VERSION ""

NS_ :

BS_:

BU_: ACS CC TCO SSC RD REX VGW TPMS TECU IC EMS EBS
VAL_TABLE_ FMI 31 "ConditionExists" 19 "Received network data in error" 18 "Below normal (moderately severe)" 17 "Below normal (least severe)" 16 "Above normal (moderately severe)" 15 "Above normal (least severe)" 14 "Special intstructions" 13 "Out of calibration" 12 "Bad intelligent device" 11 "Root cause not known" 10 "Abnormal rate of change" 9 "Abnormal update rate" 8 "Abnormal frequency" 7 "Mechanical system not responding" 6 "Current above normal" 5 "Current below normal" 4 "Voltage below normal" 3 "Voltage above normal" 2 "Data erratic" 1 "Below normal (most severe)" 0 "Above normal (most severe)" ;

BO_ 3221225472 VECTOR__INDEPENDENT_SIG_MSG: 0 Vector__XXX
 SG_ TireTemp : 0|16@1+ (0.03125,-273) [-273|1735] "deg" Vector__XXX
 SG_ TirePress : 0|8@1+ (4,0) [0|1000] "kPa" Vector__XXX
 SG_ SPN5 : 0|16@1+ (1,0) [0|65536] "" Vector__XXX
 SG_ SPN4 : 0|16@1+ (1,0) [0|65536] "" Vector__XXX
 SG_ SPN3 : 0|16@1+ (1,0) [0|65536] "" Vector__XXX
 SG_ SPN2 : 0|16@1+ (1,0) [0|65536] "" Vector__XXX
 SG_ FailureModeIdentifier5 : 0|5@1+ (1,0) [0|0] "" Vector__XXX
 SG_ FailureModeIdentifier4 : 0|5@1+ (1,0) [0|0] "" Vector__XXX
 SG_ FlashRedStopLamp : 0|2@1+ (1,0) [0|3] "" Vector__XXX
 SG_ FlashProtectLamp : 0|2@1+ (1,0) [0|3] "" Vector__XXX
 SG_ FlashMalfuncIndicatorLamp : 0|2@1+ (1,0) [0|3] "" Vector__XXX
 SG_ FlashAmberWarningLamp : 0|2@1+ (1,0) [0|3] "" Vector__XXX
 SG_ FailureModeIdentifier3 : 0|5@1+ (1,0) [0|0] "" Vector__XXX
 SG_ FailureModeIdentifier2 : 0|5@1+ (1,0) [0|0] "" Vector__XXX
 SG_ SPNConversionMethod5 : 0|1@1+ (1,0) [0|1] "" Vector__XXX
 SG_ SPNConversionMethod4 : 0|1@1+ (1,0) [0|1] "" Vector__XXX
 SG_ SPNConversionMethod3 : 0|1@1+ (1,0) [0|1] "" Vector__XXX
 SG_ SPNConversionMethod2 : 0|1@1+ (1,0) [0|1] "" Vector__XXX
 SG_ SPNConversionMethod1 : 0|1@1+ (1,0) [0|1] "" Vector__XXX
 SG_ FailureModeIdentifier1 : 0|5@1+ (1,0) [0|0] "" Vector__XXX
 SG_ SPN1 : 0|16@1+ (1,0) [0|65536] "" Vector__XXX
 SG_ MalfunctionIndicatorLampStatus : 0|2@1+ (1,0) [0|3] "" Vector__XXX
 SG_ RedStopLampState : 0|2@1+ (1,0) [0|3] "" Vector__XXX
 SG_ AmberWarningLampStatus : 0|2@1+ (1,0) [0|3] "" Vector__XXX
 SG_ ProtectLampStatus : 0|2@1+ (1,0) [0|3] "" Vector__XXX
 SG_ SPN5High : 0|3@1+ (1,0) [0|7] "" Vector__XXX
 SG_ SPN4High : 0|3@1+ (1,0) [0|7] "" Vector__XXX
 SG_ SPN3High : 0|3@1+ (1,0) [0|7] "" Vector__XXX
 SG_ SPN2High : 0|3@1+ (1,0) [0|7] "" Vector__XXX
 SG_ SPN1High : 0|3@1+ (1,0) [0|7] "" Vector__XXX
 SG_ SPNConversionMethod1 : 0|1@1+ (1,0) [0|1] "" Vector__XXX
 SG_ FailureModeIdentifier1 : 0|5@1+ (1,0) [0|0] "" Vector__XXX
 SG_ SPN1 : 0|16@1+ (1,0) [0|65536] "" Vector__XXX
 SG_ SPN1High : 0|3@1+ (1,0) [0|7] "" Vector__XXX
 SG_ SPNConversionMethod1 : 0|1@1+ (1,0) [0|1] "" Vector__XXX
 SG_ FailureModeIdentifier1 : 0|5@1+ (1,0) [0|0] "" Vector__XXX
 SG_ SPN1 : 0|16@1+ (1,0) [0|65536] "" Vector__XXX
 SG_ SPN1High : 0|3@1+ (1,0) [0|7] "" Vector__XXX
 SG_ SPN5 : 0|16@1+ (1,0) [0|65536] "" Vector__XXX
 SG_ SPN4 : 0|16@1+ (1,0) [0|65536] "" Vector__XXX
 SG_ SPN3 : 0|16@1+ (1,0) [0|65536] "" Vector__XXX
 SG_ SPN2 : 0|16@1+ (1,0) [0|65536] "" Vector__XXX
 SG_ FailureModeIdentifier5 : 0|5@1+ (1,0) [0|0] "" Vector__XXX
 SG_ FailureModeIdentifier4 : 0|5@1+ (1,0) [0|0] "" Vector__XXX
 SG_ SPNConversionMethod1 : 0|1@1+ (1,0) [0|1] "" Vector__XXX
 SG_ FailureModeIdentifier1 : 0|5@1+ (1,0) [0|0] "" Vector__XXX
 SG_ SPN1 : 0|16@1+ (1,0) [0|65536] "" Vector__XXX
 SG_ MalfunctionIndicatorLampStatus : 0|2@1+ (1,0) [0|3] "" Vector__XXX
 SG_ RedStopLampState : 0|2@1+ (1,0) [0|3] "" Vector__XXX
 SG_ AmberWarningLampStatus : 0|2@1+ (1,0) [0|3] "" Vector__XXX
 SG_ ProtectLampStatus : 0|2@1+ (1,0) [0|3] "" Vector__XXX
 SG_ FailureModeIdentifier3 : 0|5@1+ (1,0) [0|0] "" Vector__XXX
 SG_ FlashRedStopLamp : 0|2@1+ (1,0) [0|3] "" Vector__XXX
 SG_ FlashProtectLamp : 0|2@1+ (1,0) [0|3] "" Vector__XXX
 SG_ FlashMalfuncIndicatorLamp : 0|2@1+ (1,0) [0|3] "" Vector__XXX
 SG_ FlashAmberWarningLamp : 0|2@1+ (1,0) [0|3] "" Vector__XXX
 SG_ FailureModeIdentifier2 : 0|5@1+ (1,0) [0|0] "" Vector__XXX
 SG_ SPNConversionMethod5 : 0|1@1+ (1,0) [0|1] "" Vector__XXX
 SG_ SPNConversionMethod4 : 0|1@1+ (1,0) [0|1] "" Vector__XXX
 SG_ SPNConversionMethod3 : 0|1@1+ (1,0) [0|1] "" Vector__XXX
 SG_ SPNConversionMethod2 : 0|1@1+ (1,0) [0|1] "" Vector__XXX
 SG_ SPN5High : 0|3@1+ (1,0) [0|7] "" Vector__XXX
 SG_ SPN4High : 0|3@1+ (1,0) [0|7] "" Vector__XXX
 SG_ SPN3High : 0|3@1+ (1,0) [0|7] "" Vector__XXX
 SG_ SPN2High : 0|3@1+ (1,0) [0|7] "" Vector__XXX
 SG_ SPN1High : 0|3@1+ (1,0) [0|7] "" Vector__XXX
 SG_ SPN5 : 0|16@1+ (1,0) [0|65536] "" Vector__XXX
 SG_ SPN4 : 0|16@1+ (1,0) [0|65536] "" Vector__XXX
 SG_ SPN3 : 0|16@1+ (1,0) [0|65536] "" Vector__XXX
 SG_ SPN2 : 0|16@1+ (1,0) [0|65536] "" Vector__XXX
 SG_ FlashRedStopLamp : 0|2@1+ (1,0) [0|3] "" Vector__XXX
 SG_ FlashProtectLamp : 0|2@1+ (1,0) [0|3] "" Vector__XXX
 SG_ FailureModeIdentifier5 : 0|5@1+ (1,0) [0|0] "" Vector__XXX
 SG_ FailureModeIdentifier4 : 0|5@1+ (1,0) [0|0] "" Vector__XXX
 SG_ FailureModeIdentifier3 : 0|5@1+ (1,0) [0|0] "" Vector__XXX
 SG_ SPNConversionMethod1 : 0|1@1+ (1,0) [0|1] "" Vector__XXX
 SG_ FailureModeIdentifier1 : 0|5@1+ (1,0) [0|0] "" Vector__XXX
 SG_ MalfunctionIndicatorLampStatus : 0|2@1+ (1,0) [0|3] "" Vector__XXX
 SG_ RedStopLampState : 0|2@1+ (1,0) [0|3] "" Vector__XXX
 SG_ AmberWarningLampStatus : 0|2@1+ (1,0) [0|3] "" Vector__XXX
 SG_ ProtectLampStatus : 0|2@1+ (1,0) [0|3] "" Vector__XXX
 SG_ FlashMalfuncIndicatorLamp : 0|2@1+ (1,0) [0|3] "" Vector__XXX
 SG_ FlashAmberWarningLamp : 0|2@1+ (1,0) [0|3] "" Vector__XXX
 SG_ FailureModeIdentifier2 : 0|5@1+ (1,0) [0|0] "" Vector__XXX
 SG_ SPNConversionMethod5 : 0|1@1+ (1,0) [0|1] "" Vector__XXX
 SG_ SPNConversionMethod4 : 0|1@1+ (1,0) [0|1] "" Vector__XXX
 SG_ SPNConversionMethod3 : 0|1@1+ (1,0) [0|1] "" Vector__XXX
 SG_ SPNConversionMethod2 : 0|1@1+ (1,0) [0|1] "" Vector__XXX
 SG_ SPN5High : 0|3@1+ (1,0) [0|7] "" Vector__XXX
 SG_ SPN4High : 0|3@1+ (1,0) [0|7] "" Vector__XXX
 SG_ SPN3High : 0|3@1+ (1,0) [0|7] "" Vector__XXX
 SG_ SPN2High : 0|3@1+ (1,0) [0|7] "" Vector__XXX
 SG_ SPN1High : 0|3@1+ (1,0) [0|7] "" Vector__XXX
 SG_ SPN5 : 0|16@1+ (1,0) [0|65536] "" Vector__XXX
 SG_ SPN4 : 0|16@1+ (1,0) [0|65536] "" Vector__XXX
 SG_ SPN3 : 0|16@1+ (1,0) [0|65536] "" Vector__XXX
 SG_ SPN2 : 0|16@1+ (1,0) [0|65536] "" Vector__XXX
 SG_ FailureModeIdentifier5 : 0|5@1+ (1,0) [0|0] "" Vector__XXX
 SG_ FailureModeIdentifier4 : 0|5@1+ (1,0) [0|0] "" Vector__XXX
 SG_ FailureModeIdentifier3 : 0|5@1+ (1,0) [0|0] "" Vector__XXX
 SG_ SPNConversionMethod1 : 0|1@1+ (1,0) [0|1] "" Vector__XXX
 SG_ FailureModeIdentifier1 : 0|5@1+ (1,0) [0|0] "" Vector__XXX
 SG_ SPN1 : 0|16@1+ (1,0) [0|65536] "" Vector__XXX
 SG_ FailureModeIdentifier2 : 0|5@1+ (1,0) [0|0] "" Vector__XXX
 SG_ SPNConversionMethod5 : 0|1@1+ (1,0) [0|1] "" Vector__XXX
 SG_ SPNConversionMethod4 : 0|1@1+ (1,0) [0|1] "" Vector__XXX
 SG_ SPNConversionMethod3 : 0|1@1+ (1,0) [0|1] "" Vector__XXX
 SG_ SPNConversionMethod2 : 0|1@1+ (1,0) [0|1] "" Vector__XXX
 SG_ SPN5High : 0|3@1+ (1,0) [0|7] "" Vector__XXX
 SG_ SPN4High : 0|3@1+ (1,0) [0|7] "" Vector__XXX
 SG_ SPN3High : 0|3@1+ (1,0) [0|7] "" Vector__XXX
 SG_ SPN2High : 0|3@1+ (1,0) [0|7] "" Vector__XXX
 SG_ SPN1High : 0|3@1+ (1,0) [0|7] "" Vector__XXX

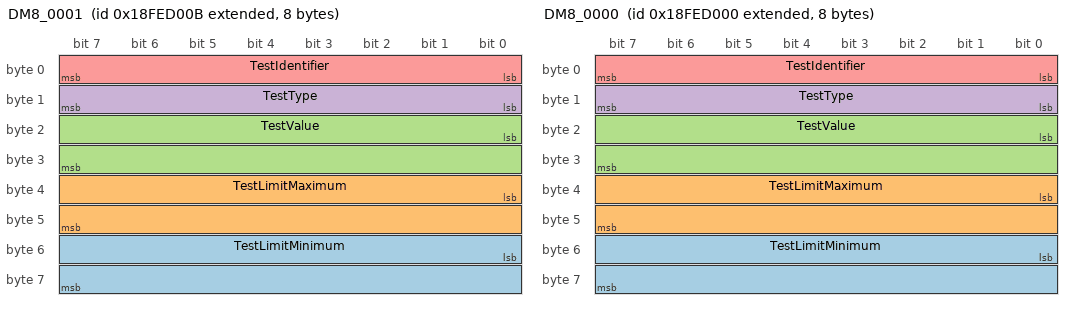
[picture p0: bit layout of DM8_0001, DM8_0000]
BO_ 2566836235 DM8_0001: 8 EBS
 SG_ TestLimitMinimum : 48|16@1+ (1,0) [0|64255] "" Vector__XXX
 SG_ TestLimitMaximum : 32|16@1+ (1,0) [0|64255] "" Vector__XXX
 SG_ TestValue : 16|16@1+ (1,0) [0|64255] "" Vector__XXX
 SG_ TestType : 8|8@1+ (1,0) [1|64] "" Vector__XXX
 SG_ TestIdentifier : 0|8@1+ (1,0) [1|64] "" Vector__XXX

BO_ 2566836224 DM8_0000: 8 EMS
 SG_ TestLimitMinimum : 48|16@1+ (1,0) [0|64255] "" Vector__XXX
 SG_ TestLimitMaximum : 32|16@1+ (1,0) [0|64255] "" Vector__XXX
 SG_ TestValue : 16|16@1+ (1,0) [0|64255] "" Vector__XXX
 SG_ TestType : 8|8@1+ (1,0) [1|64] "" Vector__XXX
 SG_ TestIdentifier : 0|8@1+ (1,0) [1|64] "" Vector__XXX

BO_ 2560949771 DM30_0001: 12 EBS
 SG_ TestLimitMinimum : 80|16@1+ (1,0) [0|64255] "" Vector__XXX
 SG_ TestLimitMaximum : 64|16@1+ (1,0) [0|64255] "" Vector__XXX
 SG_ TestValue : 48|16@1+ (1,0) [0|64255] "" Vector__XXX
 SG_ SlotId : 32|16@1+ (1,0) [0|64255] "" Vector__XXX
 SG_ TestIdentifier : 0|8@1+ (1,0) [1|64] "" Vector__XXX
 SG_ FailureModeIdentifier1 : 24|5@1+ (1,0) [0|0] "" Vector__XXX
 SG_ SPN1High : 29|3@1+ (1,0) [0|7] "" Vector__XXX
 SG_ SPN1 : 8|16@1+ (1,0) [0|65536] "" Vector__XXX

BO_ 2560949760 DM30_0000: 12 EMS
 SG_ TestLimitMinimum : 80|16@1+ (1,0) [0|64255] "" Vector__XXX
 SG_ TestLimitMaximum : 64|16@1+ (1,0) [0|64255] "" Vector__XXX
 SG_ TestValue : 48|16@1+ (1,0) [0|64255] "" Vector__XXX
 SG_ SlotId : 32|16@1+ (1,0) [0|64255] "" Vector__XXX
 SG_ TestIdentifier : 0|8@1+ (1,0) [1|64] "" Vector__XXX
 SG_ FailureModeIdentifier1 : 24|5@1+ (1,0) [0|0] "" Vector__XXX
 SG_ SPN1High : 29|3@1+ (1,0) [0|7] "" Vector__XXX
 SG_ SPN1 : 8|16@1+ (1,0) [0|65536] "" Vector__XXX

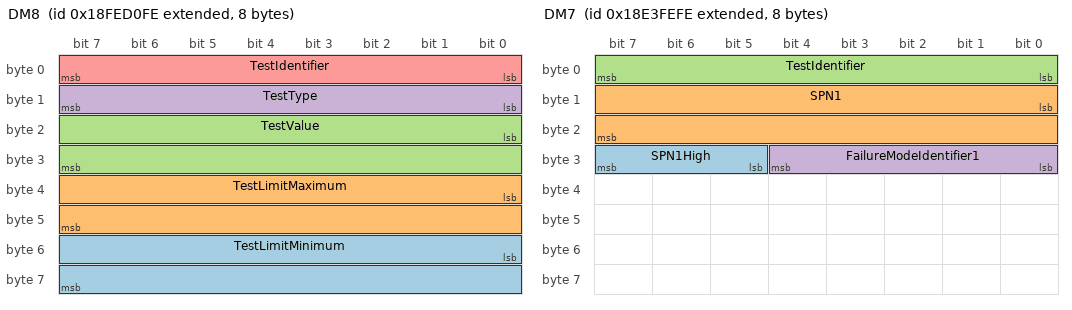
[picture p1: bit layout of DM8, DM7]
BO_ 2566836478 DM8: 8 Vector__XXX
 SG_ TestLimitMinimum : 48|16@1+ (1,0) [0|64255] "" Vector__XXX
 SG_ TestLimitMaximum : 32|16@1+ (1,0) [0|64255] "" Vector__XXX
 SG_ TestValue : 16|16@1+ (1,0) [0|64255] "" Vector__XXX
 SG_ TestType : 8|8@1+ (1,0) [1|64] "" Vector__XXX
 SG_ TestIdentifier : 0|8@1+ (1,0) [1|64] "" Vector__XXX

BO_ 2565078782 DM7: 8 Vector__XXX
 SG_ SPN1High : 29|3@1+ (1,0) [0|7] "" Vector__XXX
 SG_ SPN1 : 8|16@1+ (1,0) [0|65536] "" Vector__XXX
 SG_ TestIdentifier : 0|8@1+ (1,0) [1|64] "" Vector__XXX
 SG_ FailureModeIdentifier1 : 24|5@1+ (1,0) [0|0] "" Vector__XXX

BO_ 2560950014 DM30: 12 Vector__XXX
 SG_ TestLimitMinimum : 80|16@1+ (1,0) [0|64255] "" Vector__XXX
 SG_ TestLimitMaximum : 64|16@1+ (1,0) [0|64255] "" Vector__XXX
 SG_ TestValue : 48|16@1+ (1,0) [0|64255] "" Vector__XXX
 SG_ SlotId : 32|16@1+ (1,0) [0|64255] "" Vector__XXX
 SG_ TestIdentifier : 0|8@1+ (1,0) [1|64] "" Vector__XXX
 SG_ FailureModeIdentifier1 : 24|5@1+ (1,0) [0|0] "" Vector__XXX
 SG_ SPN1High : 29|3@1+ (1,0) [0|7] "" Vector__XXX
 SG_ SPN1 : 8|16@1+ (1,0) [0|65536] "" Vector__XXX

BO_ 2348941054 TC1: 8 Vector__XXX
 SG_ TrnsShftSlctorDisplayModeSwitch : 54|2@1+ (1,0) [0|3] ""  TECU
 SG_ TransMode4 : 46|2@1+ (1,0) [0|3] ""  TECU
 SG_ TransMode3 : 44|2@1+ (1,0) [0|3] ""  TECU
 SG_ TransMode2 : 42|2@1+ (1,0) [0|3] ""  TECU
 SG_ TransMode1 : 40|2@1+ (1,0) [0|3] ""  TECU
 SG_ DisengageDiffLockRqCentralRear : 36|2@1+ (1,0) [0|3] ""  TECU
 SG_ DisengageDiffLockRqCentralFront : 34|2@1+ (1,0) [0|3] ""  TECU
 SG_ DisengageDiffLockRqCentral : 32|2@1+ (1,0) [0|3] ""  TECU
 SG_ DisengageDiffLockRqRearAxle2 : 30|2@1+ (1,0) [0|3] ""  TECU
 SG_ DisengageDiffLockRqRearAxle1 : 28|2@1+ (1,0) [0|3] ""  TECU
 SG_ DisengageDiffLockRqFrontAxle2 : 26|2@1+ (1,0) [0|3] ""  TECU
 SG_ DisengageDiffLockRqFrontAxle1 : 24|2@1+ (1,0) [0|3] ""  TECU
 SG_ TransRqedGear : 16|8@1+ (1,-125) [-125|125] ""  TECU
 SG_ RqedPercentClutchSlip : 8|8@1+ (0.4,0) [0|100] "%"  TECU
 SG_ DisengageDrivelineRq : 4|2@1+ (1,0) [0|3] ""  TECU
 SG_ TorqueConverterLockupDisableRq : 2|2@1+ (1,0) [0|3] ""  TECU
 SG_ TransGearShiftInhibitRq : 0|2@1+ (1,0) [0|3] ""  TECU

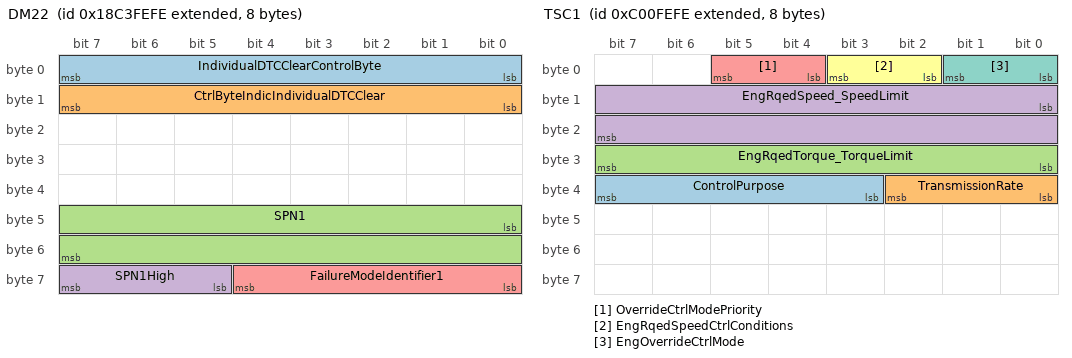
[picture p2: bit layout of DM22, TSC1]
BO_ 2562981630 DM22: 8 Vector__XXX
 SG_ IndividualDTCClearControlByte : 0|8@1+ (1,0) [0|255] "" Vector__XXX
 SG_ CtrlByteIndicIndividualDTCClear : 8|8@1+ (1,0) [0|255] "" Vector__XXX
 SG_ SPN1 : 40|16@1+ (1,0) [0|65536] "" Vector__XXX
 SG_ SPN1High : 61|3@1+ (1,0) [0|7] "" Vector__XXX
 SG_ FailureModeIdentifier1 : 56|5@1+ (1,0) [0|0] "" Vector__XXX

BO_ 2684354558 CAPL_MSG: 1785 Vector__XXX

BO_ 2348875518 TSC1: 8 Vector__XXX
 SG_ ControlPurpose : 35|5@1+ (1,0) [0|31] "" Vector__XXX
 SG_ TransmissionRate : 32|3@1+ (1,0) [0|7] "" Vector__XXX
 SG_ EngRqedTorque_TorqueLimit : 24|8@1+ (1,-125) [-125|125] "%" Vector__XXX
 SG_ EngRqedSpeed_SpeedLimit : 8|16@1+ (0.125,0) [0|8031.875] "rpm" Vector__XXX
 SG_ OverrideCtrlModePriority : 4|2@1+ (1,0) [0|3] "" Vector__XXX
 SG_ EngRqedSpeedCtrlConditions : 2|2@1+ (1,0) [0|3] "" Vector__XXX
 SG_ EngOverrideCtrlMode : 0|2@1+ (1,0) [0|3] "" Vector__XXX

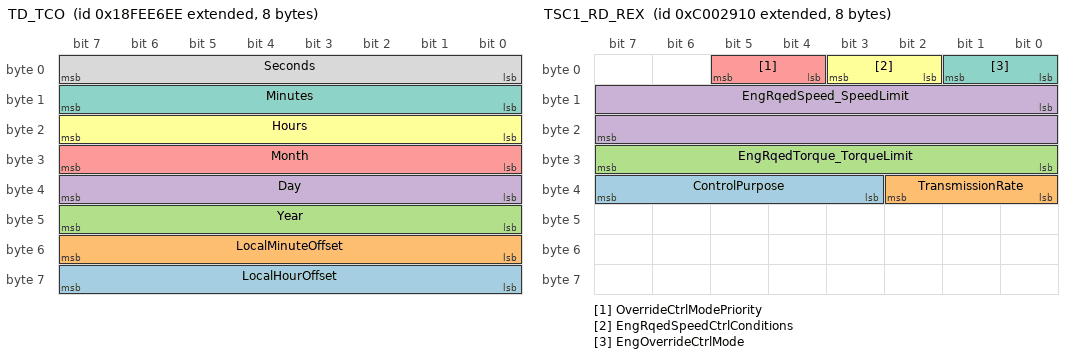
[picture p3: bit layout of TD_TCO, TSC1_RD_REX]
BO_ 2566842094 TD_TCO: 8 TCO
 SG_ LocalHourOffset : 56|8@1+ (1,-125) [-125|125] "hr" Vector__XXX
 SG_ LocalMinuteOffset : 48|8@1+ (1,-125) [-125|125] "mins" Vector__XXX
 SG_ Year : 40|8@1+ (1,1985) [1985|2235] "years" Vector__XXX
 SG_ Day : 32|8@1+ (0.25,0) [0|62.5] "days" Vector__XXX
 SG_ Month : 24|8@1+ (1,0) [0|250] "months" Vector__XXX
 SG_ Hours : 16|8@1+ (1,0) [0|250] "hr" Vector__XXX
 SG_ Minutes : 8|8@1+ (1,0) [0|250] "mins" Vector__XXX
 SG_ Seconds : 0|8@1+ (0.25,0) [0|62.5] "s" Vector__XXX

BO_ 2348820752 TSC1_RD_REX: 8 RD
 SG_ ControlPurpose : 35|5@1+ (1,0) [0|31] ""  REX
 SG_ TransmissionRate : 32|3@1+ (1,0) [0|7] "" Vector__XXX
 SG_ EngRqedTorque_TorqueLimit : 24|8@1+ (1,-125) [-125|125] "%"  REX
 SG_ EngRqedSpeed_SpeedLimit : 8|16@1+ (0.125,0) [0|8031.875] "rpm" Vector__XXX
 SG_ OverrideCtrlModePriority : 4|2@1+ (1,0) [0|3] "" Vector__XXX
 SG_ EngRqedSpeedCtrlConditions : 2|2@1+ (1,0) [0|3] "" Vector__XXX
 SG_ EngOverrideCtrlMode : 0|2@1+ (1,0) [0|3] ""  REX

BO_ 2566840592 RC_RD: 19 RD
 SG_ PercentTorqueAtPeakTorquePoint5 : 144|8@1+ (1,-125) [-125|125] "%" Vector__XXX
 SG_ ReferenceRetarderTorque : 128|16@1+ (1,0) [0|64255] "Nm" Vector__XXX
 SG_ RetarderSpeedAtPeakTorquePoint5 : 112|16@1+ (0.125,0) [0|8031.875] "rpm" Vector__XXX
 SG_ PercentTorqueAtPoint4 : 104|8@1+ (1,-125) [-125|125] "%" Vector__XXX
 SG_ RetarderSpeedAtPoint4 : 88|16@1+ (0.125,0) [0|8031.875] "rpm" Vector__XXX
 SG_ PercentTorqueAtPoint3 : 80|8@1+ (1,-125) [-125|125] "%" Vector__XXX
 SG_ RetarderSpeedAtPoint3 : 64|16@1+ (0.125,0) [0|8031.875] "rpm" Vector__XXX
 SG_ PercentTorqueAtMaxSpeedPoint2 : 56|8@1+ (1,-125) [-125|125] "%" Vector__XXX
 SG_ MaxRetarderSpeedPoint2 : 40|16@1+ (0.125,0) [0|8031.875] "rpm" Vector__XXX
 SG_ PercentTorqueAtIdlePoint1 : 32|8@1+ (1,-125) [-125|125] "%" Vector__XXX
 SG_ RetarderSpeedAtIdlePoint1 : 16|16@1+ (0.125,0) [0|8031.875] "rpm" Vector__XXX
 SG_ RetarderCtrlMethod : 8|8@1+ (1,0) [0|250] "steps" Vector__XXX
 SG_ RetarderLocation : 4|4@1+ (1,0) [0|15] "" Vector__XXX
 SG_ RetarderType : 0|4@1+ (1,0) [0|15] "" Vector__XXX

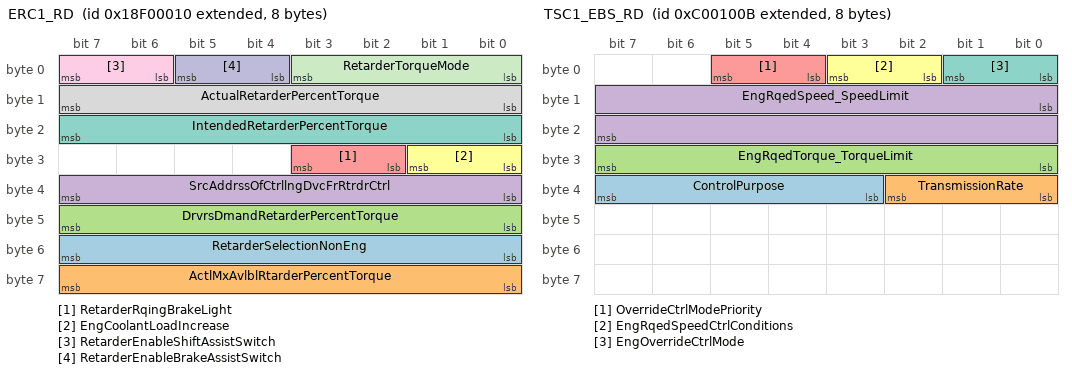
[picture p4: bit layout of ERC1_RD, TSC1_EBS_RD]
BO_ 2565865488 ERC1_RD: 8 RD
 SG_ RetarderSelectionNonEng : 48|8@1+ (0.4,0) [0|100] "%" Vector__XXX
 SG_ ActlMxAvlblRtarderPercentTorque : 56|8@1+ (1,-125) [-125|125] "%" Vector__XXX
 SG_ DrvrsDmandRetarderPercentTorque : 40|8@1+ (1,-125) [-125|125] "%" Vector__XXX
 SG_ SrcAddrssOfCtrllngDvcFrRtrdrCtrl : 32|8@1+ (1,0) [0|255] "" Vector__XXX
 SG_ RetarderRqingBrakeLight : 26|2@1+ (1,0) [0|3] "" Vector__XXX
 SG_ EngCoolantLoadIncrease : 24|2@1+ (1,0) [0|3] "" Vector__XXX
 SG_ IntendedRetarderPercentTorque : 16|8@1+ (1,-125) [-125|125] "%" Vector__XXX
 SG_ ActualRetarderPercentTorque : 8|8@1+ (1,-125) [-125|125] "%"  IC
 SG_ RetarderEnableShiftAssistSwitch : 6|2@1+ (1,0) [0|3] "" Vector__XXX
 SG_ RetarderEnableBrakeAssistSwitch : 4|2@1+ (1,0) [0|3] "" Vector__XXX
 SG_ RetarderTorqueMode : 0|4@1+ (1,0) [0|15] ""  IC

BO_ 2348814347 TSC1_EBS_RD: 8 EBS
 SG_ ControlPurpose : 35|5@1+ (1,0) [0|31] ""  RD
 SG_ TransmissionRate : 32|3@1+ (1,0) [0|7] "" Vector__XXX
 SG_ EngRqedTorque_TorqueLimit : 24|8@1+ (1,-125) [-125|125] "%"  RD
 SG_ EngRqedSpeed_SpeedLimit : 8|16@1+ (0.125,0) [0|8031.875] "rpm"  RD
 SG_ OverrideCtrlModePriority : 4|2@1+ (1,0) [0|3] ""  RD
 SG_ EngRqedSpeedCtrlConditions : 2|2@1+ (1,0) [0|3] "" Vector__XXX
 SG_ EngOverrideCtrlMode : 0|2@1+ (1,0) [0|3] ""  RD

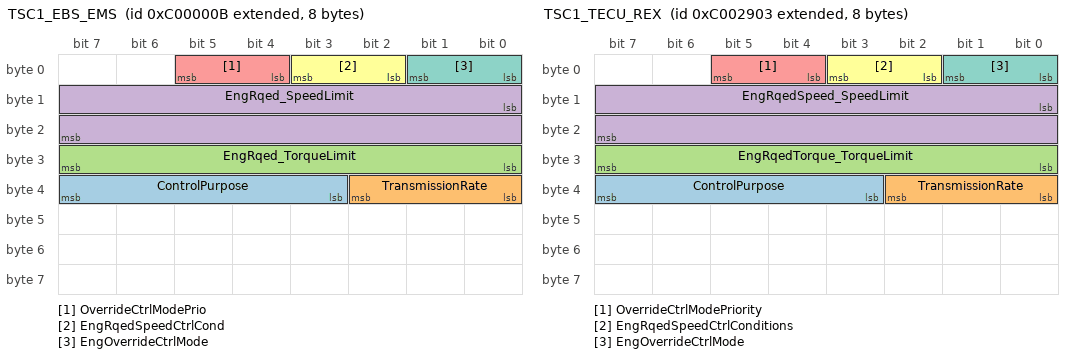
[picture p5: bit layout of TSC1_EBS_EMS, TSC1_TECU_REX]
BO_ 2348810251 TSC1_EBS_EMS: 8 EBS
 SG_ ControlPurpose : 35|5@1+ (1,0) [0|31] ""  EMS
 SG_ TransmissionRate : 32|3@1+ (1,0) [0|7] "" Vector__XXX
 SG_ EngRqed_TorqueLimit : 24|8@1+ (1,-125) [-125|125] "%"  EMS
 SG_ EngRqed_SpeedLimit : 8|16@1+ (0.125,0) [0|8031.875] "rpm"  EMS
 SG_ OverrideCtrlModePrio : 4|2@1+ (1,0) [0|3] ""  EMS
 SG_ EngRqedSpeedCtrlCond : 2|2@1+ (1,0) [0|3] "" Vector__XXX
 SG_ EngOverrideCtrlMode : 0|2@1+ (1,0) [0|3] ""  EMS

BO_ 2348820739 TSC1_TECU_REX: 8 TECU
 SG_ ControlPurpose : 35|5@1+ (1,0) [0|31] ""  REX
 SG_ TransmissionRate : 32|3@1+ (1,0) [0|7] "" Vector__XXX
 SG_ EngRqedTorque_TorqueLimit : 24|8@1+ (1,-125) [-125|125] "%"  REX
 SG_ EngRqedSpeed_SpeedLimit : 8|16@1+ (0.125,0) [0|8031.875] "rpm" Vector__XXX
 SG_ OverrideCtrlModePriority : 4|2@1+ (1,0) [0|3] ""  REX
 SG_ EngRqedSpeedCtrlConditions : 2|2@1+ (1,0) [0|3] "" Vector__XXX
 SG_ EngOverrideCtrlMode : 0|2@1+ (1,0) [0|3] ""  REX

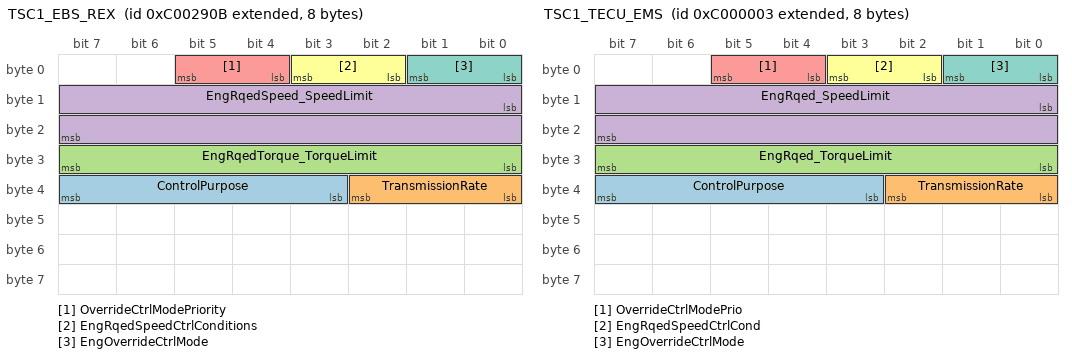
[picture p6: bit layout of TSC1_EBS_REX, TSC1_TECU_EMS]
BO_ 2348820747 TSC1_EBS_REX: 8 EBS
 SG_ ControlPurpose : 35|5@1+ (1,0) [0|31] "" Vector__XXX
 SG_ TransmissionRate : 32|3@1+ (1,0) [0|7] "" Vector__XXX
 SG_ EngRqedTorque_TorqueLimit : 24|8@1+ (1,-125) [-125|125] "%"  REX
 SG_ EngRqedSpeed_SpeedLimit : 8|16@1+ (0.125,0) [0|8031.875] "rpm" Vector__XXX
 SG_ OverrideCtrlModePriority : 4|2@1+ (1,0) [0|3] ""  REX
 SG_ EngRqedSpeedCtrlConditions : 2|2@1+ (1,0) [0|3] "" Vector__XXX
 SG_ EngOverrideCtrlMode : 0|2@1+ (1,0) [0|3] ""  REX

BO_ 2348810243 TSC1_TECU_EMS: 8 TECU
 SG_ ControlPurpose : 35|5@1+ (1,0) [0|31] ""  EMS
 SG_ TransmissionRate : 32|3@1+ (1,0) [0|7] ""  EMS
 SG_ EngRqed_TorqueLimit : 24|8@1+ (1,-125) [-125|125] "%"  EMS
 SG_ EngRqed_SpeedLimit : 8|16@1+ (0.125,0) [0|8031.875] "rpm"  EMS
 SG_ OverrideCtrlModePrio : 4|2@1+ (1,0) [0|3] ""  EMS
 SG_ EngRqedSpeedCtrlCond : 2|2@1+ (1,0) [0|3] ""  EMS
 SG_ EngOverrideCtrlMode : 0|2@1+ (1,0) [0|3] ""  EMS

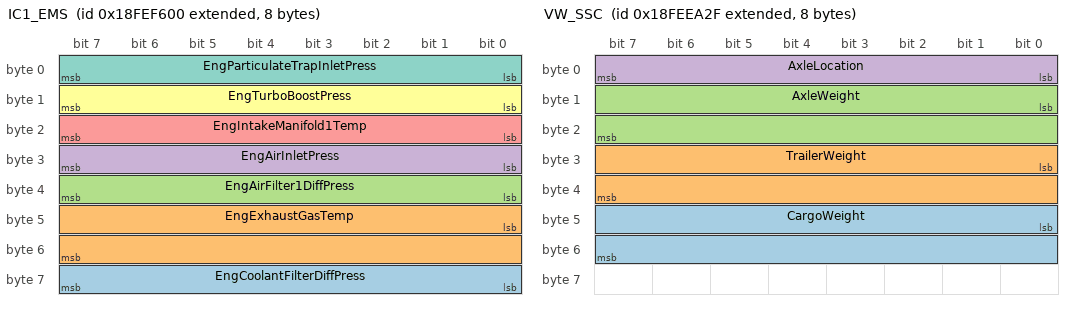
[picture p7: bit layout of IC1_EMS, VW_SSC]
BO_ 2566845952 IC1_EMS: 8 EMS
 SG_ EngCoolantFilterDiffPress : 56|8@1+ (0.5,0) [0|125] "kPa" Vector__XXX
 SG_ EngExhaustGasTemp : 40|16@1+ (0.03125,-273) [-273|1735] "deg" Vector__XXX
 SG_ EngAirFilter1DiffPress : 32|8@1+ (0.05,0) [0|12.5] "kPa" Vector__XXX
 SG_ EngAirInletPress : 24|8@1+ (2,0) [0|500] "kPa" Vector__XXX
 SG_ EngIntakeManifold1Temp : 16|8@1+ (1,-40) [-40|210] "deg" Vector__XXX
 SG_ EngTurboBoostPress : 8|8@1+ (2,0) [0|500] "kPa"  IC
 SG_ EngParticulateTrapInletPress : 0|8@1+ (0.5,0) [0|125] "kPa" Vector__XXX

BO_ 2566841600 HOURS_EMS: 8 EMS
 SG_ EngTotalRevolutions : 32|32@1+ (1000,0) [0|4211081215000] "r" Vector__XXX
 SG_ EngTotalHoursOfOperation : 0|32@1+ (0.05,0) [0|210554060.75] "hr"  IC,VGW

BO_ 2566842927 VW_SSC: 8 SSC
 SG_ CargoWeight : 40|16@1+ (2,0) [0|128510] "kg" Vector__XXX
 SG_ TrailerWeight : 24|16@1+ (2,0) [0|128510] "kg" Vector__XXX
 SG_ AxleWeight : 8|16@1+ (0.5,0) [0|32127.5] "kg"  VGW
 SG_ AxleLocation : 0|8@1+ (1,0) [0|255] ""  VGW

BO_ 2566843392 VI_EMS: 8 EMS
 SG_ VehicleIdentificationNumber : 0|8@1+ (1,0) [0|255] "" Vector__XXX

BO_ 2566832384 VDHR_EMS: 8 EMS
 SG_ HighResolutionTripDistance : 32|32@1+ (5,0) [0|21055406] "km" Vector__XXX
 SG_ HghRslutionTotalVehicleDistance : 0|32@1+ (5,0) [0|21055406] "km"  VGW

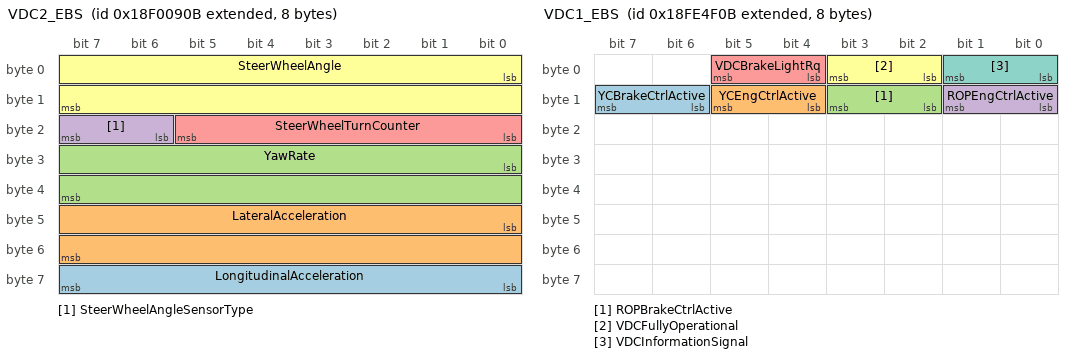
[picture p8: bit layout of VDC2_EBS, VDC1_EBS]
BO_ 2565867787 VDC2_EBS: 8 EBS
 SG_ LongitudinalAcceleration : 56|8@1+ (0.1,-12.5) [-12.5|12.5] "m/s²" Vector__XXX
 SG_ LateralAcceleration : 40|16@1+ (0.000488281,-15.687) [-15.687|15.687] "m/s²" Vector__XXX
 SG_ YawRate : 24|16@1+ (0.00012207,-3.92) [-3.92|3.92] "rad/s" Vector__XXX
 SG_ SteerWheelAngleSensorType : 22|2@1+ (1,0) [0|3] "" Vector__XXX
 SG_ SteerWheelTurnCounter : 16|6@1+ (1,-32) [-32|29] "turns" Vector__XXX
 SG_ SteerWheelAngle : 0|16@1+ (0.000976563,-31.374) [-31.374|31.374] "rad" Vector__XXX

BO_ 2566803211 VDC1_EBS: 8 EBS
 SG_ YCBrakeCtrlActive : 14|2@1+ (1,0) [0|3] ""  IC
 SG_ YCEngCtrlActive : 12|2@1+ (1,0) [0|3] ""  IC
 SG_ ROPBrakeCtrlActive : 10|2@1+ (1,0) [0|3] ""  IC
 SG_ ROPEngCtrlActive : 8|2@1+ (1,0) [0|3] ""  IC
 SG_ VDCBrakeLightRq : 4|2@1+ (1,0) [0|3] "" Vector__XXX
 SG_ VDCFullyOperational : 2|2@1+ (1,0) [0|3] ""  IC
 SG_ VDCInformationSignal : 0|2@1+ (1,0) [0|3] "" Vector__XXX

BO_ 2566840320 VD_EMS: 8 EMS
 SG_ TotalVehicleDistance : 32|32@1+ (0.125,0) [0|526385151.9] "km" Vector__XXX
 SG_ TripDistance : 0|32@1+ (0.125,0) [0|526385151.9] "km" Vector__XXX

BO_ 2561605374 TPRS: 8 Vector__XXX
 SG_ ReferenceTirePressSetting : 8|8@1+ (8,0) [0|2000] "kPa"  TPMS
 SG_ TireLocation : 0|8@1+ (1,0) [0|255] ""  TPMS

BO_ 2566764851 TPRI_TPMS: 8 TPMS
 SG_ ReferenceTirePress : 8|8@1+ (8,0) [0|2000] "kPa" Vector__XXX
 SG_ TireLocation : 0|8@1+ (1,0) [0|255] "" Vector__XXX

BO_ 2566845491 TIRE_TPMS: 8 TPMS
 SG_ TireTemp_21 m33 : 16|16@1+ (0.03125,-273) [-273|1735] "deg" Vector__XXX
 SG_ TireTemp_20 m32 : 16|16@1+ (0.03125,-273) [-273|1735] "deg" Vector__XXX
 SG_ TireTemp_11 m17 : 16|16@1+ (0.03125,-273) [-273|1735] "deg" Vector__XXX
 SG_ TireTemp_10 m16 : 16|16@1+ (0.03125,-273) [-273|1735] "deg" Vector__XXX
 SG_ TireTemp_01 m1 : 16|16@1+ (0.03125,-273) [-273|1735] "deg" Vector__XXX
 SG_ TireTemp_00 m0 : 16|16@1+ (0.03125,-273) [-273|1735] "deg" Vector__XXX
 SG_ TirePressThresholdDetection_21 m33 : 61|3@1+ (1,0) [0|7] "" Vector__XXX
 SG_ TirePressThresholdDetection_20 m32 : 61|3@1+ (1,0) [0|7] "" Vector__XXX
 SG_ TirePressThresholdDetection_11 m17 : 61|3@1+ (1,0) [0|7] "" Vector__XXX
 SG_ TirePressThresholdDetection_10 m16 : 61|3@1+ (1,0) [0|7] "" Vector__XXX
 SG_ TirePressThresholdDetection_01 m1 : 61|3@1+ (1,0) [0|7] "" Vector__XXX
 SG_ TirePressThresholdDetection_00 m0 : 61|3@1+ (1,0) [0|7] "" Vector__XXX
 SG_ TirePress_21 m33 : 8|8@1+ (4,0) [0|1000] "kPa" Vector__XXX
 SG_ TirePress_20 m32 : 8|8@1+ (4,0) [0|1000] "kPa" Vector__XXX
 SG_ TirePress_11 m17 : 8|8@1+ (4,0) [0|1000] "kPa" Vector__XXX
 SG_ TirePress_10 m16 : 8|8@1+ (4,0) [0|1000] "kPa" Vector__XXX
 SG_ TirePress_01 m1 : 8|8@1+ (4,0) [0|1000] "kPa" Vector__XXX
 SG_ TirePress_00 m0 : 8|8@1+ (4,0) [0|1000] "kPa" Vector__XXX
 SG_ TireAirLeakageRate_21 m33 : 40|16@1+ (0.1,0) [0|6425.5] "Pa/s" Vector__XXX
 SG_ TireAirLeakageRate_20 m32 : 40|16@1+ (0.1,0) [0|6425.5] "Pa/s" Vector__XXX
 SG_ TireAirLeakageRate_11 m17 : 40|16@1+ (0.1,0) [0|6425.5] "Pa/s" Vector__XXX
 SG_ TireAirLeakageRate_10 m16 : 40|16@1+ (0.1,0) [0|6425.5] "Pa/s" Vector__XXX
 SG_ TireAirLeakageRate_01 m1 : 40|16@1+ (0.1,0) [0|6425.5] "Pa/s" Vector__XXX
 SG_ TireAirLeakageRate_00 m0 : 40|16@1+ (0.1,0) [0|6425.5] "Pa/s" Vector__XXX
 SG_ CTIWheelSensorStatus_21 m33 : 32|2@1+ (1,0) [0|3] "" Vector__XXX
 SG_ CTIWheelSensorStatus_20 m32 : 32|2@1+ (1,0) [0|3] "" Vector__XXX
 SG_ CTIWheelSensorStatus_11 m17 : 32|2@1+ (1,0) [0|3] "" Vector__XXX
 SG_ CTIWheelSensorStatus_10 m16 : 32|2@1+ (1,0) [0|3] "" Vector__XXX
 SG_ CTIWheelSensorStatus_01 m1 : 32|2@1+ (1,0) [0|3] "" Vector__XXX
 SG_ CTIWheelSensorStatus_00 m0 : 32|2@1+ (1,0) [0|3] "" Vector__XXX
 SG_ CTIWheelEndElectricalFault_21 m33 : 36|2@1+ (1,0) [0|3] "" Vector__XXX
 SG_ CTIWheelEndElectricalFault_20 m32 : 36|2@1+ (1,0) [0|3] "" Vector__XXX
 SG_ CTIWheelEndElectricalFault_11 m17 : 36|2@1+ (1,0) [0|3] "" Vector__XXX
 SG_ CTIWheelEndElectricalFault_10 m16 : 36|2@1+ (1,0) [0|3] "" Vector__XXX
 SG_ CTIWheelEndElectricalFault_01 m1 : 36|2@1+ (1,0) [0|3] "" Vector__XXX
 SG_ CTIWheelEndElectricalFault_00 m0 : 36|2@1+ (1,0) [0|3] "" Vector__XXX
 SG_ CTITireStatus_21 m33 : 34|2@1+ (1,0) [0|3] "" Vector__XXX
 SG_ CTITireStatus_20 m32 : 34|2@1+ (1,0) [0|3] "" Vector__XXX
 SG_ CTITireStatus_11 m17 : 34|2@1+ (1,0) [0|3] "" Vector__XXX
 SG_ CTITireStatus_10 m16 : 34|2@1+ (1,0) [0|3] "" Vector__XXX
 SG_ CTITireStatus_01 m1 : 34|2@1+ (1,0) [0|3] "" Vector__XXX
 SG_ CTITireStatus_00 m0 : 34|2@1+ (1,0) [0|3] "" Vector__XXX
 SG_ TireLocation M : 0|8@1+ (1,0) [0|255] "" Vector__XXX

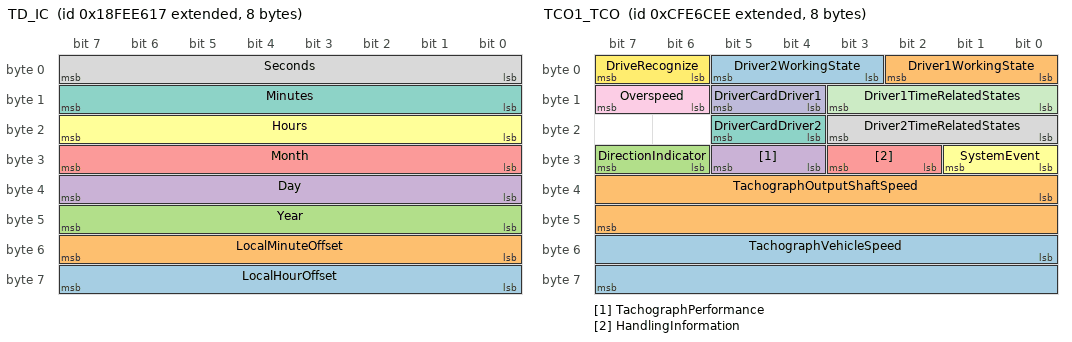
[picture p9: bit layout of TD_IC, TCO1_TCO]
BO_ 2566841879 TD_IC: 8 IC
 SG_ LocalHourOffset : 56|8@1+ (1,-125) [-125|125] "hr" Vector__XXX
 SG_ LocalMinuteOffset : 48|8@1+ (1,-125) [-125|125] "mins" Vector__XXX
 SG_ Year : 40|8@1+ (1,1985) [1985|2235] "years" Vector__XXX
 SG_ Day : 32|8@1+ (0.25,0) [0|62.5] "days" Vector__XXX
 SG_ Month : 24|8@1+ (1,0) [0|250] "months" Vector__XXX
 SG_ Hours : 16|8@1+ (1,0) [0|250] "hr" Vector__XXX
 SG_ Minutes : 8|8@1+ (1,0) [0|250] "mins" Vector__XXX
 SG_ Seconds : 0|8@1+ (0.25,0) [0|62.5] "s" Vector__XXX

BO_ 2365484270 TCO1_TCO: 8 TCO
 SG_ TachographVehicleSpeed : 48|16@1+ (0.00390625,0) [0|250.996] "km/h"  VGW
 SG_ TachographOutputShaftSpeed : 32|16@1+ (0.125,0) [0|8031.875] "rpm" Vector__XXX
 SG_ DirectionIndicator : 30|2@1+ (1,0) [0|3] ""  VGW
 SG_ TachographPerformance : 28|2@1+ (1,0) [0|3] ""  VGW
 SG_ HandlingInformation : 26|2@1+ (1,0) [0|3] ""  VGW
 SG_ SystemEvent : 24|2@1+ (1,0) [0|3] ""  VGW
 SG_ DriverCardDriver2 : 20|2@1+ (1,0) [0|3] ""  VGW
 SG_ Driver2TimeRelatedStates : 16|4@1+ (1,0) [0|15] ""  VGW
 SG_ Overspeed : 14|2@1+ (1,0) [0|3] ""  VGW
 SG_ DriverCardDriver1 : 12|2@1+ (1,0) [0|3] ""  VGW
 SG_ Driver1TimeRelatedStates : 8|4@1+ (1,0) [0|15] ""  VGW
 SG_ DriveRecognize : 6|2@1+ (1,0) [0|3] ""  VGW
 SG_ Driver2WorkingState : 3|3@1+ (1,0) [0|7] ""  VGW
 SG_ Driver1WorkingState : 0|3@1+ (1,0) [0|7] ""  VGW

BO_ 2566802179 TCFG2_TECU: 8 TECU
 SG_ TransTorqueLimit : 0|16@1+ (1,0) [0|64255] "Nm"  EMS

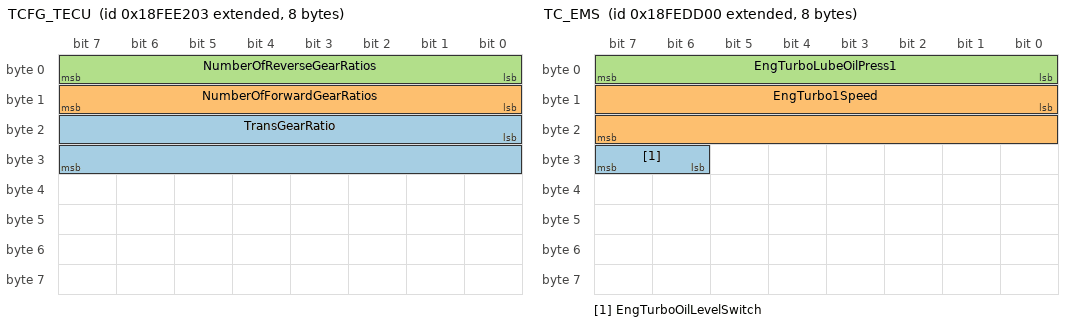
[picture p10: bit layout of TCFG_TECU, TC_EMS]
BO_ 2566840835 TCFG_TECU: 8 TECU
 SG_ TransGearRatio : 16|16@1+ (0.001,0) [0|64.255] "" Vector__XXX
 SG_ NumberOfForwardGearRatios : 8|8@1+ (1,0) [0|250] "" Vector__XXX
 SG_ NumberOfReverseGearRatios : 0|8@1+ (1,0) [0|250] "" Vector__XXX

BO_ 2566839552 TC_EMS: 8 EMS
 SG_ EngTurboOilLevelSwitch : 30|2@1+ (1,0) [0|3] "" Vector__XXX
 SG_ EngTurbo1Speed : 8|16@1+ (4,0) [0|257020] "rpm" Vector__XXX
 SG_ EngTurboLubeOilPress1 : 0|8@1+ (4,0) [0|1000] "kPa" Vector__XXX

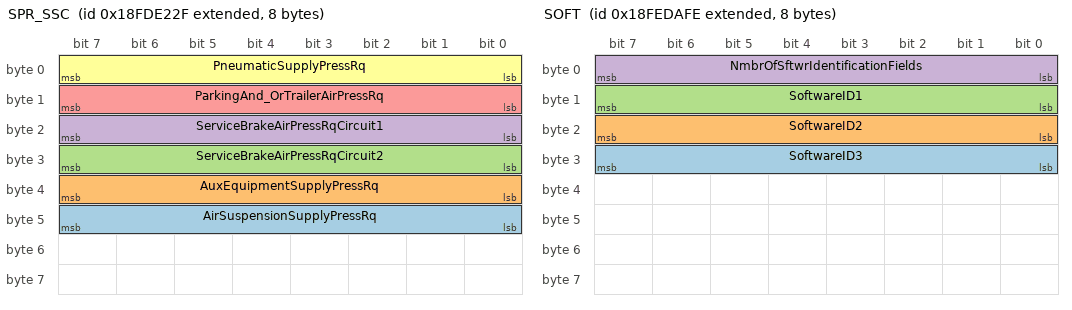
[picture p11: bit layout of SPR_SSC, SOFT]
BO_ 2566775343 SPR_SSC: 8 SSC
 SG_ AirSuspensionSupplyPressRq : 40|8@1+ (8,0) [0|2000] "kPa" Vector__XXX
 SG_ AuxEquipmentSupplyPressRq : 32|8@1+ (8,0) [0|2000] "kPa" Vector__XXX
 SG_ ServiceBrakeAirPressRqCircuit2 : 24|8@1+ (8,0) [0|2000] "kPa" Vector__XXX
 SG_ ServiceBrakeAirPressRqCircuit1 : 16|8@1+ (8,0) [0|2000] "kPa" Vector__XXX
 SG_ ParkingAnd_OrTrailerAirPressRq : 8|8@1+ (8,0) [0|2000] "kPa" Vector__XXX
 SG_ PneumaticSupplyPressRq : 0|8@1+ (8,0) [0|2000] "kPa" Vector__XXX

BO_ 2566839038 SOFT: 8 EMS
 SG_ SoftwareID3 : 24|8@1+ (1,0) [0|255] "" Vector__XXX
 SG_ SoftwareID2 : 16|8@1+ (1,0) [0|255] "" Vector__XXX
 SG_ SoftwareID1 : 8|8@1+ (1,0) [0|255] "" Vector__XXX
 SG_ NmbrOfSftwrIdentificationFields : 0|8@1+ (1,0) [0|250] "steps" Vector__XXX

BO_ 2566841344 SHUTDOW_EMS: 8 EMS
 SG_ EngOverspeedTest : 54|2@1+ (1,0) [0|3] "" Vector__XXX
 SG_ EngAirShutoffCmdStatus : 52|2@1+ (1,0) [0|3] "" Vector__XXX
 SG_ EngAlarmOutputCmdStatus : 50|2@1+ (1,0) [0|3] "" Vector__XXX
 SG_ EngAlarmAcknowledge : 48|2@1+ (1,0) [0|3] "" Vector__XXX
 SG_ EngProtectionSystemConfig : 46|2@1+ (1,0) [0|3] "" Vector__XXX
 SG_ EngProtectionSystemTimerState : 38|2@1+ (1,0) [0|3] "" Vector__XXX
 SG_ EngPrtectionSystemTimerOverride : 36|2@1+ (1,0) [0|3] "" Vector__XXX
 SG_ EngPrtctnSystmApprchingShutdown : 34|2@1+ (1,0) [0|3] "" Vector__XXX
 SG_ EngPrtctionSystemHasShutdownEng : 32|2@1+ (1,0) [0|3] "" Vector__XXX
 SG_ EngWaitToStartLamp : 24|2@1+ (1,0) [0|3] "" Vector__XXX
 SG_ RefrigerantHighPressSwitch : 20|2@1+ (1,0) [0|3] "" Vector__XXX
 SG_ RefrigerantLowPressSwitch : 18|2@1+ (1,0) [0|3] "" Vector__XXX
 SG_ A_CHighPressFanSwitch : 16|2@1+ (1,0) [0|3] "" Vector__XXX
 SG_ EngIdleShutdownTimerFunction : 14|2@1+ (1,0) [0|3] "" Vector__XXX
 SG_ EngIdleShutdownTimerState : 6|2@1+ (1,0) [0|3] "" Vector__XXX
 SG_ EngIdleShutdownTimerOverride : 4|2@1+ (1,0) [0|3] "" Vector__XXX
 SG_ EngIdleShutdownDriverAlertMode : 2|2@1+ (1,0) [0|3] "" Vector__XXX
 SG_ EngIdleShutdownHasShutdownEng : 0|2@1+ (1,0) [0|3] "" Vector__XXX

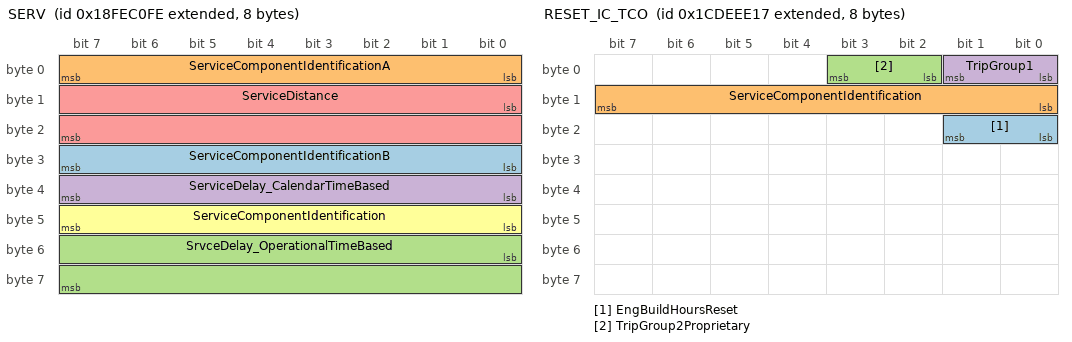
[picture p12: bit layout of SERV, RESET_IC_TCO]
BO_ 2566832382 SERV: 8 Vector__XXX
 SG_ ServiceComponentIdentificationB : 24|8@1+ (1,0) [0|250] "ID" Vector__XXX
 SG_ ServiceComponentIdentificationA : 0|8@1+ (1,0) [0|250] "ID" Vector__XXX
 SG_ SrvceDelay_OperationalTimeBased : 48|16@1+ (1,-31873) [-31873|32128] "hr" Vector__XXX
 SG_ ServiceDelay_CalendarTimeBased : 32|8@1+ (1,-125) [-125|125] "weeks" Vector__XXX
 SG_ ServiceDistance : 8|16@1+ (5,-159365) [-159365|160640] "km"  VGW
 SG_ ServiceComponentIdentification : 40|8@1+ (1,0) [0|250] "ID" Vector__XXX

BO_ 2566847248 RF_RD: 8 RD
 SG_ HydRetarderOilTemp : 8|8@1+ (1,-40) [-40|210] "deg"  IC
 SG_ HydRetarderPress : 0|8@1+ (16,0) [0|4000] "kPa" Vector__XXX

BO_ 2631855639 RESET_IC_TCO: 8 IC
 SG_ EngBuildHoursReset : 16|2@1+ (1,0) [0|3] ""  TCO
 SG_ ServiceComponentIdentification : 8|8@1+ (1,0) [0|250] "ID"  TCO
 SG_ TripGroup2Proprietary : 2|2@1+ (1,0) [0|3] ""  TCO
 SG_ TripGroup1 : 0|2@1+ (1,0) [0|3] ""  TCO

BO_ 2566840617 RC_REX: 19 REX
 SG_ PercentTorqueAtPeakTorquePoint5 : 144|8@1+ (1,-125) [-125|125] "%" Vector__XXX
 SG_ ReferenceRetarderTorque : 128|16@1+ (1,0) [0|64255] "Nm" Vector__XXX
 SG_ RetarderSpeedAtPeakTorquePoint5 : 112|16@1+ (0.125,0) [0|8031.875] "rpm" Vector__XXX
 SG_ PercentTorqueAtPoint4 : 104|8@1+ (1,-125) [-125|125] "%" Vector__XXX
 SG_ RetarderSpeedAtPoint4 : 88|16@1+ (0.125,0) [0|8031.875] "rpm" Vector__XXX
 SG_ PercentTorqueAtPoint3 : 80|8@1+ (1,-125) [-125|125] "%" Vector__XXX
 SG_ RetarderSpeedAtPoint3 : 64|16@1+ (0.125,0) [0|8031.875] "rpm" Vector__XXX
 SG_ PercentTorqueAtMaxSpeedPoint2 : 56|8@1+ (1,-125) [-125|125] "%" Vector__XXX
 SG_ MaxRetarderSpeedPoint2 : 40|16@1+ (0.125,0) [0|8031.875] "rpm" Vector__XXX
 SG_ PercentTorqueAtIdlePoint1 : 32|8@1+ (1,-125) [-125|125] "%" Vector__XXX
 SG_ RetarderSpeedAtIdlePoint1 : 16|16@1+ (0.125,0) [0|8031.875] "rpm" Vector__XXX
 SG_ RetarderCtrlMethod : 8|8@1+ (1,0) [0|250] "steps" Vector__XXX
 SG_ RetarderLocation : 4|4@1+ (1,0) [0|15] "" Vector__XXX
 SG_ RetarderType : 0|4@1+ (1,0) [0|15] "" Vector__XXX

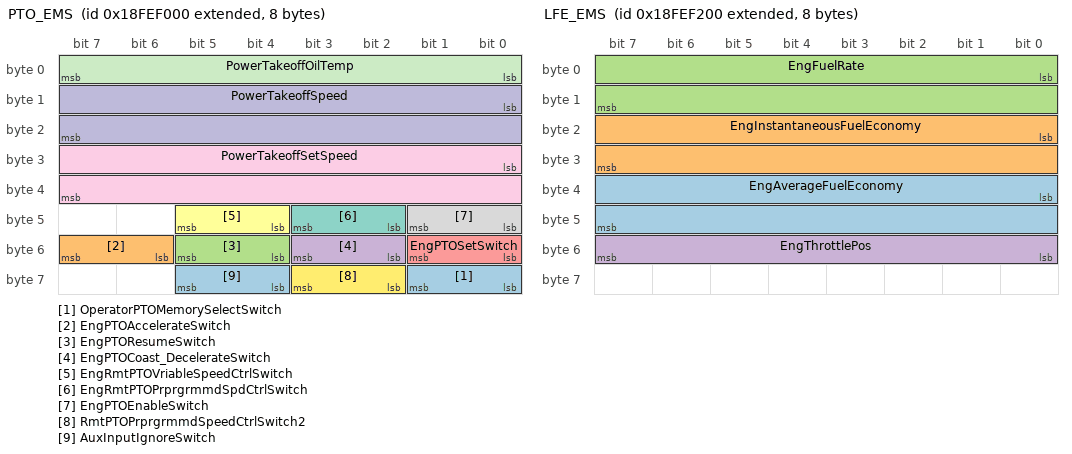
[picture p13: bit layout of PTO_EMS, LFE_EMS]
BO_ 2566844416 PTO_EMS: 8 EMS
 SG_ OperatorPTOMemorySelectSwitch : 56|2@1+ (1,0) [0|3] "" Vector__XXX
 SG_ EngPTOAccelerateSwitch : 54|2@1+ (1,0) [0|3] "" Vector__XXX
 SG_ EngPTOResumeSwitch : 52|2@1+ (1,0) [0|3] "" Vector__XXX
 SG_ EngPTOCoast_DecelerateSwitch : 50|2@1+ (1,0) [0|3] "" Vector__XXX
 SG_ EngPTOSetSwitch : 48|2@1+ (1,0) [0|3] "" Vector__XXX
 SG_ EngRmtPTOVriableSpeedCtrlSwitch : 44|2@1+ (1,0) [0|3] "" Vector__XXX
 SG_ EngRmtPTOPrprgrmmdSpdCtrlSwitch : 42|2@1+ (1,0) [0|3] "" Vector__XXX
 SG_ EngPTOEnableSwitch : 40|2@1+ (1,0) [0|3] "" Vector__XXX
 SG_ PowerTakeoffSetSpeed : 24|16@1+ (0.125,0) [0|8031.875] "rpm" Vector__XXX
 SG_ PowerTakeoffSpeed : 8|16@1+ (0.125,0) [0|8031.875] "rpm" Vector__XXX
 SG_ PowerTakeoffOilTemp : 0|8@1+ (1,-40) [-40|210] "deg" Vector__XXX
 SG_ RmtPTOPrprgrmmdSpeedCtrlSwitch2 : 58|2@1+ (1,0) [0|3] "" Vector__XXX
 SG_ AuxInputIgnoreSwitch : 60|2@1+ (1,0) [0|3] "" Vector__XXX

BO_ 2566844928 LFE_EMS: 8 EMS
 SG_ EngAverageFuelEconomy : 32|16@1+ (0.001953125,0) [0|125.5] "km/L" Vector__XXX
 SG_ EngInstantaneousFuelEconomy : 16|16@1+ (0.001953125,0) [0|125.5] "km/L"  IC
 SG_ EngFuelRate : 0|16@1+ (0.05,0) [0|3212.75] "L/h"  IC
 SG_ EngThrottlePos : 48|8@1+ (0.4,0) [0|100] "%" Vector__XXX

BO_ 2566842624 LFC_EMS: 8 EMS
 SG_ EngTotalFuelUsed : 32|32@1+ (0.5,0) [0|2105540607.5] "L"  VGW
 SG_ EngTripFuel : 0|32@1+ (0.5,0) [0|2105540607.5] "L" Vector__XXX

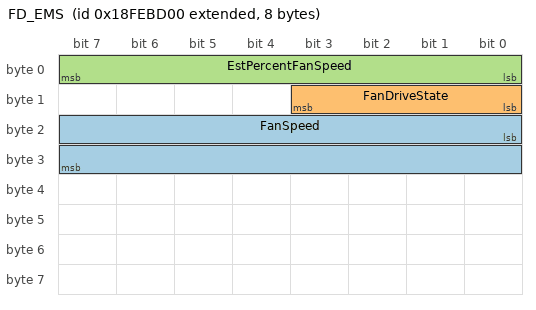
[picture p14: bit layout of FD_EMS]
BO_ 2566831360 FD_EMS: 8 EMS
 SG_ FanSpeed : 16|16@1+ (0.125,0) [0|8031.875] "rpm" Vector__XXX
 SG_ FanDriveState : 8|4@1+ (1,0) [0|15] "" Vector__XXX
 SG_ EstPercentFanSpeed : 0|8@1+ (0.4,0) [0|100] "%" Vector__XXX

BO_TX_BU_ 2566839038 : TCO,SSC,VGW,TPMS,EBS,TECU,EMS;

CM_ BU_ ACS "Alternator/Charging System";
CM_ BU_ CC "Climate Control";
CM_ BU_ TCO "Tachograph";
CM_ BU_ SSC "Suspension System Controller #1";
CM_ BU_ RD "Retarder Driveline";
CM_ BU_ REX "Retarder Exhaust Engine";
CM_ BU_ VGW "Vehicle Gateway";
CM_ BU_ TPMS "Tire Pressure Monitoring System";
CM_ BU_ TECU "Transmission ECU";
CM_ BU_ IC "Instrument Cluster";
CM_ BU_ EMS "Engine Management System";
CM_ BU_ EBS "Electronic Brake System";
CM_ BO_ 3221225472 "This is a message for not used signals, created by Vector CANdb++ DBC OLE DB Provider.";
CM_ SG_ 3221225472 TireTemp "Temperature at the surface of the tire sidewall. (SP242)";
CM_ SG_ 3221225472 TirePress "Pressure at which air is contained in cavity formed by tire and rim. (SP241)";
CM_ SG_ 3221225472 SPN5 "SPN #5 (Conversion Version 4)SPN #5 (Conversion Version 4)SPN #5 (Conversion Version 4)SPN #5 (Conversion Version 4)";
CM_ SG_ 3221225472 SPN4 "SPN #4 (Conversion Version 4)SPN #4 (Conversion Version 4)SPN #4 (Conversion Version 4)SPN #4 (Conversion Version 4)";
CM_ SG_ 3221225472 SPN3 "SPN #3 (Conversion Version 4)SPN #3 (Conversion Version 4)SPN #3 (Conversion Version 4)SPN #3 (Conversion Version 4)";
CM_ SG_ 3221225472 SPN2 "SPN #2 (Conversion Version 4)SPN #2 (Conversion Version 4)SPN #2 (Conversion Version 4)SPN #2 (Conversion Version 4)";
CM_ SG_ 3221225472 FailureModeIdentifier5 "The FMI defines the type of failure detected in the subsystem identified by an SPN.The FMI defines the type of failure detected in the subsystem identified by an SPN.The FMI defines the type of failure detected in the subsystem identified by an SPN.The FMI defines the type of failure detected in the subsystem identified by an SPN.";
CM_ SG_ 3221225472 FailureModeIdentifier4 "The FMI defines the type of failure detected in the subsystem identified by an SPN.The FMI defines the type of failure detected in the subsystem identified by an SPN.The FMI defines the type of failure detected in the subsystem identified by an SPN.The FMI defines the type of failure detected in the subsystem identified by an SPN.";
CM_ SG_ 3221225472 FlashRedStopLamp "This parameter provides the capability to flash the RSL (SPN 3039).This parameter provides the capability to flash the RSL (SPN 3039).This parameter provides the capability to flash the RSL (SPN 3039).";
CM_ SG_ 3221225472 FlashProtectLamp "This parameter provides the capability to flash the engine protect lamp (SPN 3041).This parameter provides the capability to flash the engine protect lamp (SPN 3041).This parameter provides the capability to flash the engine protect lamp (SPN 3041).";
CM_ SG_ 3221225472 FlashMalfuncIndicatorLamp "This parameter provides the capability to flash the MIL (SPN 3038).This parameter provides the capability to flash the MIL (SPN 3038).This parameter provides the capability to flash the MIL (SPN 3038).";
CM_ SG_ 3221225472 FlashAmberWarningLamp "This parameter provides the capability to flash the AWL (SPN 3040). This parameter provides the capability to flash the AWL (SPN 3040). This parameter provides the capability to flash the AWL (SPN 3040). ";
CM_ SG_ 3221225472 FailureModeIdentifier3 "The FMI defines the type of failure detected in the subsystem identified by an SPN.The FMI defines the type of failure detected in the subsystem identified by an SPN.The FMI defines the type of failure detected in the subsystem identified by an SPN.The FMI defines the type of failure detected in the subsystem identified by an SPN.";
CM_ SG_ 3221225472 FailureModeIdentifier2 "The FMI defines the type of failure detected in the subsystem identified by an SPN.The FMI defines the type of failure detected in the subsystem identified by an SPN.The FMI defines the type of failure detected in the subsystem identified by an SPN.The FMI defines the type of failure detected in the subsystem identified by an SPN.";
CM_ SG_ 3221225472 FailureModeIdentifier1 "The FMI defines the type of failure detected in the subsystem identified by an SPN.The FMI defines the type of failure detected in the subsystem identified by an SPN.The FMI defines the type of failure detected in the subsystem identified by an SPN.The FMI defines the type of failure detected in the subsystem identified by an SPN.The FMI defines the type of failure detected in the subsystem identified by an SPN.The FMI defines the type of failure detected in the subsystem identified by an SPN.";
CM_ SG_ 3221225472 SPN1 "SPN #1 (Conversion Version 4)SPN #1 (Conversion Version 4)SPN #1 (Conversion Version 4)SPN #1 (Conversion Version 4)SPN #1 (Conversion Version 4)";
CM_ SG_ 3221225472 MalfunctionIndicatorLampStatus "A lamp used to relay only emissions-related trouble code information.A lamp used to relay only emissions-related trouble code information.A lamp used to relay only emissions-related trouble code information.";
CM_ SG_ 3221225472 RedStopLampState "This lamp is uesed to relay trouble code information that is of a severe enought condition that it warrants stopping the vehicle.This lamp is uesed to relay trouble code information that is of a severe enought condition that it warrants stopping the vehicle.This lamp is uesed to relay trouble code information that is of a severe enought condition that it warrants stopping the vehicle.";
CM_ SG_ 3221225472 AmberWarningLampStatus "This lamp is used to relay trouble code information that is reporting a problem with the vehicle system but the vehicle need
not be immediately stopped.This lamp is used to relay trouble code information that is reporting a problem with the vehicle system but the vehicle need
not be immediately stopped.This lamp is used to relay trouble code information that is reporting a problem with the vehicle system but the vehicle need
not be immediately stopped.";
CM_ SG_ 3221225472 ProtectLampStatus "This lamp is used to relay trouble code informatio that is reporting a problem with a vehicle system that is most
probably not electronic subsystem related.This lamp is used to relay trouble code informatio that is reporting a problem with a vehicle system that is most
probably not electronic subsystem related.This lamp is used to relay trouble code informatio that is reporting a problem with a vehicle system that is most
probably not electronic subsystem related.";
CM_ SG_ 3221225472 SPN5High "SPN #5 (Conversion Version 4)SPN #5 (Conversion Version 4)SPN #5 (Conversion Version 4)SPN #5 (Conversion Version 4)";
CM_ SG_ 3221225472 SPN4High "SPN #4 (Conversion Version 4)SPN #4 (Conversion Version 4)SPN #4 (Conversion Version 4)SPN #4 (Conversion Version 4)";
CM_ SG_ 3221225472 SPN3High "SPN #3 (Conversion Version 4)SPN #3 (Conversion Version 4)SPN #3 (Conversion Version 4)SPN #3 (Conversion Version 4)";
CM_ SG_ 3221225472 SPN2High "SPN #2 (Conversion Version 4)SPN #2 (Conversion Version 4)SPN #2 (Conversion Version 4)SPN #2 (Conversion Version 4)";
CM_ SG_ 3221225472 SPN1High "SPN #1 (Conversion Version 4)SPN #1 (Conversion Version 4)SPN #1 (Conversion Version 4)SPN #1 (Conversion Version 4)SPN #1 (Conversion Version 4)SPN #1 (Conversion Version 4)";
CM_ BO_ 2566836235 "Test results for non-continously monitored systems.";
CM_ SG_ 2566836235 TestLimitMinimum "The threshold which the test value must be above to pass the test.";
CM_ SG_ 2566836235 TestLimitMaximum "The threshold which the test value must be below to pass the test.";
CM_ SG_ 2566836235 TestValue "The test value collected during the test.";
CM_ SG_ 2566836235 TestType "Identifies the non-continously monitored component identifier that was tested.";
CM_ SG_ 2566836235 TestIdentifier "Designates the test to be run.";
CM_ BO_ 2566836224 "Test results for non-continously monitored systems.";
CM_ SG_ 2566836224 TestLimitMinimum "The threshold which the test value must be above to pass the test.";
CM_ SG_ 2566836224 TestLimitMaximum "The threshold which the test value must be below to pass the test.";
CM_ SG_ 2566836224 TestValue "The test value collected during the test.";
CM_ SG_ 2566836224 TestType "Identifies the non-continously monitored component identifier that was tested.";
CM_ SG_ 2566836224 TestIdentifier "Designates the test to be run.";
CM_ BO_ 2560949771 "This message conveys the scaled test results for the applicable test requested in DM7.";
CM_ SG_ 2560949771 TestLimitMinimum "The threshold which the test value must be above to pass the test.";
CM_ SG_ 2560949771 TestLimitMaximum "The threshold which the test value must be below to pass the test.";
CM_ SG_ 2560949771 TestValue "The test value collected during the test.";
CM_ SG_ 2560949771 SlotId "The SLOT Identifer is used to determine the multiplier and offset to be used to scale the test value.";
CM_ SG_ 2560949771 TestIdentifier "Designates the test to be run.";
CM_ SG_ 2560949771 FailureModeIdentifier1 "The FMI defines the type of failure detected in the subsystem identified by an SPN.";
CM_ SG_ 2560949771 SPN1High "SPN #1 (Conversion Version 4)";
CM_ SG_ 2560949771 SPN1 "SPN #1 (Conversion Version 4)";
CM_ BO_ 2560949760 "This message conveys the scaled test results for the applicable test requested in DM7.";
CM_ SG_ 2560949760 TestLimitMinimum "The threshold which the test value must be above to pass the test.";
CM_ SG_ 2560949760 TestLimitMaximum "The threshold which the test value must be below to pass the test.";
CM_ SG_ 2560949760 TestValue "The test value collected during the test.";
CM_ SG_ 2560949760 SlotId "The SLOT Identifer is used to determine the multiplier and offset to be used to scale the test value.";
CM_ SG_ 2560949760 TestIdentifier "Designates the test to be run.";
CM_ SG_ 2560949760 FailureModeIdentifier1 "The FMI defines the type of failure detected in the subsystem identified by an SPN.";
CM_ SG_ 2560949760 SPN1High "SPN #1 (Conversion Version 4)";
CM_ SG_ 2560949760 SPN1 "SPN #1 (Conversion Version 4)";
CM_ BO_ 2566836478 "Test results for non-continously monitored systems.";
CM_ SG_ 2566836478 TestLimitMinimum "The threshold which the test value must be above to pass the test.";
CM_ SG_ 2566836478 TestLimitMaximum "The threshold which the test value must be below to pass the test.";
CM_ SG_ 2566836478 TestValue "The test value collected during the test.";
CM_ SG_ 2566836478 TestType "Identifies the non-continously monitored component identifier that was tested.";
CM_ SG_ 2566836478 TestIdentifier "Designates the test to be run.";
CM_ BO_ 2565078782 "Command non-continously monitored test";
CM_ SG_ 2565078782 SPN1High "SPN #1 (Conversion Version 4)";
CM_ SG_ 2565078782 SPN1 "SPN #1 (Conversion Version 4)";
CM_ SG_ 2565078782 TestIdentifier "Designates the test to be run.";
CM_ SG_ 2565078782 FailureModeIdentifier1 "The FMI defines the type of failure detected in the subsystem identified by an SPN.";
CM_ BO_ 2560950014 "This message conveys the scaled test results for the applicable test requested in DM7.";
CM_ SG_ 2560950014 TestLimitMinimum "The threshold which the test value must be above to pass the test.";
CM_ SG_ 2560950014 TestLimitMaximum "The threshold which the test value must be below to pass the test.";
CM_ SG_ 2560950014 TestValue "The test value collected during the test.";
CM_ SG_ 2560950014 SlotId "The SLOT Identifer is used to determine the multiplier and offset to be used to scale the test value.";
CM_ SG_ 2560950014 TestIdentifier "Designates the test to be run.";
CM_ SG_ 2560950014 FailureModeIdentifier1 "The FMI defines the type of failure detected in the subsystem identified by an SPN.";
CM_ SG_ 2560950014 SPN1High "SPN #1 (Conversion Version 4)";
CM_ SG_ 2560950014 SPN1 "SPN #1 (Conversion Version 4)";
CM_ BO_ 2348941054 "Transmission Control 1";
CM_ SG_ 2348941054 TrnsShftSlctorDisplayModeSwitch "Status of the operator’s switch used to ‘toggle’ through multiple display modes of a shift selector display.";
CM_ SG_ 2348941054 TransMode4 "Indicates whether transmission mode 4 is enabled.";
CM_ SG_ 2348941054 TransMode3 "Indicates whether transmission mode 3 is enabled.";
CM_ SG_ 2348941054 TransMode2 "Indicates whether transmission mode 2 is enabled.";
CM_ SG_ 2348941054 TransMode1 "Indicates whether transmission mode 1 is enabled.";
CM_ SG_ 2348941054 DisengageDiffLockRqCentralRear "Command signal used to disengage the various differential locks, e.";
CM_ SG_ 2348941054 DisengageDiffLockRqCentralFront "Command signal used to disengage the various differential locks, e.";
CM_ SG_ 2348941054 DisengageDiffLockRqCentral "Command signal used to disengage the various differential locks, e.";
CM_ SG_ 2348941054 DisengageDiffLockRqRearAxle2 "Command signal used to disengage the various differential locks, e.";
CM_ SG_ 2348941054 DisengageDiffLockRqRearAxle1 "Command signal used to disengage the various differential locks, e.";
CM_ SG_ 2348941054 DisengageDiffLockRqFrontAxle2 "Command signal used to disengage the various differential locks, e.";
CM_ SG_ 2348941054 DisengageDiffLockRqFrontAxle1 "Command signal used to disengage the various differential locks, e.";
CM_ SG_ 2348941054 TransRqedGear "Gear requested by the operator, ABS, or engine.";
CM_ SG_ 2348941054 RqedPercentClutchSlip "Parameter which represents the percent clutch slip requested by a device.";
CM_ SG_ 2348941054 DisengageDrivelineRq "Command signal used to simply disengage the driveline, e.";
CM_ SG_ 2348941054 TorqueConverterLockupDisableRq "Command signal to prevent torque converter lockup, which may cause problems in certain circumstances for ASR.";
CM_ SG_ 2348941054 TransGearShiftInhibitRq "Command signal to inhibit gear shifts.";
CM_ BO_ 2562981630 "Individual Clear/Reset of active and previously active DTC.";
CM_ SG_ 2562981630 SPN1 "SPN #1 (Conversion Version 4)";
CM_ SG_ 2562981630 SPN1High "SPN #1 (Conversion Version 4)";
CM_ SG_ 2562981630 FailureModeIdentifier1 "The FMI defines the type of failure detected in the subsystem identified by an SPN.";
CM_ BO_ 2348875518 "Torque/Speed Control 1";
CM_ SG_ 2348875518 ControlPurpose "State signal which indicates which control mode the sending device is using to generate the TSC1 command.";
CM_ SG_ 2348875518 TransmissionRate "This parameter indicates the transmission rate at which the sending device will transmit the TSC1 message.";
CM_ SG_ 2348875518 EngRqedTorque_TorqueLimit "Parameter provided to the engine or retarder in the torque/speed control message for controlling or limiting the output torque.";
CM_ SG_ 2348875518 EngRqedSpeed_SpeedLimit "Parameter provided to the engine from external sources in the torque/speed control message.";
CM_ SG_ 2348875518 EngRqedSpeedCtrlConditions "This mode tells the engine control system the governor characteristics that are desired during speed control.";
CM_ BO_ 2566842094 "Time/Date";
CM_ SG_ 2566842094 LocalMinuteOffset "Local offset in minutes from a reference time.";
CM_ SG_ 2566842094 Year "Part of a parameter used to represent a calendar date.";
CM_ SG_ 2566842094 Day "Part of a parameter used to represent a calendar date.";
CM_ SG_ 2566842094 Month "Part of a parameter used to represent a calendar date.";
CM_ SG_ 2566842094 Hours "Part of a parameter used to represent time.";
CM_ SG_ 2566842094 Minutes "Part of a parameter used to represent time.";
CM_ SG_ 2566842094 Seconds "Part of a parameter used to represent time.";
CM_ BO_ 2348820752 "Torque/Speed Control 1";
CM_ SG_ 2348820752 ControlPurpose "State signal which indicates which control mode the sending device is using to generate the TSC1 command.";
CM_ SG_ 2348820752 TransmissionRate "This parameter indicates the transmission rate at which the sending device will transmit the TSC1 message.";
CM_ SG_ 2348820752 EngRqedTorque_TorqueLimit "Parameter provided to the engine or retarder in the torque/speed control message for controlling or limiting the output torque.";
CM_ SG_ 2348820752 EngRqedSpeed_SpeedLimit "Parameter provided to the engine from external sources in the torque/speed control message.";
CM_ SG_ 2348820752 EngRqedSpeedCtrlConditions "This mode tells the engine control system the governor characteristics that are desired during speed control.";
CM_ BO_ 2566840592 "Retarder Configuration";
CM_ SG_ 2566840592 ReferenceRetarderTorque "This parameter is the 100% reference value for all defined indicated retarder torque parameters.";
CM_ SG_ 2566840592 RetarderSpeedAtPoint4 "Retarder speed of point 4 of the engine retarder torque map.";
CM_ SG_ 2566840592 RetarderSpeedAtPoint3 "Retarder speed of point 3 of the engine retarder torque map.";
CM_ SG_ 2566840592 PercentTorqueAtMaxSpeedPoint2 "The torque limit that indicates the available retarder torque which can be provided by the retarder at its maximum speed.";
CM_ SG_ 2566840592 MaxRetarderSpeedPoint2 "Maximum speed of retarder (Please reference PGN 65249).";
CM_ SG_ 2566840592 PercentTorqueAtIdlePoint1 "The torque limit that indicates the available retarder torque which can be provided by the retarder at idle speed.";
CM_ SG_ 2566840592 RetarderCtrlMethod "This parameter identifies the number of steps used by the retarder.";
CM_ SG_ 2566840592 RetarderType "A vehicle retarder is a supplementary device to the wheel brakes for the driver to better control the vehicle.";
CM_ BO_ 2565865488 "Electronic Retarder Controller 1";
CM_ SG_ 2565865488 ActlMxAvlblRtarderPercentTorque "This is the maximum amount of torque that the retarder can immediately deliver.";
CM_ SG_ 2565865488 SrcAddrssOfCtrllngDvcFrRtrdrCtrl "The source address of the SAE J1939 device currently controlling the retarder.";
CM_ SG_ 2565865488 EngCoolantLoadIncrease "Status of an event, external to the engine, that may increase the nominal temperature of the engine coolant liquid.";
CM_ SG_ 2565865488 IntendedRetarderPercentTorque "Braking torque of retarder that the retarder is currently trying to achieve.";
CM_ SG_ 2565865488 ActualRetarderPercentTorque "Actual braking torque of the retarder as a percent of retarder configuration reference torque SPN 556.";
CM_ SG_ 2565865488 RetarderEnableShiftAssistSwitch "Switch signal which indicates whether the operator wishes the retarder to be enabled for transmission shift assist.";
CM_ SG_ 2565865488 RetarderEnableBrakeAssistSwitch "Switch signal which indicates whether the operator wishes the retarder to be enabled for vehicle braking assist.";
CM_ SG_ 2565865488 RetarderTorqueMode "State signal which indicates which retarder torque mode is currently generating, limiting, or controlling the torque.";
CM_ BO_ 2348814347 "Torque/Speed Control 1";
CM_ SG_ 2348814347 ControlPurpose "State signal which indicates which control mode the sending device is using to generate the TSC1 command.";
CM_ SG_ 2348814347 TransmissionRate "This parameter indicates the transmission rate at which the sending device will transmit the TSC1 message.";
CM_ SG_ 2348814347 EngRqedTorque_TorqueLimit "Parameter provided to the engine or retarder in the torque/speed control message for controlling or limiting the output torque.";
CM_ SG_ 2348814347 EngRqedSpeed_SpeedLimit "Parameter provided to the engine from external sources in the torque/speed control message.";
CM_ SG_ 2348814347 EngRqedSpeedCtrlConditions "This mode tells the engine control system the governor characteristics that are desired during speed control.";
CM_ BO_ 2348810251 "Torque/Speed Control 1";
CM_ SG_ 2348810251 ControlPurpose "State signal which indicates which control mode the sending device is using to generate the TSC1 command.";
CM_ SG_ 2348810251 TransmissionRate "This parameter indicates the transmission rate at which the sending device will transmit the TSC1 message.";
CM_ SG_ 2348810251 EngRqed_TorqueLimit "Parameter provided to the engine or retarder in the torque/speed control message for controlling or limiting the output torque.";
CM_ SG_ 2348810251 EngRqed_SpeedLimit "Parameter provided to the engine from external sources in the torque/speed control message.";
CM_ SG_ 2348810251 EngRqedSpeedCtrlCond "This mode tells the engine control system the governor characteristics that are desired during speed control.";
CM_ BO_ 2348820739 "Torque/Speed Control 1";
CM_ SG_ 2348820739 ControlPurpose "State signal which indicates which control mode the sending device is using to generate the TSC1 command.";
CM_ SG_ 2348820739 TransmissionRate "This parameter indicates the transmission rate at which the sending device will transmit the TSC1 message.";
CM_ SG_ 2348820739 EngRqedTorque_TorqueLimit "Parameter provided to the engine or retarder in the torque/speed control message for controlling or limiting the output torque.";
CM_ SG_ 2348820739 EngRqedSpeed_SpeedLimit "Parameter provided to the engine from external sources in the torque/speed control message.";
CM_ SG_ 2348820739 EngRqedSpeedCtrlConditions "This mode tells the engine control system the governor characteristics that are desired during speed control.";
CM_ BO_ 2348820747 "Torque/Speed Control 1";
CM_ SG_ 2348820747 ControlPurpose "State signal which indicates which control mode the sending device is using to generate the TSC1 command.";
CM_ SG_ 2348820747 TransmissionRate "This parameter indicates the transmission rate at which the sending device will transmit the TSC1 message.";
CM_ SG_ 2348820747 EngRqedTorque_TorqueLimit "Parameter provided to the engine or retarder in the torque/speed control message for controlling or limiting the output torque.";
CM_ SG_ 2348820747 EngRqedSpeed_SpeedLimit "Parameter provided to the engine from external sources in the torque/speed control message.";
CM_ SG_ 2348820747 EngRqedSpeedCtrlConditions "This mode tells the engine control system the governor characteristics that are desired during speed control.";
CM_ BO_ 2348810243 "Torque/Speed Control 1";
CM_ SG_ 2348810243 ControlPurpose "State signal which indicates which control mode the sending device is using to generate the TSC1 command.";
CM_ SG_ 2348810243 TransmissionRate "This parameter indicates the transmission rate at which the sending device will transmit the TSC1 message.";
CM_ SG_ 2348810243 EngRqed_TorqueLimit "Parameter provided to the engine or retarder in the torque/speed control message for controlling or limiting the output torque.";
CM_ SG_ 2348810243 EngRqed_SpeedLimit "Parameter provided to the engine from external sources in the torque/speed control message.";
CM_ SG_ 2348810243 EngRqedSpeedCtrlCond "This mode tells the engine control system the governor characteristics that are desired during speed control.";
CM_ BO_ 2566845952 "Inlet/Exhaust Conditions 1";
CM_ SG_ 2566845952 EngExhaustGasTemp "Temperature of combustion byproducts leaving the engine.";
CM_ SG_ 2566845952 EngAirInletPress "Absolute air pressure at inlet to intake manifold or air box.";
CM_ SG_ 2566845952 EngIntakeManifold1Temp "Temperature of pre-combustion air found in intake manifold of engine air supply system.";
CM_ SG_ 2566845952 EngTurboBoostPress "Gage pressure of air measured downstream on the compressor discharge side of the turbocharger.";
CM_ SG_ 2566845952 EngParticulateTrapInletPress "Exhaust back pressure as a result of particle accumulation on filter media placed in the exhaust stream.";
CM_ BO_ 2566841600 "Engine Hours, Revolutions";
CM_ SG_ 2566841600 EngTotalRevolutions "Accumulated number of revolutions of engine crankshaft during its operation.";
CM_ SG_ 2566841600 EngTotalHoursOfOperation "Accumulated time of operation of engine.";
CM_ BO_ 2566842927 "Vehicle Weight";
CM_ SG_ 2566842927 CargoWeight "The mass of freight carried.";
CM_ SG_ 2566842927 TrailerWeight "Total mass of freight-carrying vehicle designed to be pulled by truck, including the weight of the contents.";
CM_ SG_ 2566842927 AxleWeight "Total mass imposed by the tires on the road surface at the specified axle.";
CM_ SG_ 2566842927 AxleLocation "To identify to which of several similar devices (such as tires or fuel tanks) the information applies.";
CM_ BO_ 2566843392 "Vehicle Identification";
CM_ SG_ 2566843392 VehicleIdentificationNumber "Vehicle Identification Number";
CM_ BO_ 2566832384 "High Resolution Vehicle Distance";
CM_ SG_ 2566832384 HighResolutionTripDistance "Distance traveled during all or part of a journey.";
CM_ SG_ 2566832384 HghRslutionTotalVehicleDistance "Accumulated distance traveled by the vehicle during its operation.";
CM_ BO_ 2565867787 "Vehicle Dynamic Stability Control 2";
CM_ SG_ 2565867787 LongitudinalAcceleration "Indicates the longitudinal acceleration of the vehicle.";
CM_ SG_ 2565867787 LateralAcceleration "Indicates a lateral acceleration of the vehicle.";
CM_ SG_ 2565867787 YawRate "Indicates the rotation about the vertical axis.";
CM_ SG_ 2565867787 SteerWheelTurnCounter "Indicates number of steering wheel turns, absolute position or relative position at ignition on.";
CM_ SG_ 2565867787 SteerWheelAngle "The main operator`s steering wheel angle (on the steering column, not the actual wheel angle).";
CM_ BO_ 2566803211 "Vehicle Dynamic Stability Control 1";
CM_ SG_ 2566803211 YCBrakeCtrlActive "State signal which indicates that Yaw Control (YC) has activated brake control.";
CM_ SG_ 2566803211 YCEngCtrlActive "State Signal which indicates that the Yaw Control (YC) has commanded engine control to be active.";
CM_ SG_ 2566803211 ROPBrakeCtrlActive "State signal which indicates that Roll over Prevention (ROP) has activated brake control.";
CM_ SG_ 2566803211 ROPEngCtrlActive "State Signal which indicates that the Roll Over Prevention (ROP) has commanded engine control to be active.";
CM_ SG_ 2566803211 VDCFullyOperational "Signal that indicates whether VDC is fully operational or whether its functionality is reduced by a permanent or temporary (e.";
CM_ SG_ 2566803211 VDCInformationSignal "This parameter commands the VDC information signal, for example a dash lamp.";
CM_ BO_ 2566840320 "Vehicle Distance";
CM_ SG_ 2566840320 TotalVehicleDistance "Accumulated distance traveled by vehicle during its operation.";
CM_ SG_ 2566840320 TripDistance "Distance traveled during all or part of a journey.";
CM_ BO_ 2561605374 "Tire Pressure Reference Setting";
CM_ SG_ 2561605374 TireLocation "Identifies which tire is associated with the parametric data in this PGN.";
CM_ BO_ 2566764851 "Tire Pressure Reference Information";
CM_ SG_ 2566764851 TireLocation "Identifies which tire is associated with the parametric data in this PGN.";
CM_ BO_ 2566845491 "Tire Condition";
CM_ SG_ 2566845491 TireTemp_21 "Temperature at the surface of the tire sidewall. (SP242)";
CM_ SG_ 2566845491 TireTemp_20 "Temperature at the surface of the tire sidewall. (SP242)";
CM_ SG_ 2566845491 TireTemp_11 "Temperature at the surface of the tire sidewall. (SP242)";
CM_ SG_ 2566845491 TireTemp_10 "Temperature at the surface of the tire sidewall. (SP242)";
CM_ SG_ 2566845491 TireTemp_01 "Temperature at the surface of the tire sidewall. (SP242)";
CM_ SG_ 2566845491 TireTemp_00 "Temperature at the surface of the tire sidewall. (SP242)";
CM_ SG_ 2566845491 TirePressThresholdDetection_21 "Signal indicating the pressure level of the tire. (SP2587)";
CM_ SG_ 2566845491 TirePressThresholdDetection_20 "Signal indicating the pressure level of the tire. (SP2587)";
CM_ SG_ 2566845491 TirePressThresholdDetection_11 "Signal indicating the pressure level of the tire. (SP2587)";
CM_ SG_ 2566845491 TirePressThresholdDetection_10 "Signal indicating the pressure level of the tire. (SP2587)";
CM_ SG_ 2566845491 TirePressThresholdDetection_01 "Signal indicating the pressure level of the tire. (SP2587)";
CM_ SG_ 2566845491 TirePressThresholdDetection_00 "Signal indicating the pressure level of the tire. (SP2587)";
CM_ SG_ 2566845491 TirePress_21 "Pressure at which air is contained in cavity formed by tire and rim. (SP241)";
CM_ SG_ 2566845491 TirePress_20 "Pressure at which air is contained in cavity formed by tire and rim. (SP241)";
CM_ SG_ 2566845491 TirePress_11 "Pressure at which air is contained in cavity formed by tire and rim. (SP241)";
CM_ SG_ 2566845491 TirePress_10 "Pressure at which air is contained in cavity formed by tire and rim. (SP241)";
CM_ SG_ 2566845491 TirePress_01 "Pressure at which air is contained in cavity formed by tire and rim. (SP241)";
CM_ SG_ 2566845491 TirePress_00 "Pressure at which air is contained in cavity formed by tire and rim. (SP241)";
CM_ SG_ 2566845491 TireAirLeakageRate_21 "The pressure loss rate of a tire. (SP2586)";
CM_ SG_ 2566845491 TireAirLeakageRate_20 "The pressure loss rate of a tire. (SP2586)";
CM_ SG_ 2566845491 TireAirLeakageRate_11 "The pressure loss rate of a tire. (SP2586)";
CM_ SG_ 2566845491 TireAirLeakageRate_10 "The pressure loss rate of a tire. (SP2586)";
CM_ SG_ 2566845491 TireAirLeakageRate_01 "The pressure loss rate of a tire. (SP2586)";
CM_ SG_ 2566845491 TireAirLeakageRate_00 "The pressure loss rate of a tire. (SP2586)";
CM_ SG_ 2566845491 CTIWheelSensorStatus_21 "Indicates whether the wheel is being monitored by the CTI controller. (SP1699)";
CM_ SG_ 2566845491 CTIWheelSensorStatus_20 "Indicates whether the wheel is being monitored by the CTI controller. (SP1699)";
CM_ SG_ 2566845491 CTIWheelSensorStatus_11 "Indicates whether the wheel is being monitored by the CTI controller. (SP1699)";
CM_ SG_ 2566845491 CTIWheelSensorStatus_10 "Indicates whether the wheel is being monitored by the CTI controller. (SP1699)";
CM_ SG_ 2566845491 CTIWheelSensorStatus_01 "Indicates whether the wheel is being monitored by the CTI controller. (SP1699)";
CM_ SG_ 2566845491 CTIWheelSensorStatus_00 "Indicates whether the wheel is being monitored by the CTI controller. (SP1699)";
CM_ SG_ 2566845491 CTIWheelEndElectricalFault_21 "Indicates the status of electrical fault on CTI wheel interface. (SP1697)";
CM_ SG_ 2566845491 CTIWheelEndElectricalFault_20 "Indicates the status of electrical fault on CTI wheel interface. (SP1697)";
CM_ SG_ 2566845491 CTIWheelEndElectricalFault_11 "Indicates the status of electrical fault on CTI wheel interface. (SP1697)";
CM_ SG_ 2566845491 CTIWheelEndElectricalFault_10 "Indicates the status of electrical fault on CTI wheel interface. (SP1697)";
CM_ SG_ 2566845491 CTIWheelEndElectricalFault_01 "Indicates the status of electrical fault on CTI wheel interface. (SP1697)";
CM_ SG_ 2566845491 CTIWheelEndElectricalFault_00 "Indicates the status of electrical fault on CTI wheel interface. (SP1697)";
CM_ SG_ 2566845491 CTITireStatus_21 "Indicates the status of the tire. (SP1698)";
CM_ SG_ 2566845491 CTITireStatus_20 "Indicates the status of the tire. (SP1698)";
CM_ SG_ 2566845491 CTITireStatus_11 "Indicates the status of the tire. (SP1698)";
CM_ SG_ 2566845491 CTITireStatus_10 "Indicates the status of the tire. (SP1698)";
CM_ SG_ 2566845491 CTITireStatus_01 "Indicates the status of the tire. (SP1698)";
CM_ SG_ 2566845491 CTITireStatus_00 "Indicates the status of the tire. (SP1698)";
CM_ SG_ 2566845491 TireLocation "Identifies which tire is associated with the parametric data in this PGN.";
CM_ BO_ 2566841879 "Time/Date";
CM_ SG_ 2566841879 LocalMinuteOffset "Local offset in minutes from a reference time.";
CM_ SG_ 2566841879 Year "Part of a parameter used to represent a calendar date.";
CM_ SG_ 2566841879 Day "Part of a parameter used to represent a calendar date.";
CM_ SG_ 2566841879 Month "Part of a parameter used to represent a calendar date.";
CM_ SG_ 2566841879 Hours "Part of a parameter used to represent time.";
CM_ SG_ 2566841879 Minutes "Part of a parameter used to represent time.";
CM_ SG_ 2566841879 Seconds "Part of a parameter used to represent time.";
CM_ BO_ 2365484270 "Tachograph";
CM_ SG_ 2365484270 TachographVehicleSpeed "Speed of the vehicle registered by the tachograph.";
CM_ SG_ 2365484270 TachographOutputShaftSpeed "Calculated speed of the transmission output shaft.";
CM_ SG_ 2365484270 DirectionIndicator "Indicates the direction of the vehicle.";
CM_ SG_ 2365484270 HandlingInformation "Indicates that handling information is present.";
CM_ SG_ 2365484270 SystemEvent "Indicates that a tachograph event has occurred.";
CM_ SG_ 2365484270 Driver2TimeRelatedStates "Indicates if the driver approaches or exceeds working time limits (or other limits).";
CM_ SG_ 2365484270 Overspeed "Indicates whether the vehicle is exceeding the legal speed limit set in the tachograph.";
CM_ SG_ 2365484270 Driver1TimeRelatedStates "Indicates if the driver approaches or exceeds working time limits (or other limits).";
CM_ SG_ 2365484270 DriveRecognize "Indicates whether motion of the vehicle is detected or not.";
CM_ SG_ 2365484270 Driver2WorkingState "State of work of the driver.";
CM_ SG_ 2365484270 Driver1WorkingState "State of work of the driver.";
CM_ BO_ 2566802179 "Transmission Configuration 2";
CM_ BO_ 2566840835 "Transmission Configuration";
CM_ SG_ 2566840835 NumberOfForwardGearRatios "Number of forward gear ratios in the transmission, provided as part of the configuration.";
CM_ SG_ 2566840835 NumberOfReverseGearRatios "Number of reverse gear ratios in the transmission, provided as part of the transmission configuration.";
CM_ BO_ 2566839552 "Turbocharger";
CM_ SG_ 2566839552 EngTurbo1Speed "Rotational velocity of rotor in the turbocharger.";
CM_ SG_ 2566839552 EngTurboLubeOilPress1 "Gage pressure of oil in turbocharger lubrication system.";
CM_ BO_ 2566775343 "Supply Pressure Demand";
CM_ SG_ 2566775343 AirSuspensionSupplyPressRq "Command signal to influence the pneumatic pressure in the circuit for the electronically controlled air suspension system.";
CM_ SG_ 2566775343 AuxEquipmentSupplyPressRq "Command signal to influence the pneumatic pressure in the auxiliary circuit.";
CM_ SG_ 2566775343 ServiceBrakeAirPressRqCircuit2 "Command signal to influence the pneumatic pressure in the service brake circuit or reservoir #2.";
CM_ SG_ 2566775343 ServiceBrakeAirPressRqCircuit1 "Command signal to influence the pneumatic pressure in the service brake circuit or reservoir #1.";
CM_ SG_ 2566775343 ParkingAnd_OrTrailerAirPressRq "Command signal to influence the pneumatic pressure in the circuit or reservoir for the parking brake and/or the trailer supply.";
CM_ SG_ 2566775343 PneumaticSupplyPressRq "Command signal to influence the pneumatic pressure in the main reservoir.";
CM_ BO_ 2566839038 "Software Identification";
CM_ SG_ 2566839038 SoftwareID3 "Software ID";
CM_ SG_ 2566839038 SoftwareID2 "Software ID";
CM_ SG_ 2566839038 SoftwareID1 "Software ID";
CM_ SG_ 2566839038 NmbrOfSftwrIdentificationFields "Number of software identification designators represented in the software identification parameter group.";
CM_ BO_ 2566841344 "Shutdown";
CM_ SG_ 2566841344 EngOverspeedTest "The engine overspeed test signal as measured by the reporting ECM.";
CM_ SG_ 2566841344 EngAirShutoffCmdStatus "State signal which indicates when the Air Shutoff driver output is being driven.";
CM_ SG_ 2566841344 EngAlarmOutputCmdStatus "State signal which indicates when the Alarm driver output is being driven.";
CM_ SG_ 2566841344 EngAlarmAcknowledge "The Engine Alarm Acknowledge Input signal as measured by the reporting ECM.";
CM_ SG_ 2566841344 EngProtectionSystemConfig "Parameter which indicates the configuration of the engine shutdown system.";
CM_ SG_ 2566841344 EngProtectionSystemTimerState "Status signal which indicates the current mode of the engine protection system timer system.";
CM_ SG_ 2566841344 EngPrtectionSystemTimerOverride "Status signal which indicates the status of the override feature of the engine protection system timer.";
CM_ SG_ 2566841344 EngPrtctnSystmApprchingShutdown "Status signal which indicates that engine shutdown is imminent.";
CM_ SG_ 2566841344 EngPrtctionSystemHasShutdownEng "Status signal which indicates whether or not the engine protection system has shutdown the engine.";
CM_ SG_ 2566841344 RefrigerantHighPressSwitch "Switch signal which indicates the position of the high pressure switch in the coolant circuit of an air conditioning system.";
CM_ SG_ 2566841344 RefrigerantLowPressSwitch "Switch signal which indicates the position of the low pressure switch in the coolant circuit of an air conditioning system.";
CM_ SG_ 2566841344 EngIdleShutdownTimerFunction "Parameter which indicates the configuration of the idle shutdown timer system.";
CM_ SG_ 2566841344 EngIdleShutdownTimerState "Status signal which indicates the current mode of operation of the idle shutdown timer system.";
CM_ SG_ 2566841344 EngIdleShutdownTimerOverride "Status signal which indicates the status of the override feature of the idle shutdown timer system.";
CM_ SG_ 2566841344 EngIdleShutdownDriverAlertMode "Status signal which indicates the status of the driver alert mode of the idle shutdown timer system.";
CM_ SG_ 2566841344 EngIdleShutdownHasShutdownEng "Status signal which identifies whether or not the engine has been shutdown by the idle shutdown timer system.";
CM_ BO_ 2566832382 "Service Information";
CM_ SG_ 2566832382 ServiceComponentIdentificationB "Identification of component needing service.";
CM_ SG_ 2566832382 ServiceComponentIdentificationA "Identification of component needing service.";
CM_ SG_ 2566832382 SrvceDelay_OperationalTimeBased "The time in vehicle operational time until the next vehicle service inspection is required.";
CM_ SG_ 2566832382 ServiceDelay_CalendarTimeBased "The time in weeks until the next vehicle service inspection is required.";
CM_ SG_ 2566832382 ServiceDistance "The distance which can be traveled by the vehicle before the next service inspection is required.";
CM_ SG_ 2566832382 ServiceComponentIdentification "Identification of component needing service.";
CM_ BO_ 2566847248 "Retarder fluids";
CM_ SG_ 2566847248 HydRetarderOilTemp "Temperature of oil found in a hydraulic retarder.";
CM_ SG_ 2566847248 HydRetarderPress "Gage pressure of oil in hydraulic retarder system.";
CM_ BO_ 2631855639 "Reset";
CM_ SG_ 2631855639 EngBuildHoursReset "Command signal used to reset the engine rebuild hours.";
CM_ SG_ 2631855639 ServiceComponentIdentification "Identification of component needing service.";
CM_ SG_ 2631855639 TripGroup2Proprietary "Command signal used to reset proprietary parameters associated with a trip but not defined within this document.";
CM_ SG_ 2631855639 TripGroup1 "Command signal used to reset the PGNs and parameters as defined in Table SPN988_A.";
CM_ BO_ 2566840617 "Retarder Configuration";
CM_ SG_ 2566840617 ReferenceRetarderTorque "This parameter is the 100% reference value for all defined indicated retarder torque parameters.";
CM_ SG_ 2566840617 RetarderSpeedAtPoint4 "Retarder speed of point 4 of the engine retarder torque map.";
CM_ SG_ 2566840617 RetarderSpeedAtPoint3 "Retarder speed of point 3 of the engine retarder torque map.";
CM_ SG_ 2566840617 PercentTorqueAtMaxSpeedPoint2 "The torque limit that indicates the available retarder torque which can be provided by the retarder at its maximum speed.";
CM_ SG_ 2566840617 MaxRetarderSpeedPoint2 "Maximum speed of retarder (Please reference PGN 65249).";
CM_ SG_ 2566840617 PercentTorqueAtIdlePoint1 "The torque limit that indicates the available retarder torque which can be provided by the retarder at idle speed.";
CM_ SG_ 2566840617 RetarderCtrlMethod "This parameter identifies the number of steps used by the retarder.";
CM_ SG_ 2566840617 RetarderType "A vehicle retarder is a supplementary device to the wheel brakes for the driver to better control the vehicle.";
CM_ BO_ 2566844416 "Power Takeoff Information";
CM_ SG_ 2566844416 OperatorPTOMemorySelectSwitch "Measured state of the operator PTO memory select switch.";
CM_ SG_ 2566844416 EngPTOAccelerateSwitch "Switch signal of the PTO control activator which indicates that the activator is in the position \"accelerate\".";
CM_ SG_ 2566844416 EngPTOResumeSwitch "Switch signal of the PTO control activator which indicates that the activator is in the position \"resume\".";
CM_ SG_ 2566844416 EngPTOCoast_DecelerateSwitch "Switch signal of the PTO control activator which indicates that the activator is in the position \"coast/decelerate\".";
CM_ SG_ 2566844416 EngPTOSetSwitch "Switch signal of the PTO control activator which indicates that the activator is in the position \"set\".";
CM_ SG_ 2566844416 EngRmtPTOVriableSpeedCtrlSwitch "Switch signal which indicates that the remote PTO toggle switch is in the enabled (ON) position.";
CM_ SG_ 2566844416 EngRmtPTOPrprgrmmdSpdCtrlSwitch "Switch signal which indicates that the remote PTO toggle switch is in the enabled (ON) position.";
CM_ SG_ 2566844416 PowerTakeoffSetSpeed "Rotational velocity selected by operator for device used to transmit engine power to auxiliary equipment.";
CM_ SG_ 2566844416 PowerTakeoffSpeed "Rotational velocity of device used to transmit engine power to auxiliary equipment.";
CM_ SG_ 2566844416 PowerTakeoffOilTemp "Temperature of lubricant in device used to transmit engine power to auxiliary equipment.";
CM_ SG_ 2566844416 RmtPTOPrprgrmmdSpeedCtrlSwitch2 "Switch signal which indicates that the remote PTO toggle switch #2 is in the enabled (ON) position.";
CM_ SG_ 2566844416 AuxInputIgnoreSwitch "Switch signal which overrides other switch input's ability to kick out of an engine's operating condition.";
CM_ BO_ 2566844928 "Fuel Economy (Liquid)";
CM_ SG_ 2566844928 EngAverageFuelEconomy "Average of instantaneous fuel economy for that segment of vehicle operation of interest.";
CM_ SG_ 2566844928 EngInstantaneousFuelEconomy "Current fuel economy at current vehicle velocity.";
CM_ SG_ 2566844928 EngFuelRate "Amount of fuel consumed by engine per unit of time.";
CM_ SG_ 2566844928 EngThrottlePos "The position of the valve used to regulate the supply of a fluid, usually air or fuel/air mixture, to an engine.";
CM_ BO_ 2566842624 "Fuel Consumption (Liquid)";
CM_ SG_ 2566842624 EngTotalFuelUsed "Accumulated amount of fuel used during vehicle operation.";
CM_ SG_ 2566842624 EngTripFuel "Fuel consumed during all or part of a journey.";
CM_ BO_ 2566831360 "Fan Drive";
CM_ SG_ 2566831360 FanSpeed "The speed of the fan associated with engine coolant system.";
CM_ SG_ 2566831360 FanDriveState "This parameter is used to indicate the current state or mode of operation by the fan drive.";
CM_ SG_ 2566831360 EstPercentFanSpeed "Estimated fan speed as a ratio of the fan drive (current speed) to the fully engaged fan drive (maximum fan speed).";
BA_DEF_ SG_  "SigType" ENUM  "Default","Range","RangeSigned","ASCII","Discrete","Control","ReferencePGN","DTC","StringDelimiter","StringLength","StringLengthControl";
BA_DEF_ SG_  "GenSigStartValue" FLOAT 0 10000;
BA_DEF_ SG_  "GenSigSendType" ENUM  "Cyclic","OnWrite","reserved","OnChange","reserved","reserved","reserved","NoSigSendType";
BA_DEF_ SG_  "GenSigILSupport" ENUM  "Yes","No";
BA_DEF_ BO_  "GenMsgILSupport" ENUM  "Yes","No";
BA_DEF_ SG_  "SPN" INT 0 524287;
BA_DEF_ BO_  "GenMsgRequestable" INT 0 1;
BA_DEF_ BO_  "GenMsgSendType" ENUM  "cyclic","reserved","cyclicIfActive","reserved","reserved","reserved","reserved","reserved","noMsgSendType";
BA_DEF_ BO_  "VFrameFormat" ENUM  "StandardCAN","ExtendedCAN","reserved","J1939PG";
BA_DEF_ BO_  "GenMsgCycleTime" INT 0 3600000;
BA_DEF_ BU_  "NodeLayerModules" STRING ;
BA_DEF_ BU_  "NmStationAddress" INT 0 255;
BA_DEF_ BU_  "NmJ1939AAC" INT 0 1;
BA_DEF_ BU_  "NmJ1939IndustryGroup" INT 0 7;
BA_DEF_ BU_  "NmJ1939System" INT 0 127;
BA_DEF_ BU_  "NmJ1939SystemInstance" INT 0 15;
BA_DEF_ BU_  "NmJ1939Function" INT 0 255;
BA_DEF_ BU_  "NmJ1939FunctionInstance" INT 0 7;
BA_DEF_ BU_  "NmJ1939ECUInstance" INT 0 7;
BA_DEF_ BU_  "NmJ1939ManufacturerCode" INT 0 2047;
BA_DEF_ BU_  "NmJ1939IdentityNumber" INT 0 2097151;
BA_DEF_ BU_  "ECU" STRING ;
BA_DEF_  "DatabaseVersion" STRING ;
BA_DEF_  "BusType" STRING ;
BA_DEF_  "ProtocolType" STRING ;
BA_DEF_DEF_  "SigType" "Default";
BA_DEF_DEF_  "GenSigStartValue" 0;
BA_DEF_DEF_  "GenSigSendType" "NoSigSendType";
BA_DEF_DEF_  "GenSigILSupport" "Yes";
BA_DEF_DEF_  "GenMsgILSupport" "Yes";
BA_DEF_DEF_  "SPN" 0;
BA_DEF_DEF_  "GenMsgRequestable" 1;
BA_DEF_DEF_  "GenMsgSendType" "noMsgSendType";
BA_DEF_DEF_  "VFrameFormat" "J1939PG";
BA_DEF_DEF_  "GenMsgCycleTime" 0;
BA_DEF_DEF_  "NodeLayerModules" "";
BA_DEF_DEF_  "NmStationAddress" 254;
BA_DEF_DEF_  "NmJ1939AAC" 0;
BA_DEF_DEF_  "NmJ1939IndustryGroup" 0;
BA_DEF_DEF_  "NmJ1939System" 0;
BA_DEF_DEF_  "NmJ1939SystemInstance" 0;
BA_DEF_DEF_  "NmJ1939Function" 0;
BA_DEF_DEF_  "NmJ1939FunctionInstance" 0;
BA_DEF_DEF_  "NmJ1939ECUInstance" 0;
BA_DEF_DEF_  "NmJ1939ManufacturerCode" 0;
BA_DEF_DEF_  "NmJ1939IdentityNumber" 0;
BA_DEF_DEF_  "ECU" "";
BA_DEF_DEF_  "DatabaseVersion" "";
BA_DEF_DEF_  "BusType" "";
BA_DEF_DEF_  "ProtocolType" "";
BA_ "BusType" "CAN";
BA_ "ProtocolType" "J1939";
BA_ "DatabaseVersion" "7.0";
BA_ "NodeLayerModules" BU_ ACS "J1939_IL.dll";
BA_ "NmStationAddress" BU_ ACS 243;
BA_ "NmJ1939IndustryGroup" BU_ ACS 1;
BA_ "NmJ1939Function" BU_ ACS 53;
BA_ "NmJ1939ManufacturerCode" BU_ ACS 1861;
BA_ "NmJ1939IdentityNumber" BU_ ACS 604042;
BA_ "ECU" BU_ ACS "ACS";
BA_ "NodeLayerModules" BU_ CC "J1939_IL.dll";
BA_ "NmStationAddress" BU_ CC 25;
BA_ "NmJ1939Function" BU_ CC 21;
BA_ "NmJ1939ManufacturerCode" BU_ CC 1861;
BA_ "NmJ1939IdentityNumber" BU_ CC 604041;
BA_ "ECU" BU_ CC "CC";
BA_ "NodeLayerModules" BU_ TCO "J1939_IL.dll";
BA_ "ECU" BU_ TCO "TCO";
BA_ "NmJ1939IdentityNumber" BU_ TCO 603294;
BA_ "NmJ1939ManufacturerCode" BU_ TCO 1861;
BA_ "NmJ1939Function" BU_ TCO 128;
BA_ "NmJ1939IndustryGroup" BU_ TCO 1;
BA_ "NmStationAddress" BU_ TCO 238;
BA_ "NodeLayerModules" BU_ SSC "J1939_IL.dll";
BA_ "ECU" BU_ SSC "SSC";
BA_ "NmJ1939IdentityNumber" BU_ SSC 603293;
BA_ "NmJ1939ManufacturerCode" BU_ SSC 1861;
BA_ "NmJ1939Function" BU_ SSC 35;
BA_ "NmStationAddress" BU_ SSC 47;
BA_ "NodeLayerModules" BU_ RD "J1939_IL.dll";
BA_ "ECU" BU_ RD "RD";
BA_ "NmJ1939IdentityNumber" BU_ RD 603292;
BA_ "NmJ1939ManufacturerCode" BU_ RD 1861;
BA_ "NmJ1939Function" BU_ RD 13;
BA_ "NmStationAddress" BU_ RD 16;
BA_ "NodeLayerModules" BU_ REX "J1939_IL.dll";
BA_ "ECU" BU_ REX "RE";
BA_ "NmJ1939IdentityNumber" BU_ REX 603291;
BA_ "NmJ1939ManufacturerCode" BU_ REX 1861;
BA_ "NmJ1939Function" BU_ REX 12;
BA_ "NmStationAddress" BU_ REX 41;
BA_ "NodeLayerModules" BU_ VGW "J1939_IL.dll";
BA_ "NmStationAddress" BU_ VGW 230;
BA_ "NmJ1939IndustryGroup" BU_ VGW 1;
BA_ "NmJ1939Function" BU_ VGW 131;
BA_ "NmJ1939ManufacturerCode" BU_ VGW 1861;
BA_ "NmJ1939IdentityNumber" BU_ VGW 603241;
BA_ "ECU" BU_ VGW "VGW";
BA_ "NodeLayerModules" BU_ TPMS "J1939_IL.dll";
BA_ "ECU" BU_ TPMS "TPMS";
BA_ "NmJ1939IdentityNumber" BU_ TPMS 603215;
BA_ "NmJ1939ManufacturerCode" BU_ TPMS 1861;
BA_ "NmJ1939Function" BU_ TPMS 38;
BA_ "NmStationAddress" BU_ TPMS 51;
BA_ "NodeLayerModules" BU_ TECU "J1939_IL.dll";
BA_ "ECU" BU_ TECU "TECU";
BA_ "NmJ1939IdentityNumber" BU_ TECU 603214;
BA_ "NmJ1939ManufacturerCode" BU_ TECU 1861;
BA_ "NmJ1939Function" BU_ TECU 3;
BA_ "NmStationAddress" BU_ TECU 3;
BA_ "NodeLayerModules" BU_ IC "J1939_IL.dll";
BA_ "ECU" BU_ IC "IC";
BA_ "NmJ1939IdentityNumber" BU_ IC 603213;
BA_ "NmJ1939ManufacturerCode" BU_ IC 1861;
BA_ "NmJ1939Function" BU_ IC 19;
BA_ "NmStationAddress" BU_ IC 23;
BA_ "NodeLayerModules" BU_ EMS "J1939_IL.dll";
BA_ "ECU" BU_ EMS "EMS";
BA_ "NmJ1939IdentityNumber" BU_ EMS 603212;
BA_ "NmJ1939ManufacturerCode" BU_ EMS 1861;
BA_ "NmStationAddress" BU_ EMS 0;
BA_ "NodeLayerModules" BU_ EBS "J1939_IL.dll";
BA_ "ECU" BU_ EBS "EBS";
BA_ "NmJ1939IdentityNumber" BU_ EBS 603211;
BA_ "NmJ1939ManufacturerCode" BU_ EBS 1861;
BA_ "NmJ1939Function" BU_ EBS 9;
BA_ "NmStationAddress" BU_ EBS 11;
BA_ "GenMsgCycleTime" BO_ 2565865488 100;
BA_ "GenMsgSendType" BO_ 2565865488 0;
BA_ "GenMsgSendType" BO_ 2566845952 0;
BA_ "GenMsgCycleTime" BO_ 2566845952 500;
BA_ "GenMsgSendType" BO_ 2566832384 0;
BA_ "GenMsgCycleTime" BO_ 2566832384 1000;
BA_ "GenMsgSendType" BO_ 2565867787 0;
BA_ "GenMsgCycleTime" BO_ 2565867787 10;
BA_ "GenMsgSendType" BO_ 2566803211 0;
BA_ "GenMsgCycleTime" BO_ 2566803211 100;
BA_ "GenMsgSendType" BO_ 2566840320 0;
BA_ "GenMsgCycleTime" BO_ 2566840320 100;
BA_ "GenMsgSendType" BO_ 2566845491 0;
BA_ "GenMsgCycleTime" BO_ 2566845491 100;
BA_ "GenMsgSendType" BO_ 2365484270 0;
BA_ "GenMsgCycleTime" BO_ 2365484270 50;
BA_ "GenMsgSendType" BO_ 2566839552 0;
BA_ "GenMsgCycleTime" BO_ 2566839552 1000;
BA_ "GenMsgSendType" BO_ 2566775343 2;
BA_ "GenMsgCycleTime" BO_ 2566775343 1000;
BA_ "GenMsgSendType" BO_ 2566841344 0;
BA_ "GenMsgCycleTime" BO_ 2566841344 1000;
BA_ "GenMsgSendType" BO_ 2566847248 0;
BA_ "GenMsgCycleTime" BO_ 2566847248 1000;
BA_ "GenMsgSendType" BO_ 2566844416 0;
BA_ "GenMsgCycleTime" BO_ 2566844416 100;
BA_ "GenMsgSendType" BO_ 2566844928 0;
BA_ "GenMsgCycleTime" BO_ 2566844928 100;
BA_ "GenMsgSendType" BO_ 2566831360 0;
BA_ "GenMsgCycleTime" BO_ 2566831360 1000;
BA_ "SigType" SG_ 3221225472 TireTemp 1;
BA_ "GenSigStartValue" SG_ 3221225472 TireTemp 9312;
BA_ "SPN" SG_ 3221225472 TireTemp 242;
BA_ "SigType" SG_ 3221225472 TirePress 1;
BA_ "SPN" SG_ 3221225472 TirePress 241;
BA_ "SPN" SG_ 3221225472 FlashRedStopLamp 3039;
BA_ "SPN" SG_ 3221225472 FlashProtectLamp 3041;
BA_ "SPN" SG_ 3221225472 FlashMalfuncIndicatorLamp 3038;
BA_ "SigType" SG_ 3221225472 FlashMalfuncIndicatorLamp 4;
BA_ "SPN" SG_ 3221225472 FlashAmberWarningLamp 3040;
BA_ "SPN" SG_ 3221225472 SPNConversionMethod1 1706;
BA_ "SPN" SG_ 3221225472 FailureModeIdentifier1 1215;
BA_ "SPN" SG_ 3221225472 SPN1 1214;
BA_ "SPN" SG_ 3221225472 MalfunctionIndicatorLampStatus 1213;
BA_ "SigType" SG_ 3221225472 MalfunctionIndicatorLampStatus 4;
BA_ "SPN" SG_ 3221225472 RedStopLampState 623;
BA_ "SigType" SG_ 3221225472 RedStopLampState 4;
BA_ "SPN" SG_ 3221225472 AmberWarningLampStatus 624;
BA_ "SigType" SG_ 3221225472 AmberWarningLampStatus 4;
BA_ "SPN" SG_ 3221225472 ProtectLampStatus 987;
BA_ "SigType" SG_ 3221225472 ProtectLampStatus 4;
BA_ "SPN" SG_ 3221225472 SPN1High 1214;
BA_ "SigType" SG_ 2566836235 TestLimitMinimum 1;
BA_ "SPN" SG_ 2566836235 TestLimitMinimum 1228;
BA_ "SigType" SG_ 2566836235 TestLimitMaximum 1;
BA_ "SPN" SG_ 2566836235 TestLimitMaximum 1227;
BA_ "SigType" SG_ 2566836235 TestValue 1;
BA_ "SPN" SG_ 2566836235 TestValue 1226;
BA_ "SigType" SG_ 2566836235 TestType 1;
BA_ "SPN" SG_ 2566836235 TestType 1225;
BA_ "SigType" SG_ 2566836235 TestIdentifier 1;
BA_ "SPN" SG_ 2566836235 TestIdentifier 1224;
BA_ "SigType" SG_ 2566836224 TestLimitMinimum 1;
BA_ "SPN" SG_ 2566836224 TestLimitMinimum 1228;
BA_ "SigType" SG_ 2566836224 TestLimitMaximum 1;
BA_ "SPN" SG_ 2566836224 TestLimitMaximum 1227;
BA_ "SigType" SG_ 2566836224 TestValue 1;
BA_ "SPN" SG_ 2566836224 TestValue 1226;
BA_ "SigType" SG_ 2566836224 TestType 1;
BA_ "SPN" SG_ 2566836224 TestType 1225;
BA_ "SigType" SG_ 2566836224 TestIdentifier 1;
BA_ "SPN" SG_ 2566836224 TestIdentifier 1224;
BA_ "SigType" SG_ 2560949771 TestLimitMinimum 1;
BA_ "SPN" SG_ 2560949771 TestLimitMinimum 1228;
BA_ "SigType" SG_ 2560949771 TestLimitMaximum 1;
BA_ "SPN" SG_ 2560949771 TestLimitMaximum 1227;
BA_ "SigType" SG_ 2560949771 TestValue 1;
BA_ "SPN" SG_ 2560949771 TestValue 1226;
BA_ "SigType" SG_ 2560949771 SlotId 1;
BA_ "SPN" SG_ 2560949771 SlotId 4109;
BA_ "SigType" SG_ 2560949771 TestIdentifier 1;
BA_ "SPN" SG_ 2560949771 TestIdentifier 1224;
BA_ "SPN" SG_ 2560949771 FailureModeIdentifier1 1215;
BA_ "SPN" SG_ 2560949771 SPN1High 1214;
BA_ "SPN" SG_ 2560949771 SPN1 1214;
BA_ "SigType" SG_ 2560949760 TestLimitMinimum 1;
BA_ "SPN" SG_ 2560949760 TestLimitMinimum 1228;
BA_ "SigType" SG_ 2560949760 TestLimitMaximum 1;
BA_ "SPN" SG_ 2560949760 TestLimitMaximum 1227;
BA_ "SigType" SG_ 2560949760 TestValue 1;
BA_ "SPN" SG_ 2560949760 TestValue 1226;
BA_ "SigType" SG_ 2560949760 SlotId 1;
BA_ "SPN" SG_ 2560949760 SlotId 4109;
BA_ "SigType" SG_ 2560949760 TestIdentifier 1;
BA_ "SPN" SG_ 2560949760 TestIdentifier 1224;
BA_ "SPN" SG_ 2560949760 FailureModeIdentifier1 1215;
BA_ "SPN" SG_ 2560949760 SPN1High 1214;
BA_ "SPN" SG_ 2560949760 SPN1 1214;
BA_ "SigType" SG_ 2566836478 TestLimitMinimum 1;
BA_ "SPN" SG_ 2566836478 TestLimitMinimum 1228;
BA_ "SigType" SG_ 2566836478 TestLimitMaximum 1;
BA_ "SPN" SG_ 2566836478 TestLimitMaximum 1227;
BA_ "SigType" SG_ 2566836478 TestValue 1;
BA_ "SPN" SG_ 2566836478 TestValue 1226;
BA_ "SigType" SG_ 2566836478 TestType 1;
BA_ "SPN" SG_ 2566836478 TestType 1225;
BA_ "SigType" SG_ 2566836478 TestIdentifier 1;
BA_ "SPN" SG_ 2566836478 TestIdentifier 1224;
BA_ "SPN" SG_ 2565078782 SPN1High 1214;
BA_ "SPN" SG_ 2565078782 SPN1 1214;
BA_ "SigType" SG_ 2565078782 TestIdentifier 1;
BA_ "SPN" SG_ 2565078782 TestIdentifier 1224;
BA_ "SPN" SG_ 2565078782 FailureModeIdentifier1 1215;
BA_ "SigType" SG_ 2560950014 TestLimitMinimum 1;
BA_ "SPN" SG_ 2560950014 TestLimitMinimum 1228;
BA_ "SigType" SG_ 2560950014 TestLimitMaximum 1;
BA_ "SPN" SG_ 2560950014 TestLimitMaximum 1227;
BA_ "SigType" SG_ 2560950014 TestValue 1;
BA_ "SPN" SG_ 2560950014 TestValue 1226;
BA_ "SigType" SG_ 2560950014 SlotId 1;
BA_ "SPN" SG_ 2560950014 SlotId 4109;
BA_ "SigType" SG_ 2560950014 TestIdentifier 1;
BA_ "SPN" SG_ 2560950014 TestIdentifier 1224;
BA_ "SPN" SG_ 2560950014 FailureModeIdentifier1 1215;
BA_ "SPN" SG_ 2560950014 SPN1High 1214;
BA_ "SPN" SG_ 2560950014 SPN1 1214;
BA_ "SPN" SG_ 2348941054 TrnsShftSlctorDisplayModeSwitch 2985;
BA_ "SigType" SG_ 2348941054 TrnsShftSlctorDisplayModeSwitch 4;
BA_ "SPN" SG_ 2348941054 TransMode4 1855;
BA_ "SigType" SG_ 2348941054 TransMode4 4;
BA_ "SPN" SG_ 2348941054 TransMode3 1854;
BA_ "SigType" SG_ 2348941054 TransMode3 4;
BA_ "SPN" SG_ 2348941054 TransMode2 1853;
BA_ "SigType" SG_ 2348941054 TransMode2 4;
BA_ "SPN" SG_ 2348941054 TransMode1 1852;
BA_ "SigType" SG_ 2348941054 TransMode1 4;
BA_ "SPN" SG_ 2348941054 DisengageDiffLockRqCentralRear 691;
BA_ "SigType" SG_ 2348941054 DisengageDiffLockRqCentralRear 4;
BA_ "SPN" SG_ 2348941054 DisengageDiffLockRqCentralFront 690;
BA_ "SigType" SG_ 2348941054 DisengageDiffLockRqCentralFront 4;
BA_ "SPN" SG_ 2348941054 DisengageDiffLockRqCentral 689;
BA_ "SigType" SG_ 2348941054 DisengageDiffLockRqCentral 4;
BA_ "SPN" SG_ 2348941054 DisengageDiffLockRqRearAxle2 688;
BA_ "SigType" SG_ 2348941054 DisengageDiffLockRqRearAxle2 4;
BA_ "SPN" SG_ 2348941054 DisengageDiffLockRqRearAxle1 687;
BA_ "SigType" SG_ 2348941054 DisengageDiffLockRqRearAxle1 4;
BA_ "SPN" SG_ 2348941054 DisengageDiffLockRqFrontAxle2 686;
BA_ "SigType" SG_ 2348941054 DisengageDiffLockRqFrontAxle2 4;
BA_ "SPN" SG_ 2348941054 DisengageDiffLockRqFrontAxle1 685;
BA_ "SigType" SG_ 2348941054 DisengageDiffLockRqFrontAxle1 4;
BA_ "SPN" SG_ 2348941054 TransRqedGear 525;
BA_ "SigType" SG_ 2348941054 TransRqedGear 1;
BA_ "SPN" SG_ 2348941054 RqedPercentClutchSlip 684;
BA_ "SigType" SG_ 2348941054 RqedPercentClutchSlip 1;
BA_ "SPN" SG_ 2348941054 DisengageDrivelineRq 683;
BA_ "SigType" SG_ 2348941054 DisengageDrivelineRq 4;
BA_ "SPN" SG_ 2348941054 TorqueConverterLockupDisableRq 682;
BA_ "SigType" SG_ 2348941054 TorqueConverterLockupDisableRq 4;
BA_ "SPN" SG_ 2348941054 TransGearShiftInhibitRq 681;
BA_ "SigType" SG_ 2348941054 TransGearShiftInhibitRq 4;
BA_ "SPN" SG_ 2562981630 IndividualDTCClearControlByte 3034;
BA_ "SPN" SG_ 2562981630 CtrlByteIndicIndividualDTCClear 3035;
BA_ "SPN" SG_ 2562981630 SPN1 1214;
BA_ "SPN" SG_ 2562981630 SPN1High 1214;
BA_ "SPN" SG_ 2562981630 FailureModeIdentifier1 1215;
BA_ "SPN" SG_ 2348875518 ControlPurpose 3350;
BA_ "SigType" SG_ 2348875518 ControlPurpose 4;
BA_ "SPN" SG_ 2348875518 TransmissionRate 3349;
BA_ "SigType" SG_ 2348875518 TransmissionRate 4;
BA_ "SPN" SG_ 2348875518 EngRqedTorque_TorqueLimit 518;
BA_ "SigType" SG_ 2348875518 EngRqedTorque_TorqueLimit 1;
BA_ "SPN" SG_ 2348875518 EngRqedSpeed_SpeedLimit 898;
BA_ "SigType" SG_ 2348875518 EngRqedSpeed_SpeedLimit 1;
BA_ "SPN" SG_ 2348875518 OverrideCtrlModePriority 897;
BA_ "SigType" SG_ 2348875518 OverrideCtrlModePriority 4;
BA_ "SPN" SG_ 2348875518 EngRqedSpeedCtrlConditions 696;
BA_ "SigType" SG_ 2348875518 EngRqedSpeedCtrlConditions 4;
BA_ "SPN" SG_ 2348875518 EngOverrideCtrlMode 695;
BA_ "SigType" SG_ 2348875518 EngOverrideCtrlMode 4;
BA_ "SPN" SG_ 2566842094 LocalHourOffset 1602;
BA_ "SigType" SG_ 2566842094 LocalHourOffset 1;
BA_ "SPN" SG_ 2566842094 LocalMinuteOffset 1601;
BA_ "SigType" SG_ 2566842094 LocalMinuteOffset 1;
BA_ "SPN" SG_ 2566842094 Year 964;
BA_ "SigType" SG_ 2566842094 Year 1;
BA_ "SPN" SG_ 2566842094 Day 962;
BA_ "SigType" SG_ 2566842094 Day 1;
BA_ "SPN" SG_ 2566842094 Month 963;
BA_ "SigType" SG_ 2566842094 Month 1;
BA_ "SPN" SG_ 2566842094 Hours 961;
BA_ "SigType" SG_ 2566842094 Hours 1;
BA_ "SPN" SG_ 2566842094 Minutes 960;
BA_ "SigType" SG_ 2566842094 Minutes 1;
BA_ "SPN" SG_ 2566842094 Seconds 959;
BA_ "SigType" SG_ 2566842094 Seconds 1;
BA_ "SPN" SG_ 2348820752 ControlPurpose 3350;
BA_ "SigType" SG_ 2348820752 ControlPurpose 4;
BA_ "SPN" SG_ 2348820752 TransmissionRate 3349;
BA_ "SigType" SG_ 2348820752 TransmissionRate 4;
BA_ "SPN" SG_ 2348820752 EngRqedTorque_TorqueLimit 518;
BA_ "SigType" SG_ 2348820752 EngRqedTorque_TorqueLimit 1;
BA_ "SPN" SG_ 2348820752 EngRqedSpeed_SpeedLimit 898;
BA_ "SigType" SG_ 2348820752 EngRqedSpeed_SpeedLimit 1;
BA_ "SPN" SG_ 2348820752 OverrideCtrlModePriority 897;
BA_ "SigType" SG_ 2348820752 OverrideCtrlModePriority 4;
BA_ "SPN" SG_ 2348820752 EngRqedSpeedCtrlConditions 696;
BA_ "SigType" SG_ 2348820752 EngRqedSpeedCtrlConditions 4;
BA_ "SPN" SG_ 2348820752 EngOverrideCtrlMode 695;
BA_ "SigType" SG_ 2348820752 EngOverrideCtrlMode 4;
BA_ "SPN" SG_ 2566840592 PercentTorqueAtPeakTorquePoint5 555;
BA_ "SigType" SG_ 2566840592 PercentTorqueAtPeakTorquePoint5 1;
BA_ "SPN" SG_ 2566840592 ReferenceRetarderTorque 556;
BA_ "SigType" SG_ 2566840592 ReferenceRetarderTorque 1;
BA_ "SPN" SG_ 2566840592 RetarderSpeedAtPeakTorquePoint5 547;
BA_ "SigType" SG_ 2566840592 RetarderSpeedAtPeakTorquePoint5 1;
BA_ "SPN" SG_ 2566840592 PercentTorqueAtPoint4 554;
BA_ "SigType" SG_ 2566840592 PercentTorqueAtPoint4 1;
BA_ "SPN" SG_ 2566840592 RetarderSpeedAtPoint4 550;
BA_ "SigType" SG_ 2566840592 RetarderSpeedAtPoint4 1;
BA_ "SPN" SG_ 2566840592 PercentTorqueAtPoint3 553;
BA_ "SigType" SG_ 2566840592 PercentTorqueAtPoint3 1;
BA_ "SPN" SG_ 2566840592 RetarderSpeedAtPoint3 549;
BA_ "SigType" SG_ 2566840592 RetarderSpeedAtPoint3 1;
BA_ "SPN" SG_ 2566840592 PercentTorqueAtMaxSpeedPoint2 552;
BA_ "SigType" SG_ 2566840592 PercentTorqueAtMaxSpeedPoint2 1;
BA_ "SPN" SG_ 2566840592 MaxRetarderSpeedPoint2 548;
BA_ "SigType" SG_ 2566840592 MaxRetarderSpeedPoint2 1;
BA_ "SPN" SG_ 2566840592 PercentTorqueAtIdlePoint1 551;
BA_ "SigType" SG_ 2566840592 PercentTorqueAtIdlePoint1 1;
BA_ "SPN" SG_ 2566840592 RetarderSpeedAtIdlePoint1 546;
BA_ "SigType" SG_ 2566840592 RetarderSpeedAtIdlePoint1 1;
BA_ "SPN" SG_ 2566840592 RetarderCtrlMethod 557;
BA_ "SigType" SG_ 2566840592 RetarderCtrlMethod 1;
BA_ "SPN" SG_ 2566840592 RetarderLocation 902;
BA_ "SigType" SG_ 2566840592 RetarderLocation 4;
BA_ "SPN" SG_ 2566840592 RetarderType 901;
BA_ "SigType" SG_ 2566840592 RetarderType 4;
BA_ "SPN" SG_ 2565865488 RetarderSelectionNonEng 1716;
BA_ "SigType" SG_ 2565865488 RetarderSelectionNonEng 1;
BA_ "SPN" SG_ 2565865488 ActlMxAvlblRtarderPercentTorque 1717;
BA_ "SigType" SG_ 2565865488 ActlMxAvlblRtarderPercentTorque 1;
BA_ "SPN" SG_ 2565865488 DrvrsDmandRetarderPercentTorque 1715;
BA_ "SigType" SG_ 2565865488 DrvrsDmandRetarderPercentTorque 1;
BA_ "GenSigStartValue" SG_ 2565865488 SrcAddrssOfCtrllngDvcFrRtrdrCtrl 14;
BA_ "SPN" SG_ 2565865488 SrcAddrssOfCtrllngDvcFrRtrdrCtrl 1480;
BA_ "SigType" SG_ 2565865488 SrcAddrssOfCtrllngDvcFrRtrdrCtrl 1;
BA_ "SPN" SG_ 2565865488 RetarderRqingBrakeLight 1667;
BA_ "SigType" SG_ 2565865488 RetarderRqingBrakeLight 4;
BA_ "SPN" SG_ 2565865488 EngCoolantLoadIncrease 1082;
BA_ "SigType" SG_ 2565865488 EngCoolantLoadIncrease 4;
BA_ "SPN" SG_ 2565865488 IntendedRetarderPercentTorque 1085;
BA_ "SigType" SG_ 2565865488 IntendedRetarderPercentTorque 1;
BA_ "SPN" SG_ 2565865488 ActualRetarderPercentTorque 520;
BA_ "SigType" SG_ 2565865488 ActualRetarderPercentTorque 1;
BA_ "SPN" SG_ 2565865488 RetarderEnableShiftAssistSwitch 572;
BA_ "SigType" SG_ 2565865488 RetarderEnableShiftAssistSwitch 4;
BA_ "SPN" SG_ 2565865488 RetarderEnableBrakeAssistSwitch 571;
BA_ "SigType" SG_ 2565865488 RetarderEnableBrakeAssistSwitch 4;
BA_ "SPN" SG_ 2565865488 RetarderTorqueMode 900;
BA_ "SigType" SG_ 2565865488 RetarderTorqueMode 4;
BA_ "SPN" SG_ 2348814347 ControlPurpose 3350;
BA_ "SigType" SG_ 2348814347 ControlPurpose 4;
BA_ "SPN" SG_ 2348814347 TransmissionRate 3349;
BA_ "SigType" SG_ 2348814347 TransmissionRate 4;
BA_ "SPN" SG_ 2348814347 EngRqedTorque_TorqueLimit 518;
BA_ "SigType" SG_ 2348814347 EngRqedTorque_TorqueLimit 1;
BA_ "SPN" SG_ 2348814347 EngRqedSpeed_SpeedLimit 898;
BA_ "SigType" SG_ 2348814347 EngRqedSpeed_SpeedLimit 1;
BA_ "SPN" SG_ 2348814347 OverrideCtrlModePriority 897;
BA_ "SigType" SG_ 2348814347 OverrideCtrlModePriority 4;
BA_ "SPN" SG_ 2348814347 EngRqedSpeedCtrlConditions 696;
BA_ "SigType" SG_ 2348814347 EngRqedSpeedCtrlConditions 4;
BA_ "SPN" SG_ 2348814347 EngOverrideCtrlMode 695;
BA_ "SigType" SG_ 2348814347 EngOverrideCtrlMode 4;
BA_ "SPN" SG_ 2348810251 ControlPurpose 3350;
BA_ "SigType" SG_ 2348810251 ControlPurpose 4;
BA_ "SPN" SG_ 2348810251 TransmissionRate 3349;
BA_ "SigType" SG_ 2348810251 TransmissionRate 4;
BA_ "SPN" SG_ 2348810251 EngRqed_TorqueLimit 518;
BA_ "SigType" SG_ 2348810251 EngRqed_TorqueLimit 1;
BA_ "SPN" SG_ 2348810251 EngRqed_SpeedLimit 898;
BA_ "SigType" SG_ 2348810251 EngRqed_SpeedLimit 1;
BA_ "SPN" SG_ 2348810251 OverrideCtrlModePrio 897;
BA_ "SigType" SG_ 2348810251 OverrideCtrlModePrio 4;
BA_ "SPN" SG_ 2348810251 EngRqedSpeedCtrlCond 696;
BA_ "SigType" SG_ 2348810251 EngRqedSpeedCtrlCond 4;
BA_ "SPN" SG_ 2348810251 EngOverrideCtrlMode 695;
BA_ "SigType" SG_ 2348810251 EngOverrideCtrlMode 4;
BA_ "SPN" SG_ 2348820739 ControlPurpose 3350;
BA_ "SigType" SG_ 2348820739 ControlPurpose 4;
BA_ "SPN" SG_ 2348820739 TransmissionRate 3349;
BA_ "SigType" SG_ 2348820739 TransmissionRate 4;
BA_ "SPN" SG_ 2348820739 EngRqedTorque_TorqueLimit 518;
BA_ "SigType" SG_ 2348820739 EngRqedTorque_TorqueLimit 1;
BA_ "SPN" SG_ 2348820739 EngRqedSpeed_SpeedLimit 898;
BA_ "SigType" SG_ 2348820739 EngRqedSpeed_SpeedLimit 1;
BA_ "SPN" SG_ 2348820739 OverrideCtrlModePriority 897;
BA_ "SigType" SG_ 2348820739 OverrideCtrlModePriority 4;
BA_ "SPN" SG_ 2348820739 EngRqedSpeedCtrlConditions 696;
BA_ "SigType" SG_ 2348820739 EngRqedSpeedCtrlConditions 4;
BA_ "SPN" SG_ 2348820739 EngOverrideCtrlMode 695;
BA_ "SigType" SG_ 2348820739 EngOverrideCtrlMode 4;
BA_ "SPN" SG_ 2348820747 ControlPurpose 3350;
BA_ "SigType" SG_ 2348820747 ControlPurpose 4;
BA_ "SPN" SG_ 2348820747 TransmissionRate 3349;
BA_ "SigType" SG_ 2348820747 TransmissionRate 4;
BA_ "SPN" SG_ 2348820747 EngRqedTorque_TorqueLimit 518;
BA_ "SigType" SG_ 2348820747 EngRqedTorque_TorqueLimit 1;
BA_ "SPN" SG_ 2348820747 EngRqedSpeed_SpeedLimit 898;
BA_ "SigType" SG_ 2348820747 EngRqedSpeed_SpeedLimit 1;
BA_ "SPN" SG_ 2348820747 OverrideCtrlModePriority 897;
BA_ "SigType" SG_ 2348820747 OverrideCtrlModePriority 4;
BA_ "SPN" SG_ 2348820747 EngRqedSpeedCtrlConditions 696;
BA_ "SigType" SG_ 2348820747 EngRqedSpeedCtrlConditions 4;
BA_ "SPN" SG_ 2348820747 EngOverrideCtrlMode 695;
BA_ "SigType" SG_ 2348820747 EngOverrideCtrlMode 4;
BA_ "SPN" SG_ 2348810243 ControlPurpose 3350;
BA_ "SigType" SG_ 2348810243 ControlPurpose 4;
BA_ "SPN" SG_ 2348810243 TransmissionRate 3349;
BA_ "SigType" SG_ 2348810243 TransmissionRate 4;
BA_ "SPN" SG_ 2348810243 EngRqed_TorqueLimit 518;
BA_ "SigType" SG_ 2348810243 EngRqed_TorqueLimit 1;
BA_ "SPN" SG_ 2348810243 EngRqed_SpeedLimit 898;
BA_ "SigType" SG_ 2348810243 EngRqed_SpeedLimit 1;
BA_ "SPN" SG_ 2348810243 OverrideCtrlModePrio 897;
BA_ "SigType" SG_ 2348810243 OverrideCtrlModePrio 4;
BA_ "SPN" SG_ 2348810243 EngRqedSpeedCtrlCond 696;
BA_ "SigType" SG_ 2348810243 EngRqedSpeedCtrlCond 4;
BA_ "SPN" SG_ 2348810243 EngOverrideCtrlMode 695;
BA_ "SigType" SG_ 2348810243 EngOverrideCtrlMode 4;
BA_ "SPN" SG_ 2566845952 EngCoolantFilterDiffPress 112;
BA_ "SigType" SG_ 2566845952 EngCoolantFilterDiffPress 1;
BA_ "SPN" SG_ 2566845952 EngExhaustGasTemp 173;
BA_ "SigType" SG_ 2566845952 EngExhaustGasTemp 1;
BA_ "SPN" SG_ 2566845952 EngAirFilter1DiffPress 107;
BA_ "SigType" SG_ 2566845952 EngAirFilter1DiffPress 1;
BA_ "SPN" SG_ 2566845952 EngAirInletPress 106;
BA_ "SigType" SG_ 2566845952 EngAirInletPress 1;
BA_ "SPN" SG_ 2566845952 EngIntakeManifold1Temp 105;
BA_ "SigType" SG_ 2566845952 EngIntakeManifold1Temp 1;
BA_ "SPN" SG_ 2566845952 EngTurboBoostPress 102;
BA_ "SigType" SG_ 2566845952 EngTurboBoostPress 1;
BA_ "SPN" SG_ 2566845952 EngParticulateTrapInletPress 81;
BA_ "SigType" SG_ 2566845952 EngParticulateTrapInletPress 1;
BA_ "SPN" SG_ 2566841600 EngTotalRevolutions 249;
BA_ "SigType" SG_ 2566841600 EngTotalRevolutions 1;
BA_ "SPN" SG_ 2566841600 EngTotalHoursOfOperation 247;
BA_ "SigType" SG_ 2566841600 EngTotalHoursOfOperation 1;
BA_ "SPN" SG_ 2566842927 CargoWeight 181;
BA_ "SigType" SG_ 2566842927 CargoWeight 1;
BA_ "SPN" SG_ 2566842927 TrailerWeight 180;
BA_ "SigType" SG_ 2566842927 TrailerWeight 1;
BA_ "SPN" SG_ 2566842927 AxleWeight 582;
BA_ "SigType" SG_ 2566842927 AxleWeight 1;
BA_ "SPN" SG_ 2566842927 AxleLocation 2928;
BA_ "SigType" SG_ 2566842927 AxleLocation 1;
BA_ "SigType" SG_ 2566843392 VehicleIdentificationNumber 8;
BA_ "SPN" SG_ 2566843392 VehicleIdentificationNumber 237;
BA_ "SPN" SG_ 2566832384 HighResolutionTripDistance 918;
BA_ "SigType" SG_ 2566832384 HighResolutionTripDistance 1;
BA_ "SPN" SG_ 2566832384 HghRslutionTotalVehicleDistance 917;
BA_ "SigType" SG_ 2566832384 HghRslutionTotalVehicleDistance 1;
BA_ "SPN" SG_ 2565867787 LongitudinalAcceleration 1810;
BA_ "SigType" SG_ 2565867787 LongitudinalAcceleration 1;
BA_ "SPN" SG_ 2565867787 LateralAcceleration 1809;
BA_ "SigType" SG_ 2565867787 LateralAcceleration 1;
BA_ "SPN" SG_ 2565867787 YawRate 1808;
BA_ "SigType" SG_ 2565867787 YawRate 1;
BA_ "SPN" SG_ 2565867787 SteerWheelAngleSensorType 1812;
BA_ "SigType" SG_ 2565867787 SteerWheelAngleSensorType 4;
BA_ "SPN" SG_ 2565867787 SteerWheelTurnCounter 1811;
BA_ "SigType" SG_ 2565867787 SteerWheelTurnCounter 4;
BA_ "SPN" SG_ 2565867787 SteerWheelAngle 1807;
BA_ "SigType" SG_ 2565867787 SteerWheelAngle 1;
BA_ "SPN" SG_ 2566803211 YCBrakeCtrlActive 1819;
BA_ "SigType" SG_ 2566803211 YCBrakeCtrlActive 4;
BA_ "SPN" SG_ 2566803211 YCEngCtrlActive 1817;
BA_ "SigType" SG_ 2566803211 YCEngCtrlActive 4;
BA_ "SPN" SG_ 2566803211 ROPBrakeCtrlActive 1818;
BA_ "SigType" SG_ 2566803211 ROPBrakeCtrlActive 4;
BA_ "SPN" SG_ 2566803211 ROPEngCtrlActive 1816;
BA_ "SigType" SG_ 2566803211 ROPEngCtrlActive 4;
BA_ "SPN" SG_ 2566803211 VDCBrakeLightRq 1815;
BA_ "SigType" SG_ 2566803211 VDCBrakeLightRq 4;
BA_ "SPN" SG_ 2566803211 VDCFullyOperational 1814;
BA_ "SigType" SG_ 2566803211 VDCFullyOperational 4;
BA_ "SPN" SG_ 2566803211 VDCInformationSignal 1813;
BA_ "SigType" SG_ 2566803211 VDCInformationSignal 4;
BA_ "SPN" SG_ 2566840320 TotalVehicleDistance 245;
BA_ "SigType" SG_ 2566840320 TotalVehicleDistance 1;
BA_ "SPN" SG_ 2566840320 TripDistance 244;
BA_ "SigType" SG_ 2566840320 TripDistance 1;
BA_ "SPN" SG_ 2561605374 ReferenceTirePressSetting 3193;
BA_ "SigType" SG_ 2561605374 ReferenceTirePressSetting 1;
BA_ "SPN" SG_ 2561605374 TireLocation 929;
BA_ "SigType" SG_ 2561605374 TireLocation 1;
BA_ "SPN" SG_ 2566764851 ReferenceTirePress 3191;
BA_ "SigType" SG_ 2566764851 ReferenceTirePress 1;
BA_ "SPN" SG_ 2566764851 TireLocation 929;
BA_ "SigType" SG_ 2566764851 TireLocation 1;
BA_ "SPN" SG_ 2566845491 TireTemp_21 521121;
BA_ "GenSigStartValue" SG_ 2566845491 TireTemp_21 9312;
BA_ "SigType" SG_ 2566845491 TireTemp_21 1;
BA_ "SPN" SG_ 2566845491 TireTemp_20 521120;
BA_ "GenSigStartValue" SG_ 2566845491 TireTemp_20 9312;
BA_ "SigType" SG_ 2566845491 TireTemp_20 1;
BA_ "SPN" SG_ 2566845491 TireTemp_11 521111;
BA_ "GenSigStartValue" SG_ 2566845491 TireTemp_11 9312;
BA_ "SigType" SG_ 2566845491 TireTemp_11 1;
BA_ "SPN" SG_ 2566845491 TireTemp_10 521110;
BA_ "GenSigStartValue" SG_ 2566845491 TireTemp_10 9312;
BA_ "SigType" SG_ 2566845491 TireTemp_10 1;
BA_ "SPN" SG_ 2566845491 TireTemp_01 521101;
BA_ "GenSigStartValue" SG_ 2566845491 TireTemp_01 9312;
BA_ "SigType" SG_ 2566845491 TireTemp_01 1;
BA_ "SPN" SG_ 2566845491 TireTemp_00 521100;
BA_ "GenSigStartValue" SG_ 2566845491 TireTemp_00 9312;
BA_ "SigType" SG_ 2566845491 TireTemp_00 1;
BA_ "SPN" SG_ 2566845491 TirePressThresholdDetection_21 521621;
BA_ "GenSigILSupport" SG_ 2566845491 TirePressThresholdDetection_21 1;
BA_ "SigType" SG_ 2566845491 TirePressThresholdDetection_21 4;
BA_ "SPN" SG_ 2566845491 TirePressThresholdDetection_20 521620;
BA_ "GenSigILSupport" SG_ 2566845491 TirePressThresholdDetection_20 1;
BA_ "SigType" SG_ 2566845491 TirePressThresholdDetection_20 4;
BA_ "SPN" SG_ 2566845491 TirePressThresholdDetection_11 521611;
BA_ "GenSigILSupport" SG_ 2566845491 TirePressThresholdDetection_11 1;
BA_ "SigType" SG_ 2566845491 TirePressThresholdDetection_11 4;
BA_ "SPN" SG_ 2566845491 TirePressThresholdDetection_10 521610;
BA_ "GenSigILSupport" SG_ 2566845491 TirePressThresholdDetection_10 1;
BA_ "SigType" SG_ 2566845491 TirePressThresholdDetection_10 4;
BA_ "SPN" SG_ 2566845491 TirePressThresholdDetection_01 521601;
BA_ "GenSigILSupport" SG_ 2566845491 TirePressThresholdDetection_01 1;
BA_ "SigType" SG_ 2566845491 TirePressThresholdDetection_01 4;
BA_ "GenSigILSupport" SG_ 2566845491 TirePressThresholdDetection_00 1;
BA_ "SPN" SG_ 2566845491 TirePressThresholdDetection_00 521600;
BA_ "SigType" SG_ 2566845491 TirePressThresholdDetection_00 4;
BA_ "SPN" SG_ 2566845491 TirePress_21 521021;
BA_ "SigType" SG_ 2566845491 TirePress_21 1;
BA_ "SPN" SG_ 2566845491 TirePress_20 521020;
BA_ "SigType" SG_ 2566845491 TirePress_20 1;
BA_ "SPN" SG_ 2566845491 TirePress_11 521011;
BA_ "SigType" SG_ 2566845491 TirePress_11 1;
BA_ "SPN" SG_ 2566845491 TirePress_10 521010;
BA_ "SigType" SG_ 2566845491 TirePress_10 1;
BA_ "SPN" SG_ 2566845491 TirePress_01 521001;
BA_ "SigType" SG_ 2566845491 TirePress_01 1;
BA_ "SPN" SG_ 2566845491 TirePress_00 521000;
BA_ "SigType" SG_ 2566845491 TirePress_00 1;
BA_ "SPN" SG_ 2566845491 TireAirLeakageRate_21 521521;
BA_ "GenSigILSupport" SG_ 2566845491 TireAirLeakageRate_21 1;
BA_ "SigType" SG_ 2566845491 TireAirLeakageRate_21 1;
BA_ "SPN" SG_ 2566845491 TireAirLeakageRate_20 521520;
BA_ "GenSigILSupport" SG_ 2566845491 TireAirLeakageRate_20 1;
BA_ "SigType" SG_ 2566845491 TireAirLeakageRate_20 1;
BA_ "SPN" SG_ 2566845491 TireAirLeakageRate_11 521511;
BA_ "GenSigILSupport" SG_ 2566845491 TireAirLeakageRate_11 1;
BA_ "SigType" SG_ 2566845491 TireAirLeakageRate_11 1;
BA_ "SPN" SG_ 2566845491 TireAirLeakageRate_10 521510;
BA_ "GenSigILSupport" SG_ 2566845491 TireAirLeakageRate_10 1;
BA_ "SigType" SG_ 2566845491 TireAirLeakageRate_10 1;
BA_ "SPN" SG_ 2566845491 TireAirLeakageRate_01 521501;
BA_ "GenSigILSupport" SG_ 2566845491 TireAirLeakageRate_01 1;
BA_ "SigType" SG_ 2566845491 TireAirLeakageRate_01 1;
BA_ "GenSigILSupport" SG_ 2566845491 TireAirLeakageRate_00 1;
BA_ "SPN" SG_ 2566845491 TireAirLeakageRate_00 521500;
BA_ "SigType" SG_ 2566845491 TireAirLeakageRate_00 1;
BA_ "SPN" SG_ 2566845491 CTIWheelSensorStatus_21 521421;
BA_ "GenSigILSupport" SG_ 2566845491 CTIWheelSensorStatus_21 1;
BA_ "SigType" SG_ 2566845491 CTIWheelSensorStatus_21 4;
BA_ "SPN" SG_ 2566845491 CTIWheelSensorStatus_20 521420;
BA_ "GenSigILSupport" SG_ 2566845491 CTIWheelSensorStatus_20 1;
BA_ "SigType" SG_ 2566845491 CTIWheelSensorStatus_20 4;
BA_ "SPN" SG_ 2566845491 CTIWheelSensorStatus_11 521411;
BA_ "GenSigILSupport" SG_ 2566845491 CTIWheelSensorStatus_11 1;
BA_ "SigType" SG_ 2566845491 CTIWheelSensorStatus_11 4;
BA_ "SPN" SG_ 2566845491 CTIWheelSensorStatus_10 521410;
BA_ "GenSigILSupport" SG_ 2566845491 CTIWheelSensorStatus_10 1;
BA_ "SigType" SG_ 2566845491 CTIWheelSensorStatus_10 4;
BA_ "SPN" SG_ 2566845491 CTIWheelSensorStatus_01 521401;
BA_ "GenSigILSupport" SG_ 2566845491 CTIWheelSensorStatus_01 1;
BA_ "SigType" SG_ 2566845491 CTIWheelSensorStatus_01 4;
BA_ "GenSigILSupport" SG_ 2566845491 CTIWheelSensorStatus_00 1;
BA_ "SPN" SG_ 2566845491 CTIWheelSensorStatus_00 521400;
BA_ "SigType" SG_ 2566845491 CTIWheelSensorStatus_00 4;
BA_ "SPN" SG_ 2566845491 CTIWheelEndElectricalFault_21 521221;
BA_ "GenSigILSupport" SG_ 2566845491 CTIWheelEndElectricalFault_21 1;
BA_ "SigType" SG_ 2566845491 CTIWheelEndElectricalFault_21 4;
BA_ "SPN" SG_ 2566845491 CTIWheelEndElectricalFault_20 521220;
BA_ "GenSigILSupport" SG_ 2566845491 CTIWheelEndElectricalFault_20 1;
BA_ "SigType" SG_ 2566845491 CTIWheelEndElectricalFault_20 4;
BA_ "SPN" SG_ 2566845491 CTIWheelEndElectricalFault_11 521211;
BA_ "GenSigILSupport" SG_ 2566845491 CTIWheelEndElectricalFault_11 1;
BA_ "SigType" SG_ 2566845491 CTIWheelEndElectricalFault_11 4;
BA_ "SPN" SG_ 2566845491 CTIWheelEndElectricalFault_10 521210;
BA_ "GenSigILSupport" SG_ 2566845491 CTIWheelEndElectricalFault_10 1;
BA_ "SigType" SG_ 2566845491 CTIWheelEndElectricalFault_10 4;
BA_ "SPN" SG_ 2566845491 CTIWheelEndElectricalFault_01 521201;
BA_ "GenSigILSupport" SG_ 2566845491 CTIWheelEndElectricalFault_01 1;
BA_ "SigType" SG_ 2566845491 CTIWheelEndElectricalFault_01 4;
BA_ "GenSigILSupport" SG_ 2566845491 CTIWheelEndElectricalFault_00 1;
BA_ "SPN" SG_ 2566845491 CTIWheelEndElectricalFault_00 521200;
BA_ "SigType" SG_ 2566845491 CTIWheelEndElectricalFault_00 4;
BA_ "SPN" SG_ 2566845491 CTITireStatus_21 521321;
BA_ "GenSigILSupport" SG_ 2566845491 CTITireStatus_21 1;
BA_ "SigType" SG_ 2566845491 CTITireStatus_21 4;
BA_ "SPN" SG_ 2566845491 CTITireStatus_20 521320;
BA_ "GenSigILSupport" SG_ 2566845491 CTITireStatus_20 1;
BA_ "SigType" SG_ 2566845491 CTITireStatus_20 4;
BA_ "SPN" SG_ 2566845491 CTITireStatus_11 521311;
BA_ "GenSigILSupport" SG_ 2566845491 CTITireStatus_11 1;
BA_ "SigType" SG_ 2566845491 CTITireStatus_11 4;
BA_ "SPN" SG_ 2566845491 CTITireStatus_10 521310;
BA_ "GenSigILSupport" SG_ 2566845491 CTITireStatus_10 1;
BA_ "SigType" SG_ 2566845491 CTITireStatus_10 4;
BA_ "SPN" SG_ 2566845491 CTITireStatus_01 521301;
BA_ "GenSigILSupport" SG_ 2566845491 CTITireStatus_01 1;
BA_ "SigType" SG_ 2566845491 CTITireStatus_01 4;
BA_ "GenSigILSupport" SG_ 2566845491 CTITireStatus_00 1;
BA_ "SPN" SG_ 2566845491 CTITireStatus_00 521300;
BA_ "SigType" SG_ 2566845491 CTITireStatus_00 4;
BA_ "SPN" SG_ 2566845491 TireLocation 929;
BA_ "SigType" SG_ 2566845491 TireLocation 1;
BA_ "SPN" SG_ 2566841879 LocalHourOffset 1602;
BA_ "SigType" SG_ 2566841879 LocalHourOffset 1;
BA_ "SPN" SG_ 2566841879 LocalMinuteOffset 1601;
BA_ "SigType" SG_ 2566841879 LocalMinuteOffset 1;
BA_ "SPN" SG_ 2566841879 Year 964;
BA_ "SigType" SG_ 2566841879 Year 1;
BA_ "SPN" SG_ 2566841879 Day 962;
BA_ "SigType" SG_ 2566841879 Day 1;
BA_ "SPN" SG_ 2566841879 Month 963;
BA_ "SigType" SG_ 2566841879 Month 1;
BA_ "SPN" SG_ 2566841879 Hours 961;
BA_ "SigType" SG_ 2566841879 Hours 1;
BA_ "SPN" SG_ 2566841879 Minutes 960;
BA_ "SigType" SG_ 2566841879 Minutes 1;
BA_ "SPN" SG_ 2566841879 Seconds 959;
BA_ "SigType" SG_ 2566841879 Seconds 1;
BA_ "SPN" SG_ 2365484270 TachographVehicleSpeed 1624;
BA_ "SigType" SG_ 2365484270 TachographVehicleSpeed 1;
BA_ "SPN" SG_ 2365484270 TachographOutputShaftSpeed 1623;
BA_ "SigType" SG_ 2365484270 TachographOutputShaftSpeed 1;
BA_ "SPN" SG_ 2365484270 DirectionIndicator 1619;
BA_ "SigType" SG_ 2365484270 DirectionIndicator 4;
BA_ "SPN" SG_ 2365484270 TachographPerformance 1620;
BA_ "SigType" SG_ 2365484270 TachographPerformance 4;
BA_ "SPN" SG_ 2365484270 HandlingInformation 1621;
BA_ "SigType" SG_ 2365484270 HandlingInformation 4;
BA_ "SPN" SG_ 2365484270 SystemEvent 1622;
BA_ "SigType" SG_ 2365484270 SystemEvent 4;
BA_ "SPN" SG_ 2365484270 DriverCardDriver2 1616;
BA_ "SigType" SG_ 2365484270 DriverCardDriver2 4;
BA_ "SPN" SG_ 2365484270 Driver2TimeRelatedStates 1618;
BA_ "SigType" SG_ 2365484270 Driver2TimeRelatedStates 4;
BA_ "SPN" SG_ 2365484270 Overspeed 1614;
BA_ "SigType" SG_ 2365484270 Overspeed 4;
BA_ "SPN" SG_ 2365484270 DriverCardDriver1 1615;
BA_ "SigType" SG_ 2365484270 DriverCardDriver1 4;
BA_ "SPN" SG_ 2365484270 Driver1TimeRelatedStates 1617;
BA_ "SigType" SG_ 2365484270 Driver1TimeRelatedStates 4;
BA_ "SPN" SG_ 2365484270 DriveRecognize 1611;
BA_ "SigType" SG_ 2365484270 DriveRecognize 4;
BA_ "SPN" SG_ 2365484270 Driver2WorkingState 1613;
BA_ "SigType" SG_ 2365484270 Driver2WorkingState 4;
BA_ "SPN" SG_ 2365484270 Driver1WorkingState 1612;
BA_ "SigType" SG_ 2365484270 Driver1WorkingState 4;
BA_ "SPN" SG_ 2566802179 TransTorqueLimit 1845;
BA_ "SigType" SG_ 2566802179 TransTorqueLimit 1;
BA_ "SPN" SG_ 2566840835 TransGearRatio 581;
BA_ "SigType" SG_ 2566840835 TransGearRatio 1;
BA_ "SPN" SG_ 2566840835 NumberOfForwardGearRatios 957;
BA_ "SigType" SG_ 2566840835 NumberOfForwardGearRatios 1;
BA_ "SPN" SG_ 2566840835 NumberOfReverseGearRatios 958;
BA_ "SigType" SG_ 2566840835 NumberOfReverseGearRatios 1;
BA_ "SPN" SG_ 2566839552 EngTurboOilLevelSwitch 1665;
BA_ "SigType" SG_ 2566839552 EngTurboOilLevelSwitch 4;
BA_ "SPN" SG_ 2566839552 EngTurbo1Speed 103;
BA_ "SigType" SG_ 2566839552 EngTurbo1Speed 1;
BA_ "SPN" SG_ 2566839552 EngTurboLubeOilPress1 104;
BA_ "SigType" SG_ 2566839552 EngTurboLubeOilPress1 1;
BA_ "SPN" SG_ 2566775343 AirSuspensionSupplyPressRq 2608;
BA_ "SigType" SG_ 2566775343 AirSuspensionSupplyPressRq 1;
BA_ "SPN" SG_ 2566775343 AuxEquipmentSupplyPressRq 2607;
BA_ "SigType" SG_ 2566775343 AuxEquipmentSupplyPressRq 1;
BA_ "SPN" SG_ 2566775343 ServiceBrakeAirPressRqCircuit2 2606;
BA_ "SigType" SG_ 2566775343 ServiceBrakeAirPressRqCircuit2 1;
BA_ "SPN" SG_ 2566775343 ServiceBrakeAirPressRqCircuit1 2605;
BA_ "SigType" SG_ 2566775343 ServiceBrakeAirPressRqCircuit1 1;
BA_ "SPN" SG_ 2566775343 ParkingAnd_OrTrailerAirPressRq 2604;
BA_ "SigType" SG_ 2566775343 ParkingAnd_OrTrailerAirPressRq 1;
BA_ "SPN" SG_ 2566775343 PneumaticSupplyPressRq 2603;
BA_ "SigType" SG_ 2566775343 PneumaticSupplyPressRq 1;
BA_ "SigType" SG_ 2566839038 SoftwareID3 8;
BA_ "SPN" SG_ 2566839038 SoftwareID3 234;
BA_ "SigType" SG_ 2566839038 SoftwareID2 8;
BA_ "SPN" SG_ 2566839038 SoftwareID2 234;
BA_ "SigType" SG_ 2566839038 SoftwareID1 8;
BA_ "SPN" SG_ 2566839038 SoftwareID1 234;
BA_ "SPN" SG_ 2566839038 NmbrOfSftwrIdentificationFields 965;
BA_ "SigType" SG_ 2566839038 NmbrOfSftwrIdentificationFields 1;
BA_ "SPN" SG_ 2566841344 EngOverspeedTest 2812;
BA_ "SigType" SG_ 2566841344 EngOverspeedTest 4;
BA_ "SPN" SG_ 2566841344 EngAirShutoffCmdStatus 2813;
BA_ "SigType" SG_ 2566841344 EngAirShutoffCmdStatus 4;
BA_ "SPN" SG_ 2566841344 EngAlarmOutputCmdStatus 2814;
BA_ "SigType" SG_ 2566841344 EngAlarmOutputCmdStatus 4;
BA_ "SPN" SG_ 2566841344 EngAlarmAcknowledge 2815;
BA_ "SigType" SG_ 2566841344 EngAlarmAcknowledge 4;
BA_ "SPN" SG_ 2566841344 EngProtectionSystemConfig 1111;
BA_ "SigType" SG_ 2566841344 EngProtectionSystemConfig 4;
BA_ "SPN" SG_ 2566841344 EngProtectionSystemTimerState 1107;
BA_ "SigType" SG_ 2566841344 EngProtectionSystemTimerState 4;
BA_ "SPN" SG_ 2566841344 EngPrtectionSystemTimerOverride 1108;
BA_ "SigType" SG_ 2566841344 EngPrtectionSystemTimerOverride 4;
BA_ "SPN" SG_ 2566841344 EngPrtctnSystmApprchingShutdown 1109;
BA_ "SigType" SG_ 2566841344 EngPrtctnSystmApprchingShutdown 4;
BA_ "SPN" SG_ 2566841344 EngPrtctionSystemHasShutdownEng 1110;
BA_ "SigType" SG_ 2566841344 EngPrtctionSystemHasShutdownEng 4;
BA_ "SPN" SG_ 2566841344 EngWaitToStartLamp 1081;
BA_ "SigType" SG_ 2566841344 EngWaitToStartLamp 4;
BA_ "SPN" SG_ 2566841344 RefrigerantHighPressSwitch 605;
BA_ "SigType" SG_ 2566841344 RefrigerantHighPressSwitch 4;
BA_ "SPN" SG_ 2566841344 RefrigerantLowPressSwitch 875;
BA_ "SigType" SG_ 2566841344 RefrigerantLowPressSwitch 4;
BA_ "SPN" SG_ 2566841344 A_CHighPressFanSwitch 985;
BA_ "SigType" SG_ 2566841344 A_CHighPressFanSwitch 4;
BA_ "SPN" SG_ 2566841344 EngIdleShutdownTimerFunction 591;
BA_ "SigType" SG_ 2566841344 EngIdleShutdownTimerFunction 4;
BA_ "SPN" SG_ 2566841344 EngIdleShutdownTimerState 590;
BA_ "SigType" SG_ 2566841344 EngIdleShutdownTimerState 4;
BA_ "SPN" SG_ 2566841344 EngIdleShutdownTimerOverride 592;
BA_ "SigType" SG_ 2566841344 EngIdleShutdownTimerOverride 4;
BA_ "SPN" SG_ 2566841344 EngIdleShutdownDriverAlertMode 594;
BA_ "SigType" SG_ 2566841344 EngIdleShutdownDriverAlertMode 4;
BA_ "SPN" SG_ 2566841344 EngIdleShutdownHasShutdownEng 593;
BA_ "SigType" SG_ 2566841344 EngIdleShutdownHasShutdownEng 4;
BA_ "SPN" SG_ 2566832382 ServiceComponentIdentificationB 912;
BA_ "SigType" SG_ 2566832382 ServiceComponentIdentificationB 1;
BA_ "SPN" SG_ 2566832382 ServiceComponentIdentificationA 911;
BA_ "SigType" SG_ 2566832382 ServiceComponentIdentificationA 1;
BA_ "SPN" SG_ 2566832382 SrvceDelay_OperationalTimeBased 916;
BA_ "SigType" SG_ 2566832382 SrvceDelay_OperationalTimeBased 1;
BA_ "SPN" SG_ 2566832382 ServiceDelay_CalendarTimeBased 915;
BA_ "SigType" SG_ 2566832382 ServiceDelay_CalendarTimeBased 1;
BA_ "SPN" SG_ 2566832382 ServiceDistance 914;
BA_ "SigType" SG_ 2566832382 ServiceDistance 1;
BA_ "SPN" SG_ 2566832382 ServiceComponentIdentification 1584;
BA_ "SigType" SG_ 2566832382 ServiceComponentIdentification 1;
BA_ "SPN" SG_ 2566847248 HydRetarderOilTemp 120;
BA_ "SigType" SG_ 2566847248 HydRetarderOilTemp 1;
BA_ "SPN" SG_ 2566847248 HydRetarderPress 119;
BA_ "SigType" SG_ 2566847248 HydRetarderPress 1;
BA_ "SPN" SG_ 2631855639 EngBuildHoursReset 1211;
BA_ "SigType" SG_ 2631855639 EngBuildHoursReset 4;
BA_ "SPN" SG_ 2631855639 ServiceComponentIdentification 1584;
BA_ "SigType" SG_ 2631855639 ServiceComponentIdentification 1;
BA_ "SPN" SG_ 2631855639 TripGroup2Proprietary 989;
BA_ "SigType" SG_ 2631855639 TripGroup2Proprietary 4;
BA_ "SPN" SG_ 2631855639 TripGroup1 988;
BA_ "SigType" SG_ 2631855639 TripGroup1 4;
BA_ "SPN" SG_ 2566840617 PercentTorqueAtPeakTorquePoint5 555;
BA_ "SigType" SG_ 2566840617 PercentTorqueAtPeakTorquePoint5 1;
BA_ "SPN" SG_ 2566840617 ReferenceRetarderTorque 556;
BA_ "SigType" SG_ 2566840617 ReferenceRetarderTorque 1;
BA_ "SPN" SG_ 2566840617 RetarderSpeedAtPeakTorquePoint5 547;
BA_ "SigType" SG_ 2566840617 RetarderSpeedAtPeakTorquePoint5 1;
BA_ "SPN" SG_ 2566840617 PercentTorqueAtPoint4 554;
BA_ "SigType" SG_ 2566840617 PercentTorqueAtPoint4 1;
BA_ "SPN" SG_ 2566840617 RetarderSpeedAtPoint4 550;
BA_ "SigType" SG_ 2566840617 RetarderSpeedAtPoint4 1;
BA_ "SPN" SG_ 2566840617 PercentTorqueAtPoint3 553;
BA_ "SigType" SG_ 2566840617 PercentTorqueAtPoint3 1;
BA_ "SPN" SG_ 2566840617 RetarderSpeedAtPoint3 549;
BA_ "SigType" SG_ 2566840617 RetarderSpeedAtPoint3 1;
BA_ "SPN" SG_ 2566840617 PercentTorqueAtMaxSpeedPoint2 552;
BA_ "SigType" SG_ 2566840617 PercentTorqueAtMaxSpeedPoint2 1;
BA_ "SPN" SG_ 2566840617 MaxRetarderSpeedPoint2 548;
BA_ "SigType" SG_ 2566840617 MaxRetarderSpeedPoint2 1;
BA_ "SPN" SG_ 2566840617 PercentTorqueAtIdlePoint1 551;
BA_ "SigType" SG_ 2566840617 PercentTorqueAtIdlePoint1 1;
BA_ "SPN" SG_ 2566840617 RetarderSpeedAtIdlePoint1 546;
BA_ "SigType" SG_ 2566840617 RetarderSpeedAtIdlePoint1 1;
BA_ "SPN" SG_ 2566840617 RetarderCtrlMethod 557;
BA_ "SigType" SG_ 2566840617 RetarderCtrlMethod 1;
BA_ "SPN" SG_ 2566840617 RetarderLocation 902;
BA_ "SigType" SG_ 2566840617 RetarderLocation 4;
BA_ "SPN" SG_ 2566840617 RetarderType 901;
BA_ "SigType" SG_ 2566840617 RetarderType 4;
BA_ "SPN" SG_ 2566844416 OperatorPTOMemorySelectSwitch 2897;
BA_ "SigType" SG_ 2566844416 OperatorPTOMemorySelectSwitch 4;
BA_ "SPN" SG_ 2566844416 EngPTOAccelerateSwitch 981;
BA_ "SigType" SG_ 2566844416 EngPTOAccelerateSwitch 4;
BA_ "SPN" SG_ 2566844416 EngPTOResumeSwitch 982;
BA_ "SigType" SG_ 2566844416 EngPTOResumeSwitch 4;
BA_ "SPN" SG_ 2566844416 EngPTOCoast_DecelerateSwitch 983;
BA_ "SigType" SG_ 2566844416 EngPTOCoast_DecelerateSwitch 4;
BA_ "SPN" SG_ 2566844416 EngPTOSetSwitch 984;
BA_ "SigType" SG_ 2566844416 EngPTOSetSwitch 4;
BA_ "SPN" SG_ 2566844416 EngRmtPTOVriableSpeedCtrlSwitch 978;
BA_ "SigType" SG_ 2566844416 EngRmtPTOVriableSpeedCtrlSwitch 4;
BA_ "SPN" SG_ 2566844416 EngRmtPTOPrprgrmmdSpdCtrlSwitch 979;
BA_ "SigType" SG_ 2566844416 EngRmtPTOPrprgrmmdSpdCtrlSwitch 4;
BA_ "SPN" SG_ 2566844416 EngPTOEnableSwitch 980;
BA_ "SigType" SG_ 2566844416 EngPTOEnableSwitch 4;
BA_ "SPN" SG_ 2566844416 PowerTakeoffSetSpeed 187;
BA_ "SigType" SG_ 2566844416 PowerTakeoffSetSpeed 1;
BA_ "SPN" SG_ 2566844416 PowerTakeoffSpeed 186;
BA_ "SigType" SG_ 2566844416 PowerTakeoffSpeed 1;
BA_ "SPN" SG_ 2566844416 PowerTakeoffOilTemp 90;
BA_ "SigType" SG_ 2566844416 PowerTakeoffOilTemp 1;
BA_ "SPN" SG_ 2566844416 RmtPTOPrprgrmmdSpeedCtrlSwitch2 3447;
BA_ "SigType" SG_ 2566844416 RmtPTOPrprgrmmdSpeedCtrlSwitch2 4;
BA_ "SPN" SG_ 2566844416 AuxInputIgnoreSwitch 3448;
BA_ "SigType" SG_ 2566844416 AuxInputIgnoreSwitch 4;
BA_ "SPN" SG_ 2566844928 EngAverageFuelEconomy 185;
BA_ "SigType" SG_ 2566844928 EngAverageFuelEconomy 1;
BA_ "SPN" SG_ 2566844928 EngInstantaneousFuelEconomy 184;
BA_ "SigType" SG_ 2566844928 EngInstantaneousFuelEconomy 1;
BA_ "SPN" SG_ 2566844928 EngFuelRate 183;
BA_ "SigType" SG_ 2566844928 EngFuelRate 1;
BA_ "SPN" SG_ 2566844928 EngThrottlePos 51;
BA_ "SigType" SG_ 2566844928 EngThrottlePos 1;
BA_ "SPN" SG_ 2566842624 EngTotalFuelUsed 250;
BA_ "SigType" SG_ 2566842624 EngTotalFuelUsed 1;
BA_ "SPN" SG_ 2566842624 EngTripFuel 182;
BA_ "SigType" SG_ 2566842624 EngTripFuel 1;
BA_ "SPN" SG_ 2566831360 FanSpeed 1639;
BA_ "SigType" SG_ 2566831360 FanSpeed 1;
BA_ "SPN" SG_ 2566831360 FanDriveState 977;
BA_ "SigType" SG_ 2566831360 FanDriveState 4;
BA_ "SPN" SG_ 2566831360 EstPercentFanSpeed 975;
BA_ "SigType" SG_ 2566831360 EstPercentFanSpeed 1;
VAL_ 3221225472 FailureModeIdentifier5 31 "Not available" 19 "Received network data in error" 18 "Below normal (moderately severe)" 17 "Below normal (least severe)" 16 "Above normal (moderately severe)" 15 "Above normal (least severe)" 14 "Special intstructions" 13 "Out of calibration" 12 "Bad intelligent device" 11 "Root cause not known" 10 "Abnormal rate of change" 9 "Abnormal update rate" 8 "Abnormal frequency" 7 "Mechanical system not responding" 6 "Current above normal" 5 "Current below normal" 4 "Voltage below normal" 3 "Voltage above normal" 2 "Data erratic" 1 "Below normal (most severe)" 0 "Above normal (most severe)" ;
VAL_ 3221225472 FailureModeIdentifier4 31 "Not available" 19 "Received network data in error" 18 "Below normal (moderately severe)" 17 "Below normal (least severe)" 16 "Above normal (moderately severe)" 15 "Above normal (least severe)" 14 "Special intstructions" 13 "Out of calibration" 12 "Bad intelligent device" 11 "Root cause not known" 10 "Abnormal rate of change" 9 "Abnormal update rate" 8 "Abnormal frequency" 7 "Mechanical system not responding" 6 "Current above normal" 5 "Current below normal" 4 "Voltage below normal" 3 "Voltage above normal" 2 "Data erratic" 1 "Below normal (most severe)" 0 "Above normal (most severe)" ;
VAL_ 3221225472 FlashRedStopLamp 3 "Unavailable / Do Not Flash" 2 "Reserved" 1 "Fast Flash" 0 "Slow Flash" ;
VAL_ 3221225472 FlashProtectLamp 3 "Unavailable / Do Not Flash" 2 "Reserved" 1 "Fast Flash" 0 "Slow Flash" ;
VAL_ 3221225472 FlashMalfuncIndicatorLamp 3 "Unavailable / Do Not Flash" 2 "Reserved" 1 "Fast Flash" 0 "Slow Flash" ;
VAL_ 3221225472 FlashAmberWarningLamp 3 "Unavailable / Do Not Flash" 2 "Reserved" 1 "Fast Flash" 0 "Slow Flash" ;
VAL_ 3221225472 FailureModeIdentifier3 31 "Not available" 19 "Received network data in error" 18 "Below normal (moderately severe)" 17 "Below normal (least severe)" 16 "Above normal (moderately severe)" 15 "Above normal (least severe)" 14 "Special intstructions" 13 "Out of calibration" 12 "Bad intelligent device" 11 "Root cause not known" 10 "Abnormal rate of change" 9 "Abnormal update rate" 8 "Abnormal frequency" 7 "Mechanical system not responding" 6 "Current above normal" 5 "Current below normal" 4 "Voltage below normal" 3 "Voltage above normal" 2 "Data erratic" 1 "Below normal (most severe)" 0 "Above normal (most severe)" ;
VAL_ 3221225472 FailureModeIdentifier2 31 "Not available" 19 "Received network data in error" 18 "Below normal (moderately severe)" 17 "Below normal (least severe)" 16 "Above normal (moderately severe)" 15 "Above normal (least severe)" 14 "Special intstructions" 13 "Out of calibration" 12 "Bad intelligent device" 11 "Root cause not known" 10 "Abnormal rate of change" 9 "Abnormal update rate" 8 "Abnormal frequency" 7 "Mechanical system not responding" 6 "Current above normal" 5 "Current below normal" 4 "Voltage below normal" 3 "Voltage above normal" 2 "Data erratic" 1 "Below normal (most severe)" 0 "Above normal (most severe)" ;
VAL_ 3221225472 FailureModeIdentifier1 31 "Not available" 19 "Received network data in error" 18 "Below normal (moderately severe)" 17 "Below normal (least severe)" 16 "Above normal (moderately severe)" 15 "Above normal (least severe)" 14 "Special intstructions" 13 "Out of calibration" 12 "Bad intelligent device" 11 "Root cause not known" 10 "Abnormal rate of change" 9 "Abnormal update rate" 8 "Abnormal frequency" 7 "Mechanical system not responding" 6 "Current above normal" 5 "Current below normal" 4 "Voltage below normal" 3 "Voltage above normal" 2 "Data erratic" 1 "Below normal (most severe)" 0 "Above normal (most severe)" ;
VAL_ 3221225472 MalfunctionIndicatorLampStatus 3 "Not available" 2 "Reserved" 1 "Lamp on" 0 "Lamp off" ;
VAL_ 3221225472 RedStopLampState 3 "Not available" 2 "Reserved" 1 "Lamp on" 0 "Lamp off" ;
VAL_ 3221225472 AmberWarningLampStatus 3 "Not available" 2 "Reserved" 1 "Lamp on" 0 "Lamp off" ;
VAL_ 3221225472 ProtectLampStatus 3 "Not available" 2 "Reserved" 1 "Lamp on" 0 "Lamp off" ;
VAL_ 2560949771 FailureModeIdentifier1 31 "Not available" 19 "Received network data in error" 18 "Below normal (moderately severe)" 17 "Below normal (least severe)" 16 "Above normal (moderately severe)" 15 "Above normal (least severe)" 14 "Special intstructions" 13 "Out of calibration" 12 "Bad intelligent device" 11 "Root cause not known" 10 "Abnormal rate of change" 9 "Abnormal update rate" 8 "Abnormal frequency" 7 "Mechanical system not responding" 6 "Current above normal" 5 "Current below normal" 4 "Voltage below normal" 3 "Voltage above normal" 2 "Data erratic" 1 "Below normal (most severe)" 0 "Above normal (most severe)" ;
VAL_ 2560949760 FailureModeIdentifier1 31 "Not available" 19 "Received network data in error" 18 "Below normal (moderately severe)" 17 "Below normal (least severe)" 16 "Above normal (moderately severe)" 15 "Above normal (least severe)" 14 "Special intstructions" 13 "Out of calibration" 12 "Bad intelligent device" 11 "Root cause not known" 10 "Abnormal rate of change" 9 "Abnormal update rate" 8 "Abnormal frequency" 7 "Mechanical system not responding" 6 "Current above normal" 5 "Current below normal" 4 "Voltage below normal" 3 "Voltage above normal" 2 "Data erratic" 1 "Below normal (most severe)" 0 "Above normal (most severe)" ;
VAL_ 2565078782 FailureModeIdentifier1 31 "Not available" 19 "Received network data in error" 18 "Below normal (moderately severe)" 17 "Below normal (least severe)" 16 "Above normal (moderately severe)" 15 "Above normal (least severe)" 14 "Special intstructions" 13 "Out of calibration" 12 "Bad intelligent device" 11 "Root cause not known" 10 "Abnormal rate of change" 9 "Abnormal update rate" 8 "Abnormal frequency" 7 "Mechanical system not responding" 6 "Current above normal" 5 "Current below normal" 4 "Voltage below normal" 3 "Voltage above normal" 2 "Data erratic" 1 "Below normal (most severe)" 0 "Above normal (most severe)" ;
VAL_ 2560950014 FailureModeIdentifier1 31 "Not available" 19 "Received network data in error" 18 "Below normal (moderately severe)" 17 "Below normal (least severe)" 16 "Above normal (moderately severe)" 15 "Above normal (least severe)" 14 "Special intstructions" 13 "Out of calibration" 12 "Bad intelligent device" 11 "Root cause not known" 10 "Abnormal rate of change" 9 "Abnormal update rate" 8 "Abnormal frequency" 7 "Mechanical system not responding" 6 "Current above normal" 5 "Current below normal" 4 "Voltage below normal" 3 "Voltage above normal" 2 "Data erratic" 1 "Below normal (most severe)" 0 "Above normal (most severe)" ;
VAL_ 2348941054 TrnsShftSlctorDisplayModeSwitch 3 "NotAvailable" 2 "Error" 1 "On" 0 "Off" ;
VAL_ 2348941054 TransMode4 3 "TakeNoAction" 2 "Reserved" 1 "Enable" 0 "Disable" ;
VAL_ 2348941054 TransMode3 3 "TakeNoAction" 2 "Reserved" 1 "Enable" 0 "Disable" ;
VAL_ 2348941054 TransMode2 3 "TakeNoAction" 2 "Reserved" 1 "Enable" 0 "Disable" ;
VAL_ 2348941054 TransMode1 3 "TakeNoAction" 2 "Reserved" 1 "Enable" 0 "Disable" ;
VAL_ 2348941054 DisengageDiffLockRqCentralRear 2 "Reserved" 3 "TakeNoAction" 1 "DisengageDiffLock" 0 "EngageDiffLock" ;
VAL_ 2348941054 DisengageDiffLockRqCentralFront 2 "Reserved" 3 "TakeNoAction" 1 "DisengageDiffLock" 0 "EngageDiffLock" ;
VAL_ 2348941054 DisengageDiffLockRqCentral 2 "Reserved" 3 "TakeNoAction" 1 "DisengageDiffLock" 0 "EngageDiffLock" ;
VAL_ 2348941054 DisengageDiffLockRqRearAxle2 2 "Reserved" 3 "TakeNoAction" 1 "DisengageDiffLock" 0 "EngageDiffLock" ;
VAL_ 2348941054 DisengageDiffLockRqRearAxle1 2 "Reserved" 3 "TakeNoAction" 1 "DisengageDiffLock" 0 "EngageDiffLock" ;
VAL_ 2348941054 DisengageDiffLockRqFrontAxle2 2 "Reserved" 3 "TakeNoAction" 1 "DisengageDiffLock" 0 "EngageDiffLock" ;
VAL_ 2348941054 DisengageDiffLockRqFrontAxle1 2 "Reserved" 3 "TakeNoAction" 1 "DisengageDiffLock" 0 "EngageDiffLock" ;
VAL_ 2348941054 TransRqedGear 61 "Reserved" 222 "NeutralSelectorPos" 223 "ReverseSelectorPos" 224 "PsUnknownAnd_OrNoButtonsPressed" 225 "PrssOfMmntryBttnTRslctCrrentPos" 226 "BtwnRvrsAndPrkShiftSelectorPoss" 227 "BtwnNtrlAndRvrsShftSelectorPoss" 228 "BtwnDrvAndNtrlShiftSelectorPoss" 229 "BtwnD1AndDriveShiftSelectorPoss" 230 "BetweenD2AndD1ShiftSelectorPoss" 231 "BetweenD3AndD2ShiftSelectorPoss" 232 "BetweenD4AndD3ShiftSelectorPoss" 233 "BetweenD5AndD4ShiftSelectorPoss" 234 "BetweenD6AndD5ShiftSelectorPoss" 235 "BetweenD7AndD6ShiftSelectorPoss" 236 "BtwnTwoForwardShiftSelectorPoss" 237 "BtwnTwoReverseShiftSelectorPoss" 238 "BetweenTwoShiftSelectorPoss" 239 "D77thFrwrdSlctrPsRfrncdFrmDrive" 240 "D66thFrwrdSlctrPsRfrncdFrmDrive" 241 "D55thFrwrdSlctrPsRfrncdFrmDrive" 242 "D44thFrwrdSlctrPsRfrncdFrmDrive" 243 "D33rdFrwrdSlctrPsRfrncdFrmDrive" 244 "D22ndFrwrdSlctrPsRfrncdFrmDrive" 245 "D11stFrwrdSlctrPsRfrncdFrmDrive" 246 "Downshift2GearsFromCurrentPos" 247 "Downshift1GearFromCurrentPos" 248 "Upshift2GearsFromCurrentPos" 249 "Upshift1GearFromCurrentPos" 250 "ForwardLowPos" 251 "ParkPos" 252 "ForwardDrivePos" 253 "HoldCurrentGear" ;
VAL_ 2348941054 DisengageDrivelineRq 2 "Reserved" 3 "TakeNoAction" 1 "DisengageDriveline" 0 "AllowDrivelineEngagement" ;
VAL_ 2348941054 TorqueConverterLockupDisableRq 2 "Reserved" 3 "TakeNoAction" 1 "DisableTorqueConvertorLockup" 0 "AllowTorqueConvertorLockup" ;
VAL_ 2348941054 TransGearShiftInhibitRq 2 "Reserved" 3 "TakeNoAction" 1 "GearShiftsAreInhibited" 0 "GearShiftsAreAllowed" ;
VAL_ 2562981630 FailureModeIdentifier1 31 "Not available" 19 "Received network data in error" 18 "Below normal (moderately severe)" 17 "Below normal (least severe)" 16 "Above normal (moderately severe)" 15 "Above normal (least severe)" 14 "Special intstructions" 13 "Out of calibration" 12 "Bad intelligent device" 11 "Root cause not known" 10 "Abnormal rate of change" 9 "Abnormal update rate" 8 "Abnormal frequency" 7 "Mechanical system not responding" 6 "Current above normal" 5 "Current below normal" 4 "Voltage below normal" 3 "Voltage above normal" 2 "Data erratic" 1 "Below normal (most severe)" 0 "Above normal (most severe)" ;
VAL_ 2348875518 ControlPurpose 5 "TemporaryPowerTrainControl" 4 "EngineProtection" 3 "RoadSpeedGovernor" 2 "PTOGovernor" 1 "CruiseControl" 0 "AcceleratorPedal" ;
VAL_ 2348875518 TransmissionRate 7 "UseStandardRate" 6 "25ms" 5 "50ms" 4 "100ms" 3 "250ms" 2 "500ms" 1 "750ms" 0 "1000ms" ;
VAL_ 2348875518 OverrideCtrlModePriority 3 "LowPriority" 2 "MdmPrrtyUsdFrPwrtrnCtrlOprtnsWh" 1 "HighPriority" 0 "HghstPrrtyUsdFrSttnsThtRqrImmdt" ;
VAL_ 2348875518 EngRqedSpeedCtrlConditions 2 "ThsCtrlCndtnHsBnOptmzdTMnmzRpmO" 3 "StbltyOptmzdFrDrvlnEnggdAnd_OrI" 1 "StbltyOptmzdFrDrvlnDsnggdAndNnl" 0 "ThsSpdGvrnrGnSlctnIsAdjstdTPrvd" ;
VAL_ 2348875518 EngOverrideCtrlMode 3 "Spd_TrqLmtCtrlLmtSpdAnd_OrTrqBs" 2 "TrqCtrlCntrlTrqTInclddDsrdTrqVl" 1 "SpdCtrlGvrnSpdTInclddDsrdSpdVle" 0 "OvrrdDsbldDsblAnyExstngCtrlCmdd" ;
VAL_ 2348820752 ControlPurpose 5 "TemporaryPowerTrainControl" 4 "EngineProtection" 3 "RoadSpeedGovernor" 2 "PTOGovernor" 1 "CruiseControl" 0 "AcceleratorPedal" ;
VAL_ 2348820752 TransmissionRate 7 "UseStandardRate" 6 "25ms" 5 "50ms" 4 "100ms" 3 "250ms" 2 "500ms" 1 "750ms" 0 "1000ms" ;
VAL_ 2348820752 OverrideCtrlModePriority 3 "LowPriority" 2 "MdmPrrtyUsdFrPwrtrnCtrlOprtnsWh" 1 "HighPriority" 0 "HghstPrrtyUsdFrSttnsThtRqrImmdt" ;
VAL_ 2348820752 EngRqedSpeedCtrlConditions 2 "ThsCtrlCndtnHsBnOptmzdTMnmzRpmO" 3 "StbltyOptmzdFrDrvlnEnggdAnd_OrI" 1 "StbltyOptmzdFrDrvlnDsnggdAndNnl" 0 "ThsSpdGvrnrGnSlctnIsAdjstdTPrvd" ;
VAL_ 2348820752 EngOverrideCtrlMode 3 "Spd_TrqLmtCtrlLmtSpdAnd_OrTrqBs" 2 "TrqCtrlCntrlTrqTInclddDsrdTrqVl" 1 "SpdCtrlGvrnSpdTInclddDsrdSpdVle" 0 "OvrrdDsbldDsblAnyExstngCtrlCmdd" ;
VAL_ 2566840592 RetarderLocation 15 "NotAvailable" 14 "Other" 6 "1101NotDefined" 5 "Trailer" 4 "Driveline" 3 "TransOutput" 2 "TransInput" 1 "EngExhaustBrake" 0 "EngCompressionReleaseBrake" ;
VAL_ 2566840592 RetarderType 15 "NotAvailable" 14 "Other" 5 "1101NotDefined" 4 "Exhaust" 3 "CompressionRelease" 2 "CooledFriction" 1 "Hyd" 0 "Electric_Magnetic" ;
VAL_ 2565865488 EngCoolantLoadIncrease 3 "NotAvailable" 2 "Error" 1 "CoolantLoadIncreasePossible" 0 "NoCoolantLoadIncrease" ;
VAL_ 2565865488 RetarderEnableShiftAssistSwitch 3 "NotAvailable" 2 "Error" 1 "RetarderShiftAssistEnabled" 0 "RetarderShiftAssistDisabled" ;
VAL_ 2565865488 RetarderEnableBrakeAssistSwitch 3 "NotAvailable" 2 "Error" 1 "RetarderBrakeAssistEnabled" 0 "RetarderBrakeAssistDisabled" ;
VAL_ 2348814347 ControlPurpose 5 "TemporaryPowerTrainControl" 4 "EngineProtection" 3 "RoadSpeedGovernor" 2 "PTOGovernor" 1 "CruiseControl" 0 "AcceleratorPedal" ;
VAL_ 2348814347 TransmissionRate 7 "UseStandardRate" 6 "25ms" 5 "50ms" 4 "100ms" 3 "250ms" 2 "500ms" 1 "750ms" 0 "1000ms" ;
VAL_ 2348814347 OverrideCtrlModePriority 3 "LowPriority" 2 "MdmPrrtyUsdFrPwrtrnCtrlOprtnsWh" 1 "HighPriority" 0 "HghstPrrtyUsdFrSttnsThtRqrImmdt" ;
VAL_ 2348814347 EngRqedSpeedCtrlConditions 2 "ThsCtrlCndtnHsBnOptmzdTMnmzRpmO" 3 "StbltyOptmzdFrDrvlnEnggdAnd_OrI" 1 "StbltyOptmzdFrDrvlnDsnggdAndNnl" 0 "ThsSpdGvrnrGnSlctnIsAdjstdTPrvd" ;
VAL_ 2348814347 EngOverrideCtrlMode 3 "Spd_TrqLmtCtrlLmtSpdAnd_OrTrqBs" 2 "TrqCtrlCntrlTrqTInclddDsrdTrqVl" 1 "SpdCtrlGvrnSpdTInclddDsrdSpdVle" 0 "OvrrdDsbldDsblAnyExstngCtrlCmdd" ;
VAL_ 2348810251 ControlPurpose 5 "TemporaryPowerTrainControl" 4 "EngineProtection" 3 "RoadSpeedGovernor" 2 "PTOGovernor" 1 "CruiseControl" 0 "AcceleratorPedal" ;
VAL_ 2348810251 TransmissionRate 7 "UseStandardRate" 6 "25ms" 5 "50ms" 4 "100ms" 3 "250ms" 2 "500ms" 1 "750ms" 0 "1000ms" ;
VAL_ 2348810251 OverrideCtrlModePrio 3 "Low priority" 2 "Medium priority" 1 "High priority" 0 "Highest priority" ;
VAL_ 2348810251 EngRqedSpeedCtrlCond 2 "StabilityOpt_engaged/lockup_cond2" 3 "StabilityOpt_engaged/lockup_cond1" 1 "StabilityOpt_disengaged/non-lockup" 0 "TransientOpt_disengaged/non-lockup" ;
VAL_ 2348810251 EngOverrideCtrlMode 3 "Speed/torque limit control" 2 "Torque control" 1 "Speed control" 0 "Override disabled" ;
VAL_ 2348820739 ControlPurpose 5 "TemporaryPowerTrainControl" 4 "EngineProtection" 3 "RoadSpeedGovernor" 2 "PTOGovernor" 1 "CruiseControl" 0 "AcceleratorPedal" ;
VAL_ 2348820739 TransmissionRate 7 "UseStandardRate" 6 "25ms" 5 "50ms" 4 "100ms" 3 "250ms" 2 "500ms" 1 "750ms" 0 "1000ms" ;
VAL_ 2348820739 OverrideCtrlModePriority 3 "LowPriority" 2 "MdmPrrtyUsdFrPwrtrnCtrlOprtnsWh" 1 "HighPriority" 0 "HghstPrrtyUsdFrSttnsThtRqrImmdt" ;
VAL_ 2348820739 EngRqedSpeedCtrlConditions 2 "ThsCtrlCndtnHsBnOptmzdTMnmzRpmO" 3 "StbltyOptmzdFrDrvlnEnggdAnd_OrI" 1 "StbltyOptmzdFrDrvlnDsnggdAndNnl" 0 "ThsSpdGvrnrGnSlctnIsAdjstdTPrvd" ;
VAL_ 2348820739 EngOverrideCtrlMode 3 "Spd_TrqLmtCtrlLmtSpdAnd_OrTrqBs" 2 "TrqCtrlCntrlTrqTInclddDsrdTrqVl" 1 "SpdCtrlGvrnSpdTInclddDsrdSpdVle" 0 "OvrrdDsbldDsblAnyExstngCtrlCmdd" ;
VAL_ 2348820747 ControlPurpose 5 "TemporaryPowerTrainControl" 4 "EngineProtection" 3 "RoadSpeedGovernor" 2 "PTOGovernor" 1 "CruiseControl" 0 "AcceleratorPedal" ;
VAL_ 2348820747 TransmissionRate 7 "UseStandardRate" 6 "25ms" 5 "50ms" 4 "100ms" 3 "250ms" 2 "500ms" 1 "750ms" 0 "1000ms" ;
VAL_ 2348820747 OverrideCtrlModePriority 3 "LowPriority" 2 "MdmPrrtyUsdFrPwrtrnCtrlOprtnsWh" 1 "HighPriority" 0 "HghstPrrtyUsdFrSttnsThtRqrImmdt" ;
VAL_ 2348820747 EngRqedSpeedCtrlConditions 2 "ThsCtrlCndtnHsBnOptmzdTMnmzRpmO" 3 "StbltyOptmzdFrDrvlnEnggdAnd_OrI" 1 "StbltyOptmzdFrDrvlnDsnggdAndNnl" 0 "ThsSpdGvrnrGnSlctnIsAdjstdTPrvd" ;
VAL_ 2348820747 EngOverrideCtrlMode 3 "Spd_TrqLmtCtrlLmtSpdAnd_OrTrqBs" 2 "TrqCtrlCntrlTrqTInclddDsrdTrqVl" 1 "SpdCtrlGvrnSpdTInclddDsrdSpdVle" 0 "OvrrdDsbldDsblAnyExstngCtrlCmdd" ;
VAL_ 2348810243 ControlPurpose 5 "TemporaryPowerTrainControl" 4 "EngineProtection" 3 "RoadSpeedGovernor" 2 "PTOGovernor" 1 "CruiseControl" 0 "AcceleratorPedal" ;
VAL_ 2348810243 TransmissionRate 7 "UseStandardRate" 6 "25ms" 5 "50ms" 4 "100ms" 3 "250ms" 2 "500ms" 1 "750ms" 0 "1000ms" ;
VAL_ 2348810243 OverrideCtrlModePrio 3 "Low priority" 2 "Medium priority" 1 "High priority" 0 "Highest priority" ;
VAL_ 2348810243 EngRqedSpeedCtrlCond 2 "StabilityOpt_engaged/lockup_cond2" 3 "StabilityOpt_engaged/lockup_cond1" 1 "StabilityOpt_disengaged/non-lockup" 0 "TransientOpt_disengaged/non-lockup" ;
VAL_ 2348810243 EngOverrideCtrlMode 3 "Speed/torque limit control" 2 "Torque control" 1 "Speed control" 0 "Override disabled" ;
VAL_ 2565867787 SteerWheelAngleSensorType 3 "NotAvailable" 2 "Reserved" 1 "AbsMeasuringPrinciple" 0 "RelativeMeasuringPrinciple" ;
VAL_ 2566803211 YCBrakeCtrlActive 3 "DontCare_TakeNoAction" 2 "Reserved" 1 "YCBrakeCtrlActive" 0 "YCBrakeCtrlPassiveButInstalled" ;
VAL_ 2566803211 YCEngCtrlActive 3 "DontCare_TakeNoAction" 2 "Reserved" 1 "YCEngCtrlActive" 0 "YCEngCtrlPassiveButInstalled" ;
VAL_ 2566803211 ROPBrakeCtrlActive 3 "DontCare_TakeNoAction" 2 "Reserved" 1 "ROPBrakeCtrlActive" 0 "ROPBrakeCtrlPassiveButInstalled" ;
VAL_ 2566803211 ROPEngCtrlActive 3 "DontCare_TakeNoAction" 2 "Reserved" 1 "ROPEngCtrlActive" 0 "ROPEngCtrlPassiveButInstalled" ;
VAL_ 2566803211 VDCBrakeLightRq 3 "DontCare_TakeNoAction" 2 "Reserved" 1 "TurnBrakeLightOn" 0 "TurnBrakeLightNotOn" ;
VAL_ 2566803211 VDCFullyOperational 3 "DontCare_TakeNoAction" 2 "Reserved" 1 "FullyOperational" 0 "NotFullyOperational" ;
VAL_ 2566803211 VDCInformationSignal 3 "DontCare_TakeNoAction" 2 "Reserved" 1 "On" 0 "Off" ;
VAL_ 2566845491 TirePressThresholdDetection_21 7 "NotAvailable" 6 "ErrorIndicator" 5 "NotDefined" 4 "ExtrmUndrPrssTrPrssrIsAtALvlWhr" 3 "UndrPrssTrPrssrIsLwrThnThPrssrD" 2 "NWrnngPrssTrPrssrIsWthnThThrshl" 1 "OvrPrssTrPrssrIsHghrThnThPrssrD" 0 "ExtrmOvrPrssTrPrssrIsAtALvlWhrT" ;
VAL_ 2566845491 TirePressThresholdDetection_20 7 "NotAvailable" 6 "ErrorIndicator" 5 "NotDefined" 4 "ExtrmUndrPrssTrPrssrIsAtALvlWhr" 3 "UndrPrssTrPrssrIsLwrThnThPrssrD" 2 "NWrnngPrssTrPrssrIsWthnThThrshl" 1 "OvrPrssTrPrssrIsHghrThnThPrssrD" 0 "ExtrmOvrPrssTrPrssrIsAtALvlWhrT" ;
VAL_ 2566845491 TirePressThresholdDetection_11 7 "NotAvailable" 6 "ErrorIndicator" 5 "NotDefined" 4 "ExtrmUndrPrssTrPrssrIsAtALvlWhr" 3 "UndrPrssTrPrssrIsLwrThnThPrssrD" 2 "NWrnngPrssTrPrssrIsWthnThThrshl" 1 "OvrPrssTrPrssrIsHghrThnThPrssrD" 0 "ExtrmOvrPrssTrPrssrIsAtALvlWhrT" ;
VAL_ 2566845491 TirePressThresholdDetection_10 7 "NotAvailable" 6 "ErrorIndicator" 5 "NotDefined" 4 "ExtrmUndrPrssTrPrssrIsAtALvlWhr" 3 "UndrPrssTrPrssrIsLwrThnThPrssrD" 2 "NWrnngPrssTrPrssrIsWthnThThrshl" 1 "OvrPrssTrPrssrIsHghrThnThPrssrD" 0 "ExtrmOvrPrssTrPrssrIsAtALvlWhrT" ;
VAL_ 2566845491 TirePressThresholdDetection_01 7 "NotAvailable" 6 "ErrorIndicator" 5 "NotDefined" 4 "ExtrmUndrPrssTrPrssrIsAtALvlWhr" 3 "UndrPrssTrPrssrIsLwrThnThPrssrD" 2 "NWrnngPrssTrPrssrIsWthnThThrshl" 1 "OvrPrssTrPrssrIsHghrThnThPrssrD" 0 "ExtrmOvrPrssTrPrssrIsAtALvlWhrT" ;
VAL_ 2566845491 TirePressThresholdDetection_00 7 "NotAvailable" 6 "ErrorIndicator" 5 "NotDefined" 4 "ExtrmUndrPrssTrPrssrIsAtALvlWhr" 3 "UndrPrssTrPrssrIsLwrThnThPrssrD" 2 "NWrnngPrssTrPrssrIsWthnThThrshl" 1 "OvrPrssTrPrssrIsHghrThnThPrssrD" 0 "ExtrmOvrPrssTrPrssrIsAtALvlWhrT" ;
VAL_ 2566845491 CTIWheelSensorStatus_21 3 "NotSupported" 2 "NotDefined" 1 "On" 0 "Off_IsolatedFromCTIPressCtrl" ;
VAL_ 2566845491 CTIWheelSensorStatus_20 3 "NotSupported" 2 "NotDefined" 1 "On" 0 "Off_IsolatedFromCTIPressCtrl" ;
VAL_ 2566845491 CTIWheelSensorStatus_11 3 "NotSupported" 2 "NotDefined" 1 "On" 0 "Off_IsolatedFromCTIPressCtrl" ;
VAL_ 2566845491 CTIWheelSensorStatus_10 3 "NotSupported" 2 "NotDefined" 1 "On" 0 "Off_IsolatedFromCTIPressCtrl" ;
VAL_ 2566845491 CTIWheelSensorStatus_01 3 "NotSupported" 2 "NotDefined" 1 "On" 0 "Off_IsolatedFromCTIPressCtrl" ;
VAL_ 2566845491 CTIWheelSensorStatus_00 3 "NotSupported" 2 "NotDefined" 1 "On" 0 "Off_IsolatedFromCTIPressCtrl" ;
VAL_ 2566845491 CTIWheelEndElectricalFault_21 3 "NotSupported" 2 "Error" 1 "NotDefined" 0 "Ok" ;
VAL_ 2566845491 CTIWheelEndElectricalFault_20 3 "NotSupported" 2 "Error" 1 "NotDefined" 0 "Ok" ;
VAL_ 2566845491 CTIWheelEndElectricalFault_11 3 "NotSupported" 2 "Error" 1 "NotDefined" 0 "Ok" ;
VAL_ 2566845491 CTIWheelEndElectricalFault_10 3 "NotSupported" 2 "Error" 1 "NotDefined" 0 "Ok" ;
VAL_ 2566845491 CTIWheelEndElectricalFault_01 3 "NotSupported" 2 "Error" 1 "NotDefined" 0 "Ok" ;
VAL_ 2566845491 CTIWheelEndElectricalFault_00 3 "NotSupported" 2 "Error" 1 "NotDefined" 0 "Ok" ;
VAL_ 2566845491 CTITireStatus_21 3 "NotSupported" 2 "Error" 1 "TireLeakDetected" 0 "Ok" ;
VAL_ 2566845491 CTITireStatus_20 3 "NotSupported" 2 "Error" 1 "TireLeakDetected" 0 "Ok" ;
VAL_ 2566845491 CTITireStatus_11 3 "NotSupported" 2 "Error" 1 "TireLeakDetected" 0 "Ok" ;
VAL_ 2566845491 CTITireStatus_10 3 "NotSupported" 2 "Error" 1 "TireLeakDetected" 0 "Ok" ;
VAL_ 2566845491 CTITireStatus_01 3 "NotSupported" 2 "Error" 1 "TireLeakDetected" 0 "Ok" ;
VAL_ 2566845491 CTITireStatus_00 3 "NotSupported" 2 "Error" 1 "TireLeakDetected" 0 "Ok" ;
VAL_ 2566845491 TireLocation 33 "Axle2_Position1" 32 "Axle2_Position0" 17 "Axle1_Position1" 16 "Axle1_Position0" 1 "Axle0_Position1" 0 "Axle0_Position0" ;
VAL_ 2365484270 DirectionIndicator 3 "NotAvailable" 2 "Error" 1 "Reverse" 0 "Forward" ;
VAL_ 2365484270 TachographPerformance 3 "NotAvailable" 2 "Error" 1 "PerformanceAnalysis" 0 "NormalPerformance" ;
VAL_ 2365484270 HandlingInformation 3 "NotAvailable" 2 "Error" 1 "HandlingInformation" 0 "NoHandlingInformation" ;
VAL_ 2365484270 SystemEvent 3 "NotAvailable" 2 "Error" 1 "TachographEvent" 0 "NoTachographEvent" ;
VAL_ 2365484270 DriverCardDriver2 3 "NotAvailable" 2 "Error" 1 "DriverCardPresent" 0 "DriverCardNotPresent" ;
VAL_ 2365484270 Driver2TimeRelatedStates 15 "NotAvailable" 14 "Error" 13 "Other" 7 "1100Reserved" 6 "Limit616HReached" 5 "Limit515MinBefore16H" 4 "Limit49HReached" 3 "Limit315MinBefore9H" 2 "Limit24HReached" 1 "Limit115MinBefore4H" 0 "Normal_NoLimitsReached" ;
VAL_ 2365484270 Overspeed 3 "NotAvailable" 2 "Error" 1 "Overspeed" 0 "NoOverspeed" ;
VAL_ 2365484270 DriverCardDriver1 3 "NotAvailable" 2 "Error" 1 "DriverCardPresent" 0 "DriverCardNotPresent" ;
VAL_ 2365484270 Driver1TimeRelatedStates 15 "NotAvailable" 14 "Error" 13 "Other" 7 "1100Reserved" 6 "Limit616HReached" 5 "Limit515MinBefore16H" 4 "Limit49HReached" 3 "Limit315MinBefore9H" 2 "Limit24HReached" 1 "Limit115MinBefore4H" 0 "Normal_NoLimitsReached" ;
VAL_ 2365484270 DriveRecognize 3 "NotAvailable" 2 "Error" 1 "VehicleMotionDetected" 0 "VehicleMotionNotDetected" ;
VAL_ 2365484270 Driver2WorkingState 7 "NotAvailable" 6 "Error" 4 "101Reserved" 3 "DriveBehindWheel" 2 "WrkLdngUnldingWorkingInAnOffice" 1 "DriverAvailableShortBreak" 0 "RestSleeping" ;
VAL_ 2365484270 Driver1WorkingState 7 "NotAvailable" 6 "Error" 4 "101Reserved" 3 "DriveBehindWheel" 2 "WrkLdngUnldingWorkingInAnOffice" 1 "DriverAvailableShortBreak" 0 "RestSleeping" ;
VAL_ 2566841344 EngOverspeedTest 3 "NotAvailable" 2 "Reserved" 1 "EngOverspeedTestActive" 0 "EngOverspeedTestNotActive" ;
VAL_ 2566841344 EngAirShutoffCmdStatus 0 "ArShtffDsbldNtAttmptngTShtffEng" 3 "NotAvailable" 2 "Reserved" 1 "ArShtffEnbldAttmptngTShtffEngAr" ;
VAL_ 2566841344 EngAlarmOutputCmdStatus 3 "NotAvailable" 2 "Reserved" 1 "EngAlarmOutputCmdActive" 0 "EngAlarmOutputCmdNotActive" ;
VAL_ 2566841344 EngAlarmAcknowledge 3 "NotAvailable" 2 "Error" 1 "EngAlarmAcknowledgeActive" 0 "EngAlarmAcknowledgeNotActive" ;
VAL_ 2566841344 EngProtectionSystemConfig 3 "NotAvailable" 2 "Error" 1 "EnabledInCalib" 0 "DisabledInCalib" ;
VAL_ 2566841344 EngProtectionSystemTimerState 3 "NotAvailable" 2 "Error" 1 "Active" 0 "Inactive" ;
VAL_ 2566841344 EngPrtectionSystemTimerOverride 3 "NotAvailable" 2 "Error" 1 "Active" 0 "Inactive" ;
VAL_ 2566841344 EngPrtctnSystmApprchingShutdown 3 "NotAvailable" 2 "Error" 1 "Approaching" 0 "NotApproaching" ;
VAL_ 2566841344 EngPrtctionSystemHasShutdownEng 0 "No" ;
VAL_ 2566841344 EngWaitToStartLamp 3 "NotAvailable" 2 "Error" 1 "On" 0 "Off" ;
VAL_ 2566841344 RefrigerantHighPressSwitch 3 "NotAvailable" 2 "Error" 1 "PrssTHghCmprssrCltchMyBDsngaged" 0 "PressNormal" ;
VAL_ 2566841344 RefrigerantLowPressSwitch 3 "NotAvailable" 2 "Error" 1 "PrssTLwCmprssrCltchMyBDsengaged" 0 "PressNormal" ;
VAL_ 2566841344 A_CHighPressFanSwitch 3 "NotAvailable" 2 "Error" 1 "PressHighFanMayBeEngaged" 0 "PressNormal" ;
VAL_ 2566841344 EngIdleShutdownTimerFunction 3 "NotAvailable" 2 "Error" 1 "EnabledInCalib" 0 "DisabledInCalib" ;
VAL_ 2566841344 EngIdleShutdownTimerState 3 "NotAvailable" 2 "Error" 1 "Active" 0 "Inactive" ;
VAL_ 2566841344 EngIdleShutdownTimerOverride 3 "NotAvailable" 2 "Error" 1 "Active" 0 "Inactive" ;
VAL_ 2566841344 EngIdleShutdownDriverAlertMode 3 "NotAvailable" 2 "Error" 1 "Active" 0 "Inactive" ;
VAL_ 2566841344 EngIdleShutdownHasShutdownEng 1 "Yes" 0 "No" ;
VAL_ 2631855639 EngBuildHoursReset 2 "Reserved" 3 "TakeNoAction" 1 "Reset" 0 "DoNotReset" ;
VAL_ 2631855639 TripGroup2Proprietary 2 "Reserved" 3 "NotApplicable" 1 "Reset" 0 "TakeNoAction" ;
VAL_ 2631855639 TripGroup1 2 "Reserved" 3 "NotApplicable" 1 "Reset" 0 "TakeNoAction" ;
VAL_ 2566840617 RetarderLocation 15 "NotAvailable" 14 "Other" 6 "1101NotDefined" 5 "Trailer" 4 "Driveline" 3 "TransOutput" 2 "TransInput" 1 "EngExhaustBrake" 0 "EngCompressionReleaseBrake" ;
VAL_ 2566840617 RetarderType 15 "NotAvailable" 14 "Other" 5 "1101NotDefined" 4 "Exhaust" 3 "CompressionRelease" 2 "CooledFriction" 1 "Hyd" 0 "Electric_Magnetic" ;
VAL_ 2566844416 OperatorPTOMemorySelectSwitch 3 "notAvailable" 2 "error" 1 "PTOSetSpeedMemory2Selected" 0 "PTOSetSpeedMemory1Selected" ;
VAL_ 2566844416 EngPTOAccelerateSwitch 3 "NotAvailable" 2 "Error" 1 "On" 0 "Off" ;
VAL_ 2566844416 EngPTOResumeSwitch 3 "NotAvailable" 2 "Error" 1 "On" 0 "Off" ;
VAL_ 2566844416 EngPTOCoast_DecelerateSwitch 3 "NotAvailable" 2 "Error" 1 "On" 0 "Off" ;
VAL_ 2566844416 EngPTOSetSwitch 3 "NotAvailable" 2 "Error" 1 "On" 0 "Off" ;
VAL_ 2566844416 EngRmtPTOVriableSpeedCtrlSwitch 3 "NotAvailable" 2 "Error" 1 "On" 0 "Off" ;
VAL_ 2566844416 EngRmtPTOPrprgrmmdSpdCtrlSwitch 3 "NotAvailable" 2 "Error" 1 "On" 0 "Off" ;
VAL_ 2566844416 EngPTOEnableSwitch 3 "NotAvailable" 2 "Error" 1 "On" 0 "Off" ;
VAL_ 2566844416 RmtPTOPrprgrmmdSpeedCtrlSwitch2 3 "NotAvailable" 2 "Error" 1 "On" 0 "Off" ;
VAL_ 2566844416 AuxInputIgnoreSwitch 3 "NotAvailable" 2 "Error" 1 "On" 0 "Off" ;
VAL_ 2566831360 FanDriveState 15 "NotAvailable" 14 "Other" 13 "EngBrake" 12 "Timer" 11 "A_CSystem" 10 "TransRetarder" 9 "ManualCtrl" 8 "NotDefined" 7 "DefaultOperation" 6 "ExcessiveHydOilTemp" 5 "ExcessiveTransOilTemp" 4 "ExcessiveEngCoolantTemp" 3 "ExcessiveEngOilTemp" 2 "ExcessiveEngAirTemp" 1 "EngSystemGeneral" 0 "FanOff" ;
